VERSION "created by canmatrix"

NS_ :

BS_:

BU_:

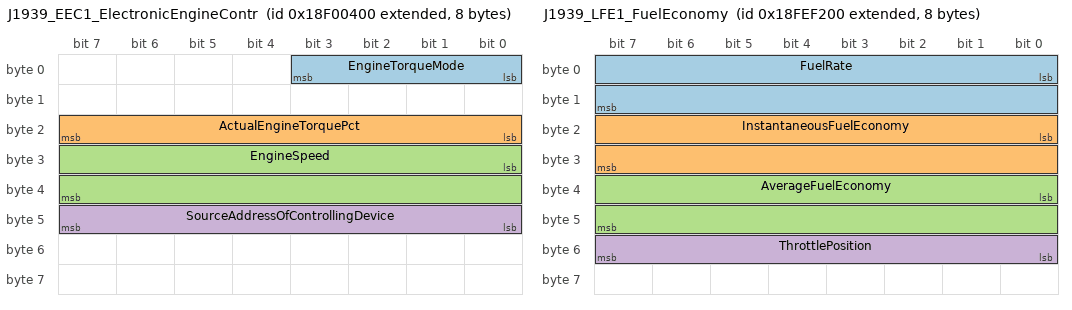
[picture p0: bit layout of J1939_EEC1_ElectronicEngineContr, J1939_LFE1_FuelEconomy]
BO_ 2565866496 J1939_EEC1_ElectronicEngineContr: 8 Vector__XXX
 SG_ EngineTorqueMode : 0|4@1+ (1,0) [0|15] "" Vector__XXX
 SG_ ActualEngineTorquePct : 16|8@1+ (1,-125) [-125|130] "%" Vector__XXX
 SG_ EngineSpeed : 24|16@1+ (0.125,0) [0|8191.875] "rpm" Vector__XXX
 SG_ SourceAddressOfControllingDevice : 40|8@1+ (1,0) [0|255] "" Vector__XXX

BO_ 2566844928 J1939_LFE1_FuelEconomy: 8 Vector__XXX
 SG_ FuelRate : 0|16@1+ (0.05,0) [0|3276.75] "L/h" Vector__XXX
 SG_ InstantaneousFuelEconomy : 16|16@1+ (0.001953,0) [0|127.989855] "km/L" Vector__XXX
 SG_ AverageFuelEconomy : 32|16@1+ (0.001953,0) [0|127.989855] "km/L" Vector__XXX
 SG_ ThrottlePosition : 48|8@1+ (0.4,0) [0|102] "%" Vector__XXX

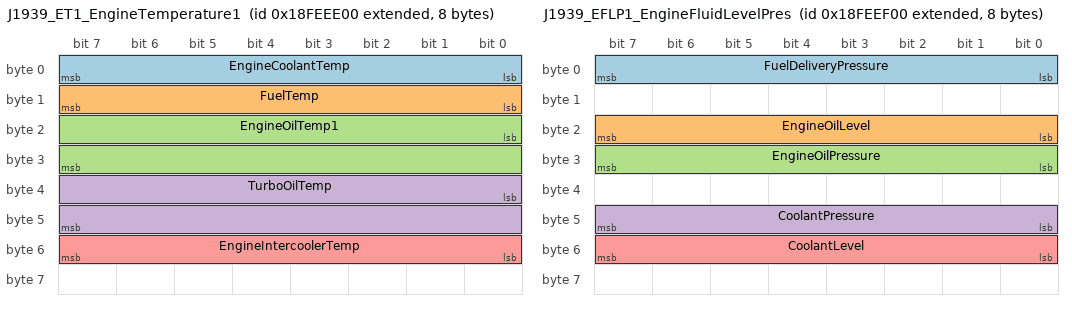
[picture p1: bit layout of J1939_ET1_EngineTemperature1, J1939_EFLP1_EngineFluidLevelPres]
BO_ 2566843904 J1939_ET1_EngineTemperature1: 8 Vector__XXX
 SG_ EngineCoolantTemp : 0|8@1+ (1,-40) [-40|215] "°C" Vector__XXX
 SG_ FuelTemp : 8|8@1+ (1,-40) [-40|215] "°C" Vector__XXX
 SG_ EngineOilTemp1 : 16|16@1+ (0.03125,-273) [-273|1774.96875] "°C" Vector__XXX
 SG_ TurboOilTemp : 32|16@1+ (0.03125,-273) [-273|1774.96875] "°C" Vector__XXX
 SG_ EngineIntercoolerTemp : 48|8@1+ (1,-40) [-40|215] "°C" Vector__XXX

BO_ 2566844160 J1939_EFLP1_EngineFluidLevelPres: 8 Vector__XXX
 SG_ FuelDeliveryPressure : 0|8@1+ (4,0) [0|1020] "kPa" Vector__XXX
 SG_ EngineOilLevel : 16|8@1+ (0.4,0) [0|102] "%" Vector__XXX
 SG_ EngineOilPressure : 24|8@1+ (4,0) [0|1020] "kPa" Vector__XXX
 SG_ CoolantPressure : 40|8@1+ (2,0) [0|510] "kPa" Vector__XXX
 SG_ CoolantLevel : 48|8@1+ (0.4,0) [0|102] "%" Vector__XXX

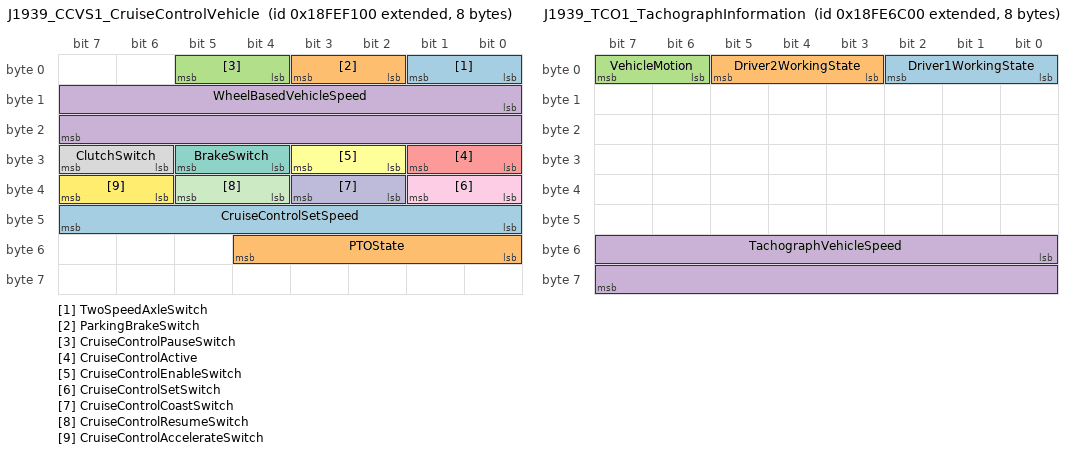
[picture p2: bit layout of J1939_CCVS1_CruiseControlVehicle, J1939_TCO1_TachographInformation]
BO_ 2566844672 J1939_CCVS1_CruiseControlVehicle: 8 Vector__XXX
 SG_ TwoSpeedAxleSwitch : 0|2@1+ (1,0) [0|3] "" Vector__XXX
 SG_ ParkingBrakeSwitch : 2|2@1+ (1,0) [0|3] "" Vector__XXX
 SG_ CruiseControlPauseSwitch : 4|2@1+ (1,0) [0|3] "" Vector__XXX
 SG_ WheelBasedVehicleSpeed : 8|16@1+ (0.003906,0) [0|255.97971] "km/h" Vector__XXX
 SG_ CruiseControlActive : 24|2@1+ (1,0) [0|3] "" Vector__XXX
 SG_ CruiseControlEnableSwitch : 26|2@1+ (1,0) [0|3] "" Vector__XXX
 SG_ BrakeSwitch : 28|2@1+ (1,0) [0|3] "" Vector__XXX
 SG_ ClutchSwitch : 30|2@1+ (1,0) [0|3] "" Vector__XXX
 SG_ CruiseControlSetSwitch : 32|2@1+ (1,0) [0|3] "" Vector__XXX
 SG_ CruiseControlCoastSwitch : 34|2@1+ (1,0) [0|3] "" Vector__XXX
 SG_ CruiseControlResumeSwitch : 36|2@1+ (1,0) [0|3] "" Vector__XXX
 SG_ CruiseControlAccelerateSwitch : 38|2@1+ (1,0) [0|3] "" Vector__XXX
 SG_ CruiseControlSetSpeed : 40|8@1+ (1,0) [0|255] "km/h" Vector__XXX
 SG_ PTOState : 48|5@1+ (1,0) [0|31] "" Vector__XXX

BO_ 2566810624 J1939_TCO1_TachographInformation: 8 Vector__XXX
 SG_ Driver1WorkingState : 0|3@1+ (1,0) [0|7] "" Vector__XXX
 SG_ Driver2WorkingState : 3|3@1+ (1,0) [0|7] "" Vector__XXX
 SG_ VehicleMotion : 6|2@1+ (1,0) [0|3] "" Vector__XXX
 SG_ TachographVehicleSpeed : 48|16@1+ (0.003906,0) [0|255.97971] "km/h" Vector__XXX

BO_ 2566841600 J1939_HOURS_EngineHours: 8 Vector__XXX
 SG_ EngineTotalHoursOfOperation : 0|32@1+ (0.05,0) [0|214748364.75] "h" Vector__XXX
 SG_ EngineTotalRevolutions : 32|32@1+ (1000,0) [0|4294967295000] "r" Vector__XXX

BO_ 2566843392 J1939_VI_VehicleIdentification: 8 Vector__XXX
 SG_ VIN_Char01 : 0|8@1+ (1,0) [0|255] "" Vector__XXX

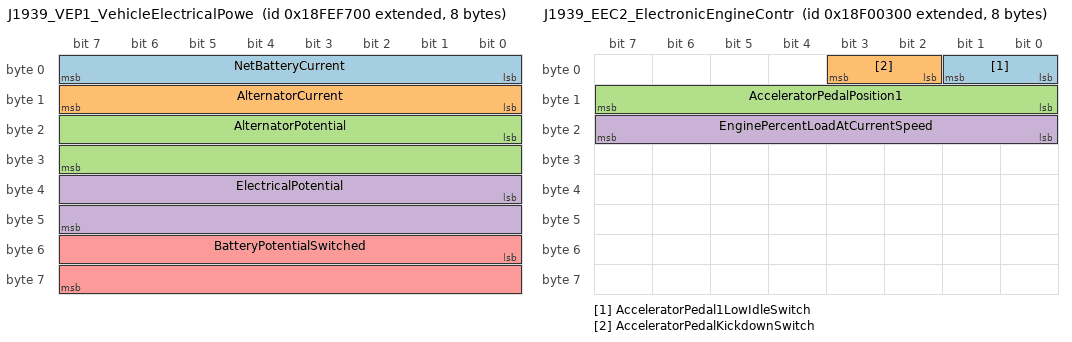
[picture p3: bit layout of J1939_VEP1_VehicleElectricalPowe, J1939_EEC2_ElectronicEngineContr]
BO_ 2566846208 J1939_VEP1_VehicleElectricalPowe: 8 Vector__XXX
 SG_ NetBatteryCurrent : 0|8@1+ (1,-125) [-125|130] "A" Vector__XXX
 SG_ AlternatorCurrent : 8|8@1+ (1,0) [0|255] "A" Vector__XXX
 SG_ AlternatorPotential : 16|16@1+ (0.05,0) [0|3276.75] "V" Vector__XXX
 SG_ ElectricalPotential : 32|16@1+ (0.05,0) [0|3276.75] "V" Vector__XXX
 SG_ BatteryPotentialSwitched : 48|16@1+ (0.05,0) [0|3276.75] "V" Vector__XXX

BO_ 2566749184 J1939_DEF_DieselExhaustFluidConc: 8 Vector__XXX
 SG_ DEFTankLevel : 0|8@1+ (0.4,0) [0|102] "%" Vector__XXX
 SG_ DEFTankTemperature : 8|8@1+ (1,-40) [-40|215] "°C" Vector__XXX

BO_ 2566841088 J1939_EC1_EngineConfiguration1: 8 Vector__XXX
 SG_ EngineSpeedAtIdle : 0|16@1+ (0.125,0) [0|8191.875] "rpm" Vector__XXX
 SG_ EngineSpeedAtMaxIdlePoint1 : 24|16@1+ (0.125,0) [0|8191.875] "rpm" Vector__XXX

BO_ 2566840064 J1939_EEC3_ElectronicEngineContr: 8 Vector__XXX
 SG_ EngineDemandPercentTorque : 56|8@1+ (1,-125) [-125|130] "%" Vector__XXX

BO_ 2565866240 J1939_EEC2_ElectronicEngineContr: 8 Vector__XXX
 SG_ AcceleratorPedal1LowIdleSwitch : 0|2@1+ (1,0) [0|3] "" Vector__XXX
 SG_ AcceleratorPedalKickdownSwitch : 2|2@1+ (1,0) [0|3] "" Vector__XXX
 SG_ AcceleratorPedalPosition1 : 8|8@1+ (0.4,0) [0|102] "%" Vector__XXX
 SG_ EnginePercentLoadAtCurrentSpeed : 16|8@1+ (1,0) [0|255] "%" Vector__XXX

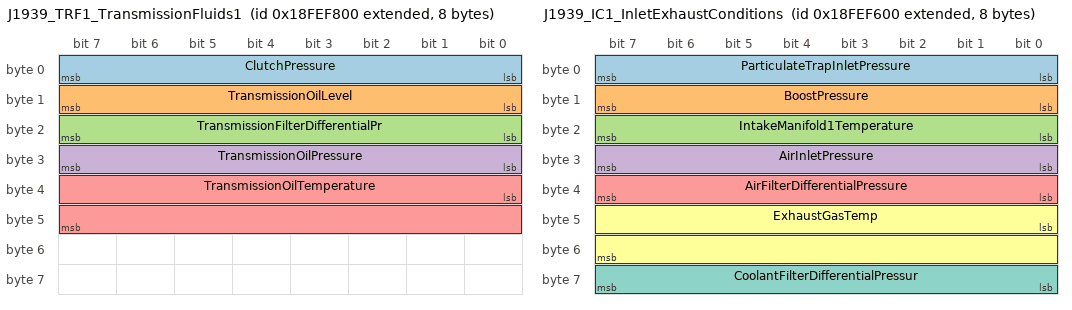
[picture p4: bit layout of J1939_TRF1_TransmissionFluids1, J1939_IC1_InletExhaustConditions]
BO_ 2566846464 J1939_TRF1_TransmissionFluids1: 8 Vector__XXX
 SG_ ClutchPressure : 0|8@1+ (16,0) [0|4080] "kPa" Vector__XXX
 SG_ TransmissionOilLevel : 8|8@1+ (0.4,0) [0|102] "%" Vector__XXX
 SG_ TransmissionFilterDifferentialPr : 16|8@1+ (2,0) [0|510] "kPa" Vector__XXX
 SG_ TransmissionOilPressure : 24|8@1+ (16,0) [0|4080] "kPa" Vector__XXX
 SG_ TransmissionOilTemperature : 32|16@1+ (0.03125,-273) [-273|1774.96875] "°C" Vector__XXX

BO_ 2566845952 J1939_IC1_InletExhaustConditions: 8 Vector__XXX
 SG_ ParticulateTrapInletPressure : 0|8@1+ (0.5,0) [0|127.5] "kPa" Vector__XXX
 SG_ BoostPressure : 8|8@1+ (2,0) [0|510] "kPa" Vector__XXX
 SG_ IntakeManifold1Temperature : 16|8@1+ (1,-40) [-40|215] "°C" Vector__XXX
 SG_ AirInletPressure : 24|8@1+ (2,0) [0|510] "kPa" Vector__XXX
 SG_ AirFilterDifferentialPressure : 32|8@1+ (0.05,0) [0|12.75] "kPa" Vector__XXX
 SG_ ExhaustGasTemp : 40|16@1+ (0.03125,-273) [-273|1774.96875] "°C" Vector__XXX
 SG_ CoolantFilterDifferentialPressur : 56|8@1+ (0.5,0) [0|127.5] "kPa" Vector__XXX

BO_ 2566697472 J1939_FFE_FuelEconomyExtended: 8 Vector__XXX
 SG_ EngineTripFuel : 0|32@1+ (0.5,0) [0|2147483647.5] "L" Vector__XXX
 SG_ EngineTotalFuelUsed : 32|32@1+ (0.5,0) [0|2147483647.5] "L" Vector__XXX

BO_ 2566832384 J1939_HRVD_HighResolutionVehicle: 8 Vector__XXX
 SG_ HighResolutionTotalVehicleDistan : 0|32@1+ (5,0) [0|21474836475] "m" Vector__XXX
 SG_ HighResolutionTripDistance : 32|32@1+ (5,0) [0|21474836475] "m" Vector__XXX

CM_ BO_ 2565866496  "Engine speed, torque mode, demand torque. Source: Wikipedia SAE J1939 PGN list (en.wikipedia.org/wiki/SAE_J1939)";
CM_ BO_ 2566844928  "Fuel rate + instantaneous + average fuel economy. Source: Wikipedia SAE J1939 PGN list (en.wikipedia.org/wiki/SAE_J1939)";
CM_ BO_ 2566843904  "Coolant + fuel + engine oil + intercooler temperatures. Source: Wikipedia SAE J1939 PGN list (en.wikipedia.org/wiki/SAE_J1939)";
CM_ BO_ 2566844160  "Oil pressure/level + coolant pressure/level + fuel delivery pressure. Source: Wikipedia SAE J1939 PGN list (en.wikipedia.org/wiki/SAE_J1939)";
CM_ BO_ 2566844672  "Vehicle speed + cruise control state + brake/clutch/parking switches. Source: Wikipedia SAE J1939 PGN list (en.wikipedia.org/wiki/SAE_J1939)";
CM_ BO_ 2566810624  "Tachograph + driver state (mostly for heavy-truck FMS). Source: Wikipedia SAE J1939 PGN list (en.wikipedia.org/wiki/SAE_J1939)";
CM_ BO_ 2566841600  "Engine total hours of operation. Source: Wikipedia SAE J1939 PGN list (en.wikipedia.org/wiki/SAE_J1939)";
CM_ BO_ 2566843392  "Vehicle Identification Number (VIN). Source: Wikipedia SAE J1939 PGN list (en.wikipedia.org/wiki/SAE_J1939)";
CM_ BO_ 2566846208  "Battery + alternator + engine starter electrical state. Source: Wikipedia SAE J1939 PGN list (en.wikipedia.org/wiki/SAE_J1939)";
CM_ BO_ 2566749184  "DEF (urea) tank level + temperature + concentration. Source: Wikipedia SAE J1939 PGN list (en.wikipedia.org/wiki/SAE_J1939)";
CM_ BO_ 2566841088  "Engine configuration data — displacement, speed limits, fuel type. Source: Wikipedia SAE J1939 PGN list (en.wikipedia.org/wiki/SAE_J1939)";
CM_ BO_ 2566840064  "Engine demand percent torque + nominal friction torque. Source: Wikipedia SAE J1939 PGN list (en.wikipedia.org/wiki/SAE_J1939)";
CM_ BO_ 2565866240  "Accelerator pedal + percent load. Source: Wikipedia SAE J1939 PGN list (en.wikipedia.org/wiki/SAE_J1939)";
CM_ BO_ 2566846464  "Transmission oil + clutch pressure. Source: Wikipedia SAE J1939 PGN list (en.wikipedia.org/wiki/SAE_J1939)";
CM_ BO_ 2566845952  "Boost + intake air temp + air filter differential pressure. Source: Wikipedia SAE J1939 PGN list (en.wikipedia.org/wiki/SAE_J1939)";
CM_ BO_ 2566697472  "Trip fuel + total fuel + trip distance. Source: Wikipedia SAE J1939 PGN list (en.wikipedia.org/wiki/SAE_J1939)";
CM_ BO_ 2566832384  "High-resolution vehicle distance (HRVD per SAE J1939-71). Source: Wikipedia SAE J1939 PGN list (en.wikipedia.org/wiki/SAE_J1939)";

CM_ SG_ 2565866496 EngineTorqueMode "Per-signal source: Wikipedia SAE J1939 PGN list (en.wikipedia.org/wiki/SAE_J1939)";
CM_ SG_ 2565866496 ActualEngineTorquePct "Actual engine percent torque";
CM_ SG_ 2565866496 EngineSpeed "Per-signal source: Wikipedia SAE J1939 PGN list (en.wikipedia.org/wiki/SAE_J1939)";
CM_ SG_ 2565866496 SourceAddressOfControllingDevice "Source address of the device commanding engine torque";
CM_ SG_ 2566844928 FuelRate "Per-signal source: Wikipedia SAE J1939 PGN list (en.wikipedia.org/wiki/SAE_J1939)";
CM_ SG_ 2566844928 InstantaneousFuelEconomy "Per-signal source: Wikipedia SAE J1939 PGN list (en.wikipedia.org/wiki/SAE_J1939)";
CM_ SG_ 2566844928 AverageFuelEconomy "Per-signal source: Wikipedia SAE J1939 PGN list (en.wikipedia.org/wiki/SAE_J1939)";
CM_ SG_ 2566844928 ThrottlePosition "Per-signal source: Wikipedia SAE J1939 PGN list (en.wikipedia.org/wiki/SAE_J1939)";
CM_ SG_ 2566843904 EngineCoolantTemp "Per-signal source: Wikipedia SAE J1939 PGN list (en.wikipedia.org/wiki/SAE_J1939)";
CM_ SG_ 2566843904 FuelTemp "Per-signal source: Wikipedia SAE J1939 PGN list (en.wikipedia.org/wiki/SAE_J1939)";
CM_ SG_ 2566843904 EngineOilTemp1 "Per-signal source: Wikipedia SAE J1939 PGN list (en.wikipedia.org/wiki/SAE_J1939)";
CM_ SG_ 2566843904 TurboOilTemp "Per-signal source: Wikipedia SAE J1939 PGN list (en.wikipedia.org/wiki/SAE_J1939)";
CM_ SG_ 2566843904 EngineIntercoolerTemp "Per-signal source: Wikipedia SAE J1939 PGN list (en.wikipedia.org/wiki/SAE_J1939)";
CM_ SG_ 2566844160 FuelDeliveryPressure "Per-signal source: Wikipedia SAE J1939 PGN list (en.wikipedia.org/wiki/SAE_J1939)";
CM_ SG_ 2566844160 EngineOilLevel "Per-signal source: Wikipedia SAE J1939 PGN list (en.wikipedia.org/wiki/SAE_J1939)";
CM_ SG_ 2566844160 EngineOilPressure "Per-signal source: Wikipedia SAE J1939 PGN list (en.wikipedia.org/wiki/SAE_J1939)";
CM_ SG_ 2566844160 CoolantPressure "Per-signal source: Wikipedia SAE J1939 PGN list (en.wikipedia.org/wiki/SAE_J1939)";
CM_ SG_ 2566844160 CoolantLevel "Per-signal source: Wikipedia SAE J1939 PGN list (en.wikipedia.org/wiki/SAE_J1939)";
CM_ SG_ 2566844672 TwoSpeedAxleSwitch "Per-signal source: Wikipedia SAE J1939 PGN list (en.wikipedia.org/wiki/SAE_J1939)";
CM_ SG_ 2566844672 ParkingBrakeSwitch "Per-signal source: Wikipedia SAE J1939 PGN list (en.wikipedia.org/wiki/SAE_J1939)";
CM_ SG_ 2566844672 CruiseControlPauseSwitch "Per-signal source: Wikipedia SAE J1939 PGN list (en.wikipedia.org/wiki/SAE_J1939)";
CM_ SG_ 2566844672 WheelBasedVehicleSpeed "Per-signal source: Wikipedia SAE J1939 PGN list (en.wikipedia.org/wiki/SAE_J1939)";
CM_ SG_ 2566844672 CruiseControlActive "Per-signal source: Wikipedia SAE J1939 PGN list (en.wikipedia.org/wiki/SAE_J1939)";
CM_ SG_ 2566844672 CruiseControlEnableSwitch "Per-signal source: Wikipedia SAE J1939 PGN list (en.wikipedia.org/wiki/SAE_J1939)";
CM_ SG_ 2566844672 BrakeSwitch "Per-signal source: Wikipedia SAE J1939 PGN list (en.wikipedia.org/wiki/SAE_J1939)";
CM_ SG_ 2566844672 ClutchSwitch "Per-signal source: Wikipedia SAE J1939 PGN list (en.wikipedia.org/wiki/SAE_J1939)";
CM_ SG_ 2566844672 CruiseControlSetSwitch "Per-signal source: Wikipedia SAE J1939 PGN list (en.wikipedia.org/wiki/SAE_J1939)";
CM_ SG_ 2566844672 CruiseControlCoastSwitch "Per-signal source: Wikipedia SAE J1939 PGN list (en.wikipedia.org/wiki/SAE_J1939)";
CM_ SG_ 2566844672 CruiseControlResumeSwitch "Per-signal source: Wikipedia SAE J1939 PGN list (en.wikipedia.org/wiki/SAE_J1939)";
CM_ SG_ 2566844672 CruiseControlAccelerateSwitch "Per-signal source: Wikipedia SAE J1939 PGN list (en.wikipedia.org/wiki/SAE_J1939)";
CM_ SG_ 2566844672 CruiseControlSetSpeed "Per-signal source: Wikipedia SAE J1939 PGN list (en.wikipedia.org/wiki/SAE_J1939)";
CM_ SG_ 2566844672 PTOState "Per-signal source: Wikipedia SAE J1939 PGN list (en.wikipedia.org/wiki/SAE_J1939)";
CM_ SG_ 2566810624 Driver1WorkingState "Per-signal source: Wikipedia SAE J1939 PGN list (en.wikipedia.org/wiki/SAE_J1939)";
CM_ SG_ 2566810624 Driver2WorkingState "Per-signal source: Wikipedia SAE J1939 PGN list (en.wikipedia.org/wiki/SAE_J1939)";
CM_ SG_ 2566810624 VehicleMotion "Per-signal source: Wikipedia SAE J1939 PGN list (en.wikipedia.org/wiki/SAE_J1939)";
CM_ SG_ 2566810624 TachographVehicleSpeed "Per-signal source: Wikipedia SAE J1939 PGN list (en.wikipedia.org/wiki/SAE_J1939)";
CM_ SG_ 2566841600 EngineTotalHoursOfOperation "Per-signal source: Wikipedia SAE J1939 PGN list (en.wikipedia.org/wiki/SAE_J1939)";
CM_ SG_ 2566841600 EngineTotalRevolutions "Per-signal source: Wikipedia SAE J1939 PGN list (en.wikipedia.org/wiki/SAE_J1939)";
CM_ SG_ 2566843392 VIN_Char01 "ASCII byte 0 of VIN; full VIN spans multipacket";
CM_ SG_ 2566846208 NetBatteryCurrent "Per-signal source: Wikipedia SAE J1939 PGN list (en.wikipedia.org/wiki/SAE_J1939)";
CM_ SG_ 2566846208 AlternatorCurrent "Per-signal source: Wikipedia SAE J1939 PGN list (en.wikipedia.org/wiki/SAE_J1939)";
CM_ SG_ 2566846208 AlternatorPotential "Per-signal source: Wikipedia SAE J1939 PGN list (en.wikipedia.org/wiki/SAE_J1939)";
CM_ SG_ 2566846208 ElectricalPotential "Per-signal source: Wikipedia SAE J1939 PGN list (en.wikipedia.org/wiki/SAE_J1939)";
CM_ SG_ 2566846208 BatteryPotentialSwitched "Per-signal source: Wikipedia SAE J1939 PGN list (en.wikipedia.org/wiki/SAE_J1939)";
CM_ SG_ 2566749184 DEFTankLevel "Per-signal source: Wikipedia SAE J1939 PGN list (en.wikipedia.org/wiki/SAE_J1939)";
CM_ SG_ 2566749184 DEFTankTemperature "Per-signal source: Wikipedia SAE J1939 PGN list (en.wikipedia.org/wiki/SAE_J1939)";
CM_ SG_ 2566841088 EngineSpeedAtIdle "Per-signal source: Wikipedia SAE J1939 PGN list (en.wikipedia.org/wiki/SAE_J1939)";
CM_ SG_ 2566841088 EngineSpeedAtMaxIdlePoint1 "Per-signal source: Wikipedia SAE J1939 PGN list (en.wikipedia.org/wiki/SAE_J1939)";
CM_ SG_ 2566840064 EngineDemandPercentTorque "Per-signal source: Wikipedia SAE J1939 PGN list (en.wikipedia.org/wiki/SAE_J1939)";
CM_ SG_ 2565866240 AcceleratorPedal1LowIdleSwitch "Per-signal source: Wikipedia SAE J1939 PGN list (en.wikipedia.org/wiki/SAE_J1939)";
CM_ SG_ 2565866240 AcceleratorPedalKickdownSwitch "Per-signal source: Wikipedia SAE J1939 PGN list (en.wikipedia.org/wiki/SAE_J1939)";
CM_ SG_ 2565866240 AcceleratorPedalPosition1 "Per-signal source: Wikipedia SAE J1939 PGN list (en.wikipedia.org/wiki/SAE_J1939)";
CM_ SG_ 2565866240 EnginePercentLoadAtCurrentSpeed "Per-signal source: Wikipedia SAE J1939 PGN list (en.wikipedia.org/wiki/SAE_J1939)";
CM_ SG_ 2566846464 ClutchPressure "Per-signal source: Wikipedia SAE J1939 PGN list (en.wikipedia.org/wiki/SAE_J1939)";
CM_ SG_ 2566846464 TransmissionOilLevel "Per-signal source: Wikipedia SAE J1939 PGN list (en.wikipedia.org/wiki/SAE_J1939)";
CM_ SG_ 2566846464 TransmissionFilterDifferentialPr "Per-signal source: Wikipedia SAE J1939 PGN list (en.wikipedia.org/wiki/SAE_J1939)";
CM_ SG_ 2566846464 TransmissionOilPressure "Per-signal source: Wikipedia SAE J1939 PGN list (en.wikipedia.org/wiki/SAE_J1939)";
CM_ SG_ 2566846464 TransmissionOilTemperature "Per-signal source: Wikipedia SAE J1939 PGN list (en.wikipedia.org/wiki/SAE_J1939)";
CM_ SG_ 2566845952 ParticulateTrapInletPressure "Per-signal source: Wikipedia SAE J1939 PGN list (en.wikipedia.org/wiki/SAE_J1939)";
CM_ SG_ 2566845952 BoostPressure "Per-signal source: Wikipedia SAE J1939 PGN list (en.wikipedia.org/wiki/SAE_J1939)";
CM_ SG_ 2566845952 IntakeManifold1Temperature "Per-signal source: Wikipedia SAE J1939 PGN list (en.wikipedia.org/wiki/SAE_J1939)";
CM_ SG_ 2566845952 AirInletPressure "Per-signal source: Wikipedia SAE J1939 PGN list (en.wikipedia.org/wiki/SAE_J1939)";
CM_ SG_ 2566845952 AirFilterDifferentialPressure "Per-signal source: Wikipedia SAE J1939 PGN list (en.wikipedia.org/wiki/SAE_J1939)";
CM_ SG_ 2566845952 ExhaustGasTemp "Per-signal source: Wikipedia SAE J1939 PGN list (en.wikipedia.org/wiki/SAE_J1939)";
CM_ SG_ 2566845952 CoolantFilterDifferentialPressur "Per-signal source: Wikipedia SAE J1939 PGN list (en.wikipedia.org/wiki/SAE_J1939)";
CM_ SG_ 2566697472 EngineTripFuel "Per-signal source: Wikipedia SAE J1939 PGN list (en.wikipedia.org/wiki/SAE_J1939)";
CM_ SG_ 2566697472 EngineTotalFuelUsed "Per-signal source: Wikipedia SAE J1939 PGN list (en.wikipedia.org/wiki/SAE_J1939)";
CM_ SG_ 2566832384 HighResolutionTotalVehicleDistan "Per-signal source: Wikipedia SAE J1939 PGN list (en.wikipedia.org/wiki/SAE_J1939)";
CM_ SG_ 2566832384 HighResolutionTripDistance "Per-signal source: Wikipedia SAE J1939 PGN list (en.wikipedia.org/wiki/SAE_J1939)";

BA_DEF_ BO_ "SystemMessageLongSymbol" STRING;
BA_DEF_ SG_ "GenSigStartValue" FLOAT 0 100000000000;
BA_DEF_ SG_ "SystemSignalLongSymbol" STRING;

BA_ "SystemMessageLongSymbol" BO_ 2565866496 "J1939_EEC1_ElectronicEngineController1";
BA_ "SystemMessageLongSymbol" BO_ 2566844160 "J1939_EFLP1_EngineFluidLevelPressure1";
BA_ "SystemMessageLongSymbol" BO_ 2566844672 "J1939_CCVS1_CruiseControlVehicleSpeed1";
BA_ "SystemMessageLongSymbol" BO_ 2566846208 "J1939_VEP1_VehicleElectricalPower1";
BA_ "SystemMessageLongSymbol" BO_ 2566749184 "J1939_DEF_DieselExhaustFluidConcentration";
BA_ "SystemMessageLongSymbol" BO_ 2566840064 "J1939_EEC3_ElectronicEngineController3";
BA_ "SystemMessageLongSymbol" BO_ 2565866240 "J1939_EEC2_ElectronicEngineController2";
BA_ "SystemMessageLongSymbol" BO_ 2566845952 "J1939_IC1_InletExhaustConditions1";
BA_ "SystemMessageLongSymbol" BO_ 2566832384 "J1939_HRVD_HighResolutionVehicleDistance";

VAL_ 2565866496 EngineTorqueMode 0 "LowIdleGovernor" 1 "AcceleratorPedal" 2 "CruiseControl" 3 "PTOGovernor" 4 "RoadSpeedGovernor" 5 "ASRControl" 6 "TransmissionControl" 7 "ABSControl" 8 "TorqueLimiting" 9 "HighSpeedGovernor" 10 "BrakingSystem" 11 "RemoteAccelerator" 14 "Other" 15 "NotAvailable";

VERSION "created by canmatrix"

NS_ :

BS_:

BU_:

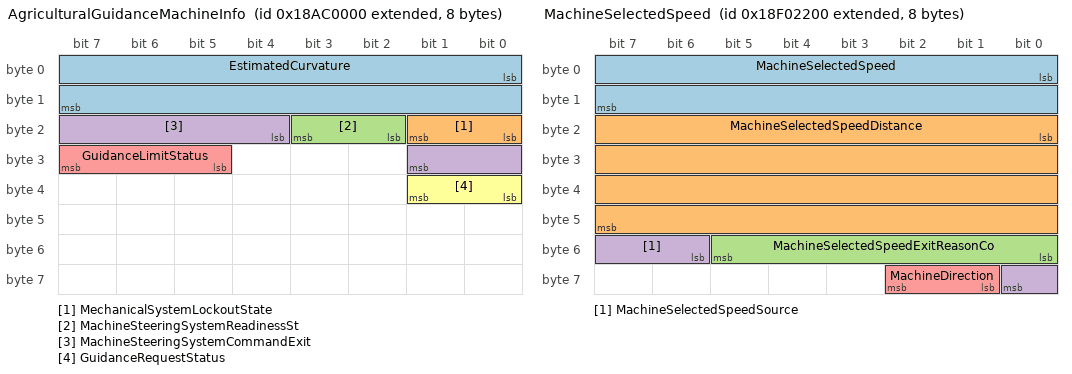
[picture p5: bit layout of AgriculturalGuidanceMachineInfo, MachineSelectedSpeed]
BO_ 2561409024 AgriculturalGuidanceMachineInfo: 8 Vector__XXX
 SG_ EstimatedCurvature : 0|16@1+ (0.25,-8032) [-8032|8351.75] "1/km" Vector__XXX
 SG_ MechanicalSystemLockoutState : 16|2@1+ (1,0) [0|3] "" Vector__XXX
 SG_ MachineSteeringSystemReadinessSt : 18|2@1+ (1,0) [0|3] "" Vector__XXX
 SG_ MachineSteeringSystemCommandExit : 20|6@1+ (1,0) [0|63] "" Vector__XXX
 SG_ GuidanceLimitStatus : 29|3@1+ (1,0) [0|7] "" Vector__XXX
 SG_ GuidanceRequestStatus : 32|2@1+ (1,0) [0|3] "" Vector__XXX

BO_ 2561474560 AgriculturalGuidanceSystemComman: 8 Vector__XXX
 SG_ CurvatureCommand : 0|16@1+ (0.25,-8032) [-8032|8351.75] "1/km" Vector__XXX
 SG_ CurvatureCommandStatus : 16|2@1+ (1,0) [0|3] "" Vector__XXX

BO_ 2562916352 DiagnosticMessage22: 8 Vector__XXX
 SG_ DiagnosticMessage22_RawPayload : 0|64@1+ (1,0) [0|18446744073709551615] "" Vector__XXX

BO_ 2563178496 ExtendedTransportProtocolDataTra: 8 Vector__XXX
 SG_ ExtendedTransportProtocolDataTra : 0|64@1+ (1,0) [0|18446744073709551615] "" Vector__XXX

BO_ 2563244032 ExtendedTransportProtocolConnect: 8 Vector__XXX
 SG_ ExtendedTransportProtocolConnect : 0|64@1+ (1,0) [0|18446744073709551615] "" Vector__XXX

BO_ 2563440640 ProcessData: 8 Vector__XXX
 SG_ ProcessData_RawPayload : 0|64@1+ (1,0) [0|18446744073709551615] "" Vector__XXX

BO_ 2563506176 RequestForRepetitionRate: 8 Vector__XXX
 SG_ RequestForRepetitionRate_RawPayl : 0|64@1+ (1,0) [0|18446744073709551615] "" Vector__XXX

BO_ 2564751360 DiagnosticMessage13: 8 Vector__XXX
 SG_ DiagnosticMessage13_RawPayload : 0|64@1+ (1,0) [0|18446744073709551615] "" Vector__XXX

BO_ 2565210112 VirtualTerminalToECU: 8 Vector__XXX
 SG_ VirtualTerminalToECU_RawPayload : 0|64@1+ (1,0) [0|18446744073709551615] "" Vector__XXX

BO_ 2565275648 ECUtoVirtualTerminal: 8 Vector__XXX
 SG_ ECUtoVirtualTerminal_RawPayload : 0|64@1+ (1,0) [0|18446744073709551615] "" Vector__XXX

BO_ 2565341184 Acknowledge: 8 Vector__XXX
 SG_ Acknowledge_RawPayload : 0|64@1+ (1,0) [0|18446744073709551615] "" Vector__XXX

BO_ 2565472256 ParameterGroupNumberRequest: 8 Vector__XXX
 SG_ ParameterGroupNumberRequest_RawP : 0|64@1+ (1,0) [0|18446744073709551615] "" Vector__XXX

BO_ 2565537792 TransportProtocolDataTransfer: 8 Vector__XXX
 SG_ TransportProtocolDataTransfer_Ra : 0|64@1+ (1,0) [0|18446744073709551615] "" Vector__XXX

BO_ 2565603328 TransportProtocolConnectionManag: 8 Vector__XXX
 SG_ TransportProtocolConnectionManag : 0|64@1+ (1,0) [0|18446744073709551615] "" Vector__XXX

BO_ 2565734400 AddressClaim: 8 Vector__XXX
 SG_ AddressClaim_RawPayload : 0|64@1+ (1,0) [0|18446744073709551615] "" Vector__XXX

BO_ 2565874176 MachineSelectedSpeed: 8 Vector__XXX
 SG_ MachineSelectedSpeed : 0|16@1+ (0.001,0) [0|65.535] "m/s" Vector__XXX
 SG_ MachineSelectedSpeedDistance : 16|32@1+ (1,0) [0|4294967295] "m" Vector__XXX
 SG_ MachineSelectedSpeedExitReasonCo : 48|6@1+ (1,0) [0|63] "" Vector__XXX
 SG_ MachineSelectedSpeedSource : 54|3@1+ (1,0) [0|7] "" Vector__XXX
 SG_ MachineDirection : 57|2@1+ (1,0) [0|3] "" Vector__XXX

BO_ 2565923840 HeartbeatMessage: 8 Vector__XXX
 SG_ HeartbeatSequenceCounter : 0|8@1+ (1,0) [0|255] "" Vector__XXX

BO_ 2566688000 ProductIdentification: 8 Vector__XXX
 SG_ ProductIdentification_RawPayload : 0|64@1+ (1,0) [0|18446744073709551615] "" Vector__XXX

BO_ 2566688256 ControlFunctionFunctionalities: 8 Vector__XXX
 SG_ ControlFunctionFunctionalities_R : 0|64@1+ (1,0) [0|18446744073709551615] "" Vector__XXX

BO_ 2566730240 DiagnosticProtocolIdentification: 8 Vector__XXX
 SG_ DiagnosticProtocolIdentification : 0|64@1+ (1,0) [0|18446744073709551615] "" Vector__XXX

BO_ 2566734592 MachineSelectedSpeedCommand: 8 Vector__XXX
 SG_ MachineSelectedSpeedCommand_RawP : 0|64@1+ (1,0) [0|18446744073709551615] "" Vector__XXX

BO_ 2566786304 WorkingSetMaster: 8 Vector__XXX
 SG_ WorkingSetMaster_RawPayload : 0|64@1+ (1,0) [0|18446744073709551615] "" Vector__XXX

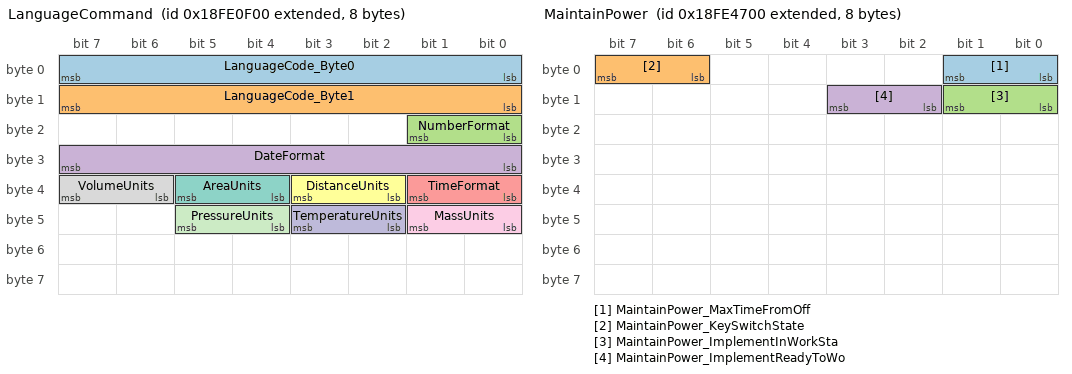
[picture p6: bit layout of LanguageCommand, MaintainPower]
BO_ 2566786816 LanguageCommand: 8 Vector__XXX
 SG_ LanguageCode_Byte0 : 0|8@1+ (1,0) [0|255] "" Vector__XXX
 SG_ LanguageCode_Byte1 : 8|8@1+ (1,0) [0|255] "" Vector__XXX
 SG_ NumberFormat : 16|2@1+ (1,0) [0|3] "" Vector__XXX
 SG_ DateFormat : 24|8@1+ (1,0) [0|255] "" Vector__XXX
 SG_ TimeFormat : 32|2@1+ (1,0) [0|3] "" Vector__XXX
 SG_ DistanceUnits : 34|2@1+ (1,0) [0|3] "" Vector__XXX
 SG_ AreaUnits : 36|2@1+ (1,0) [0|3] "" Vector__XXX
 SG_ VolumeUnits : 38|2@1+ (1,0) [0|3] "" Vector__XXX
 SG_ MassUnits : 40|2@1+ (1,0) [0|3] "" Vector__XXX
 SG_ TemperatureUnits : 42|2@1+ (1,0) [0|3] "" Vector__XXX
 SG_ PressureUnits : 44|2@1+ (1,0) [0|3] "" Vector__XXX

BO_ 2566801152 MaintainPower: 8 Vector__XXX
 SG_ MaintainPower_MaxTimeFromOff : 0|2@1+ (1,0) [0|3] "" Vector__XXX
 SG_ MaintainPower_KeySwitchState : 6|2@1+ (1,0) [0|3] "" Vector__XXX
 SG_ MaintainPower_ImplementInWorkSta : 8|2@1+ (1,0) [0|3] "" Vector__XXX
 SG_ MaintainPower_ImplementReadyToWo : 10|2@1+ (1,0) [0|3] "" Vector__XXX

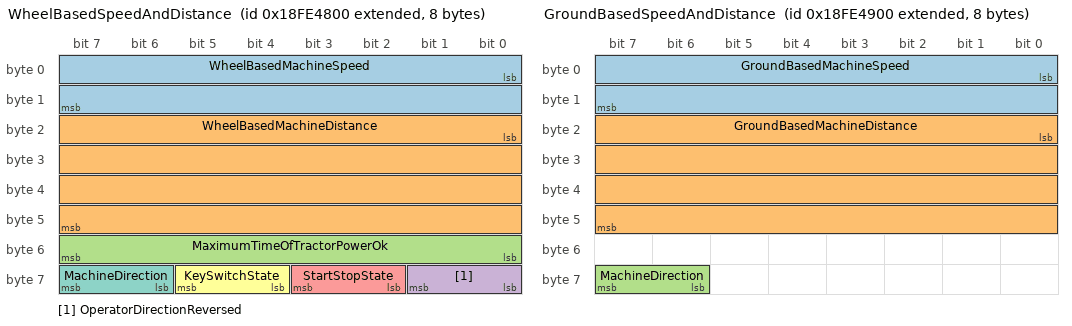
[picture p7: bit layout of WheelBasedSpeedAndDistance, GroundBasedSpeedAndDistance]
BO_ 2566801408 WheelBasedSpeedAndDistance: 8 Vector__XXX
 SG_ WheelBasedMachineSpeed : 0|16@1+ (0.001,0) [0|65.535] "m/s" Vector__XXX
 SG_ WheelBasedMachineDistance : 16|32@1+ (1,0) [0|4294967295] "m" Vector__XXX
 SG_ MaximumTimeOfTractorPowerOk : 48|8@1+ (1,0) [0|255] "minutes" Vector__XXX
 SG_ OperatorDirectionReversed : 56|2@1+ (1,0) [0|3] "" Vector__XXX
 SG_ StartStopState : 58|2@1+ (1,0) [0|3] "" Vector__XXX
 SG_ KeySwitchState : 60|2@1+ (1,0) [0|3] "" Vector__XXX
 SG_ MachineDirection : 62|2@1+ (1,0) [0|3] "" Vector__XXX

BO_ 2566801664 GroundBasedSpeedAndDistance: 8 Vector__XXX
 SG_ GroundBasedMachineSpeed : 0|16@1+ (0.001,0) [0|65.535] "m/s" Vector__XXX
 SG_ GroundBasedMachineDistance : 16|32@1+ (1,0) [0|4294967295] "m" Vector__XXX
 SG_ MachineDirection : 62|2@1+ (1,0) [0|3] "" Vector__XXX

BO_ 2566767872 ECUIdentificationInformation: 8 Vector__XXX
 SG_ ECUIdentificationInformation_Raw : 0|64@1+ (1,0) [0|18446744073709551615] "" Vector__XXX

BO_ 2566834688 DiagnosticMessage1: 8 Vector__XXX
 SG_ DiagnosticMessage1_RawPayload : 0|64@1+ (1,0) [0|18446744073709551615] "" Vector__XXX

BO_ 2566834944 DiagnosticMessage2: 8 Vector__XXX
 SG_ DiagnosticMessage2_RawPayload : 0|64@1+ (1,0) [0|18446744073709551615] "" Vector__XXX

BO_ 2566835200 DiagnosticMessage3: 8 Vector__XXX
 SG_ DiagnosticMessage3_RawPayload : 0|64@1+ (1,0) [0|18446744073709551615] "" Vector__XXX

BO_ 2566836992 DiagnosticMessage11: 8 Vector__XXX
 SG_ DiagnosticMessage11_RawPayload : 0|64@1+ (1,0) [0|18446744073709551615] "" Vector__XXX

BO_ 2564358144 DiagnosticMessage14: 8 Vector__XXX
 SG_ DiagnosticMessage14_RawPayload : 0|64@1+ (1,0) [0|18446744073709551615] "" Vector__XXX

BO_ 2564292608 DiagnosticMessage15: 8 Vector__XXX
 SG_ DiagnosticMessage15_RawPayload : 0|64@1+ (1,0) [0|18446744073709551615] "" Vector__XXX

BO_ 2564227072 DiagnosticMessage16: 8 Vector__XXX
 SG_ DiagnosticMessage16_RawPayload : 0|64@1+ (1,0) [0|18446744073709551615] "" Vector__XXX

BO_ 2566838272 CommandedAddress: 8 Vector__XXX
 SG_ CommandedAddress_RawPayload : 0|64@1+ (1,0) [0|18446744073709551615] "" Vector__XXX

BO_ 2566838784 SoftwareIdentification: 8 Vector__XXX
 SG_ SoftwareIdentification_RawPayloa : 0|64@1+ (1,0) [0|18446744073709551615] "" Vector__XXX

BO_ 2566717952 AllImplementsStopOperationsSwitc: 8 Vector__XXX
 SG_ AllImplementsStopOperationsSwitc : 0|64@1+ (1,0) [0|18446744073709551615] "" Vector__XXX

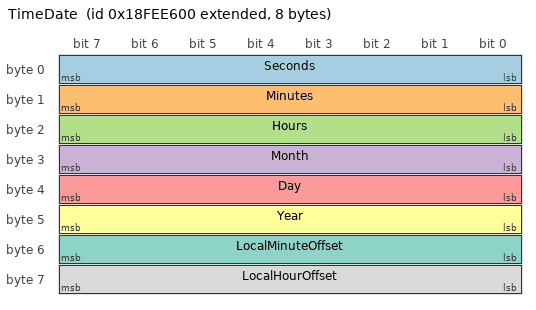
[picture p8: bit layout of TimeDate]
BO_ 2566841856 TimeDate: 8 Vector__XXX
 SG_ Seconds : 0|8@1+ (0.25,0) [0|63.75] "s" Vector__XXX
 SG_ Minutes : 8|8@1+ (1,0) [0|255] "min" Vector__XXX
 SG_ Hours : 16|8@1+ (1,0) [0|255] "h" Vector__XXX
 SG_ Month : 24|8@1+ (1,0) [0|255] "month" Vector__XXX
 SG_ Day : 32|8@1+ (0.25,0) [0|63.75] "day" Vector__XXX
 SG_ Year : 40|8@1+ (1,1985) [1985|2240] "year" Vector__XXX
 SG_ LocalMinuteOffset : 48|8@1+ (1,-125) [-125|130] "min" Vector__XXX
 SG_ LocalHourOffset : 56|8@1+ (1,-125) [-125|130] "h" Vector__XXX

BO_ 2566843136 ComponentIdentification: 8 Vector__XXX
 SG_ ComponentIdentification_RawPaylo : 0|64@1+ (1,0) [0|18446744073709551615] "" Vector__XXX

BO_ 2582712832 VesselHeading: 8 Vector__XXX
 SG_ VesselHeading_RawPayload : 0|64@1+ (1,0) [0|18446744073709551615] "" Vector__XXX

BO_ 2582713088 RateOfTurn: 8 Vector__XXX
 SG_ RateOfTurn_RawPayload : 0|64@1+ (1,0) [0|18446744073709551615] "" Vector__XXX

BO_ 2583167232 PositionRapidUpdate: 8 Vector__XXX
 SG_ PositionRapidUpdate_RawPayload : 0|64@1+ (1,0) [0|18446744073709551615] "" Vector__XXX

BO_ 2583167488 CourseOverGroundSpeedOverGroundR: 8 Vector__XXX
 SG_ CourseOverGroundSpeedOverGroundR : 0|64@1+ (1,0) [0|18446744073709551615] "" Vector__XXX

BO_ 2583167744 PositionDeltaHighPrecisionRapidU: 8 Vector__XXX
 SG_ PositionDeltaHighPrecisionRapidU : 0|64@1+ (1,0) [0|18446744073709551615] "" Vector__XXX

BO_ 2583168256 GNSSPositionData: 8 Vector__XXX
 SG_ GNSSPositionData_RawPayload : 0|64@1+ (1,0) [0|18446744073709551615] "" Vector__XXX

BO_ 2583172096 Datum: 8 Vector__XXX
 SG_ Datum_RawPayload : 0|64@1+ (1,0) [0|18446744073709551615] "" Vector__XXX

CM_ BO_ 2561409024  "Source: AgIsoStack++ can_general_parameter_group_numbers.hpp:19";
CM_ BO_ 2561474560  "Source: AgIsoStack++ can_general_parameter_group_numbers.hpp:20";
CM_ BO_ 2562916352  "Source: AgIsoStack++ can_general_parameter_group_numbers.hpp:21";
CM_ BO_ 2563178496  "Source: AgIsoStack++ can_general_parameter_group_numbers.hpp:22";
CM_ BO_ 2563244032  "Source: AgIsoStack++ can_general_parameter_group_numbers.hpp:23";
CM_ BO_ 2563440640  "Source: AgIsoStack++ can_general_parameter_group_numbers.hpp:24";
CM_ BO_ 2563506176  "Source: AgIsoStack++ can_general_parameter_group_numbers.hpp:25";
CM_ BO_ 2564751360  "Source: AgIsoStack++ can_general_parameter_group_numbers.hpp:26";
CM_ BO_ 2565210112  "Source: AgIsoStack++ can_general_parameter_group_numbers.hpp:27";
CM_ BO_ 2565275648  "Source: AgIsoStack++ can_general_parameter_group_numbers.hpp:28";
CM_ BO_ 2565341184  "Source: AgIsoStack++ can_general_parameter_group_numbers.hpp:29";
CM_ BO_ 2565472256  "Source: AgIsoStack++ can_general_parameter_group_numbers.hpp:30";
CM_ BO_ 2565537792  "Source: AgIsoStack++ can_general_parameter_group_numbers.hpp:31";
CM_ BO_ 2565603328  "Source: AgIsoStack++ can_general_parameter_group_numbers.hpp:32";
CM_ BO_ 2565734400  "Source: AgIsoStack++ can_general_parameter_group_numbers.hpp:33";
CM_ BO_ 2565874176  "Source: AgIsoStack++ can_general_parameter_group_numbers.hpp:35";
CM_ BO_ 2565923840  "Source: AgIsoStack++ can_general_parameter_group_numbers.hpp:36";
CM_ BO_ 2566688000  "Source: AgIsoStack++ can_general_parameter_group_numbers.hpp:37";
CM_ BO_ 2566688256  "Source: AgIsoStack++ can_general_parameter_group_numbers.hpp:38";
CM_ BO_ 2566730240  "Source: AgIsoStack++ can_general_parameter_group_numbers.hpp:39";
CM_ BO_ 2566734592  "Source: AgIsoStack++ can_general_parameter_group_numbers.hpp:40";
CM_ BO_ 2566786304  "Source: AgIsoStack++ can_general_parameter_group_numbers.hpp:41";
CM_ BO_ 2566786816  "Source: AgIsoStack++ can_general_parameter_group_numbers.hpp:42";
CM_ BO_ 2566801152  "Source: AgIsoStack++ can_general_parameter_group_numbers.hpp:43";
CM_ BO_ 2566801408  "Source: AgIsoStack++ can_general_parameter_group_numbers.hpp:44";
CM_ BO_ 2566801664  "Source: AgIsoStack++ can_general_parameter_group_numbers.hpp:45";
CM_ BO_ 2566767872  "Source: AgIsoStack++ can_general_parameter_group_numbers.hpp:46";
CM_ BO_ 2566834688  "Source: AgIsoStack++ can_general_parameter_group_numbers.hpp:47. DM1 carries Active Diagnostic Trouble Codes per SAE J1939-73. Payload layout (multi-DTC, variable length): byte 0 = lamp status (MIL / Red Stop / Amber Warning / Protect, 2 bits each); byte 1 = flash status for those 4 lamps; bytes 2+ = repeating 4-byte DTC records (SPN 19-bit + FMI 5-bit + OC 7-bit + CM 1-bit). Per-DTC decoding is reader-side; this DBC documents only the frame-level definition. Public reference: CSS Electronics J1939-73 explainer (csselectronics.com). Full decode contribution welcome — see CONTRIBUTING.md.";
CM_ BO_ 2566834944  "Source: AgIsoStack++ can_general_parameter_group_numbers.hpp:48";
CM_ BO_ 2566835200  "Source: AgIsoStack++ can_general_parameter_group_numbers.hpp:49";
CM_ BO_ 2566836992  "Source: AgIsoStack++ can_general_parameter_group_numbers.hpp:50";
CM_ BO_ 2564358144  "Source: AgIsoStack++ can_general_parameter_group_numbers.hpp:51";
CM_ BO_ 2564292608  "Source: AgIsoStack++ can_general_parameter_group_numbers.hpp:52";
CM_ BO_ 2564227072  "Source: AgIsoStack++ can_general_parameter_group_numbers.hpp:53";
CM_ BO_ 2566838272  "Source: AgIsoStack++ can_general_parameter_group_numbers.hpp:54";
CM_ BO_ 2566838784  "Source: AgIsoStack++ can_general_parameter_group_numbers.hpp:55";
CM_ BO_ 2566717952  "Source: AgIsoStack++ can_general_parameter_group_numbers.hpp:56";
CM_ BO_ 2566841856  "Source: AgIsoStack++ can_general_parameter_group_numbers.hpp:57";
CM_ BO_ 2566843136  "Source: AgIsoStack++ can_general_parameter_group_numbers.hpp:58";
CM_ BO_ 2582712832  "Source: AgIsoStack++ can_general_parameter_group_numbers.hpp:59 Note: this is an NMEA 2000 marine PGN. AgIsoStack++ reuses these for GNSS/heading because NMEA 2000 and ISO 11783 share the J1939 protocol layer; they are not part of ISO 11783-7 itself.";
CM_ BO_ 2582713088  "Source: AgIsoStack++ can_general_parameter_group_numbers.hpp:60 Note: this is an NMEA 2000 marine PGN. AgIsoStack++ reuses these for GNSS/heading because NMEA 2000 and ISO 11783 share the J1939 protocol layer; they are not part of ISO 11783-7 itself.";
CM_ BO_ 2583167232  "Source: AgIsoStack++ can_general_parameter_group_numbers.hpp:61 Note: this is an NMEA 2000 marine PGN. AgIsoStack++ reuses these for GNSS/heading because NMEA 2000 and ISO 11783 share the J1939 protocol layer; they are not part of ISO 11783-7 itself.";
CM_ BO_ 2583167488  "Source: AgIsoStack++ can_general_parameter_group_numbers.hpp:62";
CM_ BO_ 2583167744  "Source: AgIsoStack++ can_general_parameter_group_numbers.hpp:63";
CM_ BO_ 2583168256  "Source: AgIsoStack++ can_general_parameter_group_numbers.hpp:64 Note: this is an NMEA 2000 marine PGN. AgIsoStack++ reuses these for GNSS/heading because NMEA 2000 and ISO 11783 share the J1939 protocol layer; they are not part of ISO 11783-7 itself.";
CM_ BO_ 2583172096  "Source: AgIsoStack++ can_general_parameter_group_numbers.hpp:65 Note: this is an NMEA 2000 marine PGN. AgIsoStack++ reuses these for GNSS/heading because NMEA 2000 and ISO 11783 share the J1939 protocol layer; they are not part of ISO 11783-7 itself.";

CM_ SG_ 2561409024 EstimatedCurvature "Source: isobus_guidance_interface.hpp GuidanceMachineInfo";
CM_ SG_ 2561409024 MachineSteeringSystemCommandExit "Per ISO 11783-7 exit reason codes";
CM_ SG_ 2561474560 CurvatureCommand "Source: isobus_guidance_interface.hpp GuidanceSystemCommand";
CM_ SG_ 2562916352 DiagnosticMessage22_RawPayload "Generic 8-byte raw payload. Signal-level decoding requires ISO 11783-X spec lookup or AgIsoStack++ parser inspection  manual enrichment via PR welcome.";
CM_ SG_ 2563178496 ExtendedTransportProtocolDataTra "Generic 8-byte raw payload. Signal-level decoding requires ISO 11783-X spec lookup or AgIsoStack++ parser inspection  manual enrichment via PR welcome.";
CM_ SG_ 2563244032 ExtendedTransportProtocolConnect "Generic 8-byte raw payload. Signal-level decoding requires ISO 11783-X spec lookup or AgIsoStack++ parser inspection  manual enrichment via PR welcome.";
CM_ SG_ 2563440640 ProcessData_RawPayload "Generic 8-byte raw payload. Signal-level decoding requires ISO 11783-X spec lookup or AgIsoStack++ parser inspection  manual enrichment via PR welcome.";
CM_ SG_ 2563506176 RequestForRepetitionRate_RawPayl "Generic 8-byte raw payload. Signal-level decoding requires ISO 11783-X spec lookup or AgIsoStack++ parser inspection  manual enrichment via PR welcome.";
CM_ SG_ 2564751360 DiagnosticMessage13_RawPayload "Generic 8-byte raw payload. Signal-level decoding requires ISO 11783-X spec lookup or AgIsoStack++ parser inspection  manual enrichment via PR welcome.";
CM_ SG_ 2565210112 VirtualTerminalToECU_RawPayload "Generic 8-byte raw payload. Signal-level decoding requires ISO 11783-X spec lookup or AgIsoStack++ parser inspection  manual enrichment via PR welcome.";
CM_ SG_ 2565275648 ECUtoVirtualTerminal_RawPayload "Generic 8-byte raw payload. Signal-level decoding requires ISO 11783-X spec lookup or AgIsoStack++ parser inspection  manual enrichment via PR welcome.";
CM_ SG_ 2565341184 Acknowledge_RawPayload "Generic 8-byte raw payload. Signal-level decoding requires ISO 11783-X spec lookup or AgIsoStack++ parser inspection  manual enrichment via PR welcome.";
CM_ SG_ 2565472256 ParameterGroupNumberRequest_RawP "Generic 8-byte raw payload. Signal-level decoding requires ISO 11783-X spec lookup or AgIsoStack++ parser inspection  manual enrichment via PR welcome.";
CM_ SG_ 2565537792 TransportProtocolDataTransfer_Ra "Generic 8-byte raw payload. Signal-level decoding requires ISO 11783-X spec lookup or AgIsoStack++ parser inspection  manual enrichment via PR welcome.";
CM_ SG_ 2565603328 TransportProtocolConnectionManag "Generic 8-byte raw payload. Signal-level decoding requires ISO 11783-X spec lookup or AgIsoStack++ parser inspection  manual enrichment via PR welcome.";
CM_ SG_ 2565734400 AddressClaim_RawPayload "Generic 8-byte raw payload. Signal-level decoding requires ISO 11783-X spec lookup or AgIsoStack++ parser inspection  manual enrichment via PR welcome.";
CM_ SG_ 2565874176 MachineSelectedSpeed "Source: isobus_speed_distance_messages.hpp MachineSelectedSpeedData";
CM_ SG_ 2565874176 MachineSelectedSpeedExitReasonCo "Source-of-selected-speed exit reason code per ISO 11783-7";
CM_ SG_ 2565874176 MachineSelectedSpeedSource "0=Wheel 1=Ground 2=Navigation 3=Blended 4=Simulated";
CM_ SG_ 2565923840 HeartbeatSequenceCounter "Increments 0..250 then wraps; per isobus_heartbeat.hpp";
CM_ SG_ 2566688000 ProductIdentification_RawPayload "Generic 8-byte raw payload. Signal-level decoding requires ISO 11783-X spec lookup or AgIsoStack++ parser inspection  manual enrichment via PR welcome.";
CM_ SG_ 2566688256 ControlFunctionFunctionalities_R "Generic 8-byte raw payload. Signal-level decoding requires ISO 11783-X spec lookup or AgIsoStack++ parser inspection  manual enrichment via PR welcome.";
CM_ SG_ 2566730240 DiagnosticProtocolIdentification "Generic 8-byte raw payload. Signal-level decoding requires ISO 11783-X spec lookup or AgIsoStack++ parser inspection  manual enrichment via PR welcome.";
CM_ SG_ 2566734592 MachineSelectedSpeedCommand_RawP "Generic 8-byte raw payload. Signal-level decoding requires ISO 11783-X spec lookup or AgIsoStack++ parser inspection  manual enrichment via PR welcome.";
CM_ SG_ 2566786304 WorkingSetMaster_RawPayload "Generic 8-byte raw payload. Signal-level decoding requires ISO 11783-X spec lookup or AgIsoStack++ parser inspection  manual enrichment via PR welcome.";
CM_ SG_ 2566786816 LanguageCode_Byte0 "ASCII char 1 of ISO 639-1 language code, e.g. 'e' for en";
CM_ SG_ 2566786816 LanguageCode_Byte1 "ASCII char 2";
CM_ SG_ 2566786816 NumberFormat "Decimal separator + grouping convention";
CM_ SG_ 2566786816 DateFormat "0=ddmmyyyy 1=ddyyyymm 2=mmyyyydd 3=mmddyyyy 4=yyyymmdd 5=yyyyddmm";
CM_ SG_ 2566786816 TimeFormat "0=24h 1=12h";
CM_ SG_ 2566786816 DistanceUnits "0=metric 1=imperial-US 2=imperial-UK 3=reserved";
CM_ SG_ 2566801152 MaintainPower_MaxTimeFromOff "MaintainPower request  maximum time for ECU power-down";
CM_ SG_ 2566801408 WheelBasedMachineSpeed "Source: isobus_speed_distance_messages.hpp WheelBasedMachineSpeedData";
CM_ SG_ 2566801408 WheelBasedMachineDistance "Source: isobus_speed_distance_messages.hpp";
CM_ SG_ 2566801408 MaximumTimeOfTractorPowerOk "Source: isobus_speed_distance_messages.hpp";
CM_ SG_ 2566801408 OperatorDirectionReversed "0=NotReversed 1=Reversed 2=Error 3=NotAvailable";
CM_ SG_ 2566801408 StartStopState "0=Stop 1=Start 2=Error 3=NotAvailable";
CM_ SG_ 2566801408 KeySwitchState "0=Off 1=NotOff 2=Error 3=NotAvailable";
CM_ SG_ 2566801408 MachineDirection "0=Reverse 1=Forward 2=Error 3=NotAvailable";
CM_ SG_ 2566801664 GroundBasedMachineSpeed "Source: isobus_speed_distance_messages.hpp GroundBasedSpeedAndDistance";
CM_ SG_ 2566801664 GroundBasedMachineDistance "Source: isobus_speed_distance_messages.hpp";
CM_ SG_ 2566801664 MachineDirection "0=Reverse 1=Forward 2=Error 3=NotAvailable";
CM_ SG_ 2566767872 ECUIdentificationInformation_Raw "Generic 8-byte raw payload. Signal-level decoding requires ISO 11783-X spec lookup or AgIsoStack++ parser inspection  manual enrichment via PR welcome.";
CM_ SG_ 2566834688 DiagnosticMessage1_RawPayload "Generic 8-byte raw payload. Signal-level decoding requires ISO 11783-X spec lookup or AgIsoStack++ parser inspection  manual enrichment via PR welcome.";
CM_ SG_ 2566834944 DiagnosticMessage2_RawPayload "Generic 8-byte raw payload. Signal-level decoding requires ISO 11783-X spec lookup or AgIsoStack++ parser inspection  manual enrichment via PR welcome.";
CM_ SG_ 2566835200 DiagnosticMessage3_RawPayload "Generic 8-byte raw payload. Signal-level decoding requires ISO 11783-X spec lookup or AgIsoStack++ parser inspection  manual enrichment via PR welcome.";
CM_ SG_ 2566836992 DiagnosticMessage11_RawPayload "Generic 8-byte raw payload. Signal-level decoding requires ISO 11783-X spec lookup or AgIsoStack++ parser inspection  manual enrichment via PR welcome.";
CM_ SG_ 2564358144 DiagnosticMessage14_RawPayload "Generic 8-byte raw payload. Signal-level decoding requires ISO 11783-X spec lookup or AgIsoStack++ parser inspection  manual enrichment via PR welcome.";
CM_ SG_ 2564292608 DiagnosticMessage15_RawPayload "Generic 8-byte raw payload. Signal-level decoding requires ISO 11783-X spec lookup or AgIsoStack++ parser inspection  manual enrichment via PR welcome.";
CM_ SG_ 2564227072 DiagnosticMessage16_RawPayload "Generic 8-byte raw payload. Signal-level decoding requires ISO 11783-X spec lookup or AgIsoStack++ parser inspection  manual enrichment via PR welcome.";
CM_ SG_ 2566838272 CommandedAddress_RawPayload "Generic 8-byte raw payload. Signal-level decoding requires ISO 11783-X spec lookup or AgIsoStack++ parser inspection  manual enrichment via PR welcome.";
CM_ SG_ 2566838784 SoftwareIdentification_RawPayloa "Generic 8-byte raw payload. Signal-level decoding requires ISO 11783-X spec lookup or AgIsoStack++ parser inspection  manual enrichment via PR welcome.";
CM_ SG_ 2566717952 AllImplementsStopOperationsSwitc "Generic 8-byte raw payload. Signal-level decoding requires ISO 11783-X spec lookup or AgIsoStack++ parser inspection  manual enrichment via PR welcome.";
CM_ SG_ 2566843136 ComponentIdentification_RawPaylo "Generic 8-byte raw payload. Signal-level decoding requires ISO 11783-X spec lookup or AgIsoStack++ parser inspection  manual enrichment via PR welcome.";
CM_ SG_ 2582712832 VesselHeading_RawPayload "Generic 8-byte raw payload. Signal-level decoding requires ISO 11783-X spec lookup or AgIsoStack++ parser inspection  manual enrichment via PR welcome.";
CM_ SG_ 2582713088 RateOfTurn_RawPayload "Generic 8-byte raw payload. Signal-level decoding requires ISO 11783-X spec lookup or AgIsoStack++ parser inspection  manual enrichment via PR welcome.";
CM_ SG_ 2583167232 PositionRapidUpdate_RawPayload "Generic 8-byte raw payload. Signal-level decoding requires ISO 11783-X spec lookup or AgIsoStack++ parser inspection  manual enrichment via PR welcome.";
CM_ SG_ 2583167488 CourseOverGroundSpeedOverGroundR "Generic 8-byte raw payload. Signal-level decoding requires ISO 11783-X spec lookup or AgIsoStack++ parser inspection  manual enrichment via PR welcome.";
CM_ SG_ 2583167744 PositionDeltaHighPrecisionRapidU "Generic 8-byte raw payload. Signal-level decoding requires ISO 11783-X spec lookup or AgIsoStack++ parser inspection  manual enrichment via PR welcome.";
CM_ SG_ 2583168256 GNSSPositionData_RawPayload "Generic 8-byte raw payload. Signal-level decoding requires ISO 11783-X spec lookup or AgIsoStack++ parser inspection  manual enrichment via PR welcome.";
CM_ SG_ 2583172096 Datum_RawPayload "Generic 8-byte raw payload. Signal-level decoding requires ISO 11783-X spec lookup or AgIsoStack++ parser inspection  manual enrichment via PR welcome.";

BA_DEF_ BO_ "SystemMessageLongSymbol" STRING;
BA_DEF_ SG_ "GenSigStartValue" FLOAT 0 100000000000;
BA_DEF_ SG_ "SystemSignalLongSymbol" STRING;

BA_ "SystemMessageLongSymbol" BO_ 2561474560 "AgriculturalGuidanceSystemCommand";
BA_ "SystemMessageLongSymbol" BO_ 2563178496 "ExtendedTransportProtocolDataTransfer";
BA_ "SystemMessageLongSymbol" BO_ 2563244032 "ExtendedTransportProtocolConnectionManagement";
BA_ "SystemMessageLongSymbol" BO_ 2565603328 "TransportProtocolConnectionManagement";
BA_ "SystemMessageLongSymbol" BO_ 2566717952 "AllImplementsStopOperationsSwitchState";
BA_ "SystemMessageLongSymbol" BO_ 2583167488 "CourseOverGroundSpeedOverGroundRapidUpdate";
BA_ "SystemMessageLongSymbol" BO_ 2583167744 "PositionDeltaHighPrecisionRapidUpdate";

VAL_ 2561409024 MechanicalSystemLockoutState 0 "NotActive" 1 "Active" 2 "Error" 3 "NotAvailable";
VAL_ 2561409024 MachineSteeringSystemReadinessSt 0 "NotReady" 1 "Ready" 2 "Error" 3 "NotAvailable";
VAL_ 2561409024 GuidanceLimitStatus 0 "NotLimited" 1 "OperatorLimited" 2 "LimitedHigh" 3 "LimitedLow";
VAL_ 2561409024 GuidanceRequestStatus 0 "RequiredNoSteer" 1 "Required" 2 "Error" 3 "NotAvailable";
VAL_ 2561474560 CurvatureCommandStatus 0 "IntendedNotSteering" 1 "IntendedSteering" 2 "Error" 3 "NotAvailable";
VAL_ 2565874176 MachineSelectedSpeedSource 0 "Wheel" 1 "Ground" 2 "Navigation" 3 "Blended" 4 "Simulated";
VAL_ 2565874176 MachineDirection 0 "Reverse" 1 "Forward" 2 "Error" 3 "NotAvailable";
VAL_ 2566801152 MaintainPower_MaxTimeFromOff 0 "DoNotMaintain" 1 "Maintain2Sec" 2 "MaintainExt" 3 "NotAvailable";
VAL_ 2566801152 MaintainPower_KeySwitchState 0 "Off" 1 "NotOff" 2 "Error" 3 "NotAvailable";
VAL_ 2566801152 MaintainPower_ImplementInWorkSta 0 "NotInWork" 1 "InWork" 2 "Error" 3 "NotAvailable";
VAL_ 2566801152 MaintainPower_ImplementReadyToWo 0 "NotReady" 1 "Ready" 2 "Error" 3 "NotAvailable";
VAL_ 2566801408 OperatorDirectionReversed 0 "NotReversed" 1 "Reversed" 2 "Error" 3 "NotAvailable";
VAL_ 2566801408 StartStopState 0 "Stop" 1 "Start" 2 "Error" 3 "NotAvailable";
VAL_ 2566801408 KeySwitchState 0 "Off" 1 "NotOff" 2 "Error" 3 "NotAvailable";
VAL_ 2566801408 MachineDirection 0 "Reverse" 1 "Forward" 2 "Error" 3 "NotAvailable";
VAL_ 2566801664 MachineDirection 0 "Reverse" 1 "Forward" 2 "Error" 3 "NotAvailable";

VERSION "created by canmatrix"

NS_ :

BS_:

BU_:

BO_ 2550202368 VDMA_100_Transmission_Control_1: 8 Vector__XXX
 SG_ Transmission_Control_1_RawPayloa : 0|64@1+ (1,0) [0|18446744073709551615] "" Vector__XXX

BO_ 2550267904 VDMA_200_Electronic_Brake_System: 8 Vector__XXX
 SG_ Electronic_Brake_System_1_1_RawP : 0|64@1+ (1,0) [0|18446744073709551615] "" Vector__XXX

BO_ 2550333440 VDMA_300_Electronic_Brake_System: 8 Vector__XXX
 SG_ Electronic_Brake_System_2_1_RawP : 0|64@1+ (1,0) [0|18446744073709551615] "" Vector__XXX

BO_ 2550398976 VDMA_400_External_Brake_Request: 8 Vector__XXX
 SG_ External_Brake_Request_RawPayloa : 0|64@1+ (1,0) [0|18446744073709551615] "" Vector__XXX

BO_ 2550464512 VDMA_500_CANopen_Application_Mes: 8 Vector__XXX
 SG_ CANopen_Application_Message_1_1_ : 0|64@1+ (1,0) [0|18446744073709551615] "" Vector__XXX

BO_ 2550530048 VDMA_600_CANopen_Application_Mes: 8 Vector__XXX
 SG_ CANopen_Application_Message_2_1_ : 0|64@1+ (1,0) [0|18446744073709551615] "" Vector__XXX

BO_ 2550595584 VDMA_700_General_Purpose_Valve_P: 8 Vector__XXX
 SG_ General_Purpose_Valve_Pressure_R : 0|64@1+ (1,0) [0|18446744073709551615] "" Vector__XXX

BO_ 2550661120 VDMA_800_Auxiliary_Input_Output_: 8 Vector__XXX
 SG_ Auxiliary_Input_Output_Status_5_ : 0|64@1+ (1,0) [0|18446744073709551615] "" Vector__XXX

BO_ 2550726656 VDMA_900_Static_Roll_Angle_Senso: 8 Vector__XXX
 SG_ Static_Roll_Angle_Sensor_Informa : 0|64@1+ (1,0) [0|18446744073709551615] "" Vector__XXX

BO_ 2550792192 VDMA_A00_Cruise_Control_Vehicle_: 8 Vector__XXX
 SG_ Cruise_Control_Vehicle_Speed_2_R : 0|64@1+ (1,0) [0|18446744073709551615] "" Vector__XXX

BO_ 2550857728 VDMA_B00_Advanced_Emergency_Brak: 8 Vector__XXX
 SG_ Advanced_Emergency_Braking_Syste : 0|64@1+ (1,0) [0|18446744073709551615] "" Vector__XXX

BO_ 2550923264 VDMA_C00_Electronic_Engine_Contr: 8 Vector__XXX
 SG_ Electronic_Engine_Controller_16_ : 0|64@1+ (1,0) [0|18446744073709551615] "" Vector__XXX

BO_ 2550988800 VDMA_D00_Transmission_Control_2: 8 Vector__XXX
 SG_ Transmission_Control_2_RawPayloa : 0|64@1+ (1,0) [0|18446744073709551615] "" Vector__XXX

BO_ 2551054336 VDMA_E00_Safety_Header_Message: 8 Vector__XXX
 SG_ Safety_Header_Message_RawPayload : 0|64@1+ (1,0) [0|18446744073709551615] "" Vector__XXX

BO_ 2551119872 VDMA_F00_High_Voltage_Energy_Sto: 8 Vector__XXX
 SG_ High_Voltage_Energy_Storage_Pack : 0|64@1+ (1,0) [0|18446744073709551615] "" Vector__XXX

BO_ 2551185408 VDMA_1000_High_Voltage_Energy_St: 8 Vector__XXX
 SG_ High_Voltage_Energy_Storage_Pack : 0|64@1+ (1,0) [0|18446744073709551615] "" Vector__XXX

BO_ 2551250944 VDMA_1100_High_Voltage_Energy_St: 8 Vector__XXX
 SG_ High_Voltage_Energy_Storage_Pack : 0|64@1+ (1,0) [0|18446744073709551615] "" Vector__XXX

BO_ 2551316480 VDMA_1200_High_Voltage_Energy_St: 8 Vector__XXX
 SG_ High_Voltage_Energy_Storage_Pack : 0|64@1+ (1,0) [0|18446744073709551615] "" Vector__XXX

BO_ 2551382016 VDMA_1300_High_Voltage_Energy_St: 8 Vector__XXX
 SG_ High_Voltage_Energy_Storage_Pack : 0|64@1+ (1,0) [0|18446744073709551615] "" Vector__XXX

BO_ 2551447552 VDMA_1400_High_Voltage_Energy_St: 8 Vector__XXX
 SG_ High_Voltage_Energy_Storage_Pack : 0|64@1+ (1,0) [0|18446744073709551615] "" Vector__XXX

BO_ 2551513088 VDMA_1500_High_Voltage_Energy_St: 8 Vector__XXX
 SG_ High_Voltage_Energy_Storage_Pack : 0|64@1+ (1,0) [0|18446744073709551615] "" Vector__XXX

BO_ 2551578624 VDMA_1600_High_Voltage_Energy_St: 8 Vector__XXX
 SG_ High_Voltage_Energy_Storage_Pack : 0|64@1+ (1,0) [0|18446744073709551615] "" Vector__XXX

BO_ 2551644160 VDMA_1700_High_Voltage_Energy_St: 8 Vector__XXX
 SG_ High_Voltage_Energy_Storage_Pack : 0|64@1+ (1,0) [0|18446744073709551615] "" Vector__XXX

BO_ 2551709696 VDMA_1800_High_Voltage_Energy_St: 8 Vector__XXX
 SG_ High_Voltage_Energy_Storage_Pack : 0|64@1+ (1,0) [0|18446744073709551615] "" Vector__XXX

BO_ 2551775232 VDMA_1900_High_Voltage_Energy_St: 8 Vector__XXX
 SG_ High_Voltage_Energy_Storage_Pack : 0|64@1+ (1,0) [0|18446744073709551615] "" Vector__XXX

BO_ 2551840768 VDMA_1A00_High_Voltage_Energy_St: 8 Vector__XXX
 SG_ High_Voltage_Energy_Storage_Pack : 0|64@1+ (1,0) [0|18446744073709551615] "" Vector__XXX

BO_ 2551906304 VDMA_1B00_High_Voltage_Energy_St: 8 Vector__XXX
 SG_ High_Voltage_Energy_Storage_Syst : 0|64@1+ (1,0) [0|18446744073709551615] "" Vector__XXX

BO_ 2551971840 VDMA_1C00_Transmission_Control_3: 8 Vector__XXX
 SG_ Transmission_Control_3_Obsolete_ : 0|64@1+ (1,0) [0|18446744073709551615] "" Vector__XXX

BO_ 2552037376 VDMA_1D00_Engine_Ignition_Contro: 8 Vector__XXX
 SG_ Engine_Ignition_Controller_RawPa : 0|64@1+ (1,0) [0|18446744073709551615] "" Vector__XXX

BO_ 2552102912 VDMA_1E00_Alternator_Control: 8 Vector__XXX
 SG_ Alternator_Control_RawPayload : 0|64@1+ (1,0) [0|18446744073709551615] "" Vector__XXX

BO_ 2552168448 VDMA_1F00_High_Voltage_Energy_St: 8 Vector__XXX
 SG_ High_Voltage_Energy_Storage_Pack : 0|64@1+ (1,0) [0|18446744073709551615] "" Vector__XXX

BO_ 2552233984 VDMA_2000_High_Voltage_Energy_St: 8 Vector__XXX
 SG_ High_Voltage_Energy_Storage_Pack : 0|64@1+ (1,0) [0|18446744073709551615] "" Vector__XXX

BO_ 2552299520 VDMA_2100_High_Voltage_Energy_St: 8 Vector__XXX
 SG_ High_Voltage_Energy_Storage_Pack : 0|64@1+ (1,0) [0|18446744073709551615] "" Vector__XXX

BO_ 2552365056 VDMA_2200_High_Voltage_Energy_St: 8 Vector__XXX
 SG_ High_Voltage_Energy_Storage_Pack : 0|64@1+ (1,0) [0|18446744073709551615] "" Vector__XXX

BO_ 2552430592 VDMA_2300_Tractor_Implement_Mana: 8 Vector__XXX
 SG_ Tractor_Implement_Management_TIM : 0|64@1+ (1,0) [0|18446744073709551615] "" Vector__XXX

BO_ 2552496128 VDMA_2400_Tractor_Implement_Mana: 8 Vector__XXX
 SG_ Tractor_Implement_Management_TIM : 0|64@1+ (1,0) [0|18446744073709551615] "" Vector__XXX

BO_ 2552561664 VDMA_2500_Multi_PG: 8 Vector__XXX
 SG_ Multi_PG_RawPayload : 0|64@1+ (1,0) [0|18446744073709551615] "" Vector__XXX

BO_ 2552627200 VDMA_2600_Motor_Generator_1_Inve: 8 Vector__XXX
 SG_ Motor_Generator_1_Inverter_Contr : 0|64@1+ (1,0) [0|18446744073709551615] "" Vector__XXX

BO_ 2552692736 VDMA_2700_Motor_Generator_2_Inve: 8 Vector__XXX
 SG_ Motor_Generator_2_Inverter_Contr : 0|64@1+ (1,0) [0|18446744073709551615] "" Vector__XXX

BO_ 2552758272 VDMA_2800_Motor_Generator_1_Inve: 8 Vector__XXX
 SG_ Motor_Generator_1_Inverter_Rate_ : 0|64@1+ (1,0) [0|18446744073709551615] "" Vector__XXX

BO_ 2552823808 VDMA_2900_Motor_Generator_2_Inve: 8 Vector__XXX
 SG_ Motor_Generator_2_Inverter_Rate_ : 0|64@1+ (1,0) [0|18446744073709551615] "" Vector__XXX

BO_ 2552889344 VDMA_2A00_High_Voltage_Energy_St: 8 Vector__XXX
 SG_ High_Voltage_Energy_Storage_Pack : 0|64@1+ (1,0) [0|18446744073709551615] "" Vector__XXX

BO_ 2552954880 VDMA_2B00_High_Voltage_Energy_St: 8 Vector__XXX
 SG_ High_Voltage_Energy_Storage_Pack : 0|64@1+ (1,0) [0|18446744073709551615] "" Vector__XXX

BO_ 2553020416 VDMA_2C00_High_Voltage_Energy_St: 8 Vector__XXX
 SG_ High_Voltage_Energy_Storage_Pack : 0|64@1+ (1,0) [0|18446744073709551615] "" Vector__XXX

BO_ 2553085952 VDMA_2D00_High_Voltage_Energy_St: 8 Vector__XXX
 SG_ High_Voltage_Energy_Storage_Pack : 0|64@1+ (1,0) [0|18446744073709551615] "" Vector__XXX

BO_ 2553151488 VDMA_2E00_High_Voltage_Energy_St: 8 Vector__XXX
 SG_ High_Voltage_Energy_Storage_Pack : 0|64@1+ (1,0) [0|18446744073709551615] "" Vector__XXX

BO_ 2553217024 VDMA_2F00_High_Voltage_Energy_St: 8 Vector__XXX
 SG_ High_Voltage_Energy_Storage_Pack : 0|64@1+ (1,0) [0|18446744073709551615] "" Vector__XXX

BO_ 2553282560 VDMA_3000_High_Voltage_Energy_St: 8 Vector__XXX
 SG_ High_Voltage_Energy_Storage_Pack : 0|64@1+ (1,0) [0|18446744073709551615] "" Vector__XXX

BO_ 2553348096 VDMA_3100_High_Voltage_Energy_St: 8 Vector__XXX
 SG_ High_Voltage_Energy_Storage_Pack : 0|64@1+ (1,0) [0|18446744073709551615] "" Vector__XXX

BO_ 2553413632 VDMA_3200_High_Voltage_Energy_St: 8 Vector__XXX
 SG_ High_Voltage_Energy_Storage_Pack : 0|64@1+ (1,0) [0|18446744073709551615] "" Vector__XXX

BO_ 2553479168 VDMA_3300_High_Voltage_Energy_St: 8 Vector__XXX
 SG_ High_Voltage_Energy_Storage_Pack : 0|64@1+ (1,0) [0|18446744073709551615] "" Vector__XXX

BO_ 2553544704 VDMA_3400_Reliable_Long_Message: 8 Vector__XXX
 SG_ Reliable_Long_Message_RawPayload : 0|64@1+ (1,0) [0|18446744073709551615] "" Vector__XXX

BO_ 2553610240 VDMA_3500_Reliable_Short_Message: 8 Vector__XXX
 SG_ Reliable_Short_Message_RawPayloa : 0|64@1+ (1,0) [0|18446744073709551615] "" Vector__XXX

BO_ 2553675776 VDMA_3600_Unreliable_Message: 8 Vector__XXX
 SG_ Unreliable_Message_RawPayload : 0|64@1+ (1,0) [0|18446744073709551615] "" Vector__XXX

BO_ 2553741312 VDMA_3700_Message_Acknowledgemen: 8 Vector__XXX
 SG_ Message_Acknowledgement_RawPaylo : 0|64@1+ (1,0) [0|18446744073709551615] "" Vector__XXX

BO_ 2553806848 VDMA_3800_Version_Negotiation_Se: 8 Vector__XXX
 SG_ Version_Negotiation_Section_RawP : 0|64@1+ (1,0) [0|18446744073709551615] "" Vector__XXX

BO_ 2553872384 VDMA_3900_External_ACC_Accelerat: 8 Vector__XXX
 SG_ External_ACC_Acceleration_Reques : 0|64@1+ (1,0) [0|18446744073709551615] "" Vector__XXX

BO_ 2553937920 VDMA_3A00_Battery_Charger_1_Comm: 8 Vector__XXX
 SG_ Battery_Charger_1_Command_1_RawP : 0|64@1+ (1,0) [0|18446744073709551615] "" Vector__XXX

BO_ 2554003456 VDMA_3B00_Battery_Charger_2_Comm: 8 Vector__XXX
 SG_ Battery_Charger_2_Command_1_RawP : 0|64@1+ (1,0) [0|18446744073709551615] "" Vector__XXX

BO_ 2554068992 VDMA_3C00_Tractor_Implement_Mana: 8 Vector__XXX
 SG_ Tractor_Implement_Management_TIM : 0|64@1+ (1,0) [0|18446744073709551615] "" Vector__XXX

BO_ 2554134528 VDMA_3D00_Tractor_Implement_Mana: 8 Vector__XXX
 SG_ Tractor_Implement_Management_TIM : 0|64@1+ (1,0) [0|18446744073709551615] "" Vector__XXX

BO_ 2554200064 VDMA_3E00_Fuel_Cell_System_Contr: 8 Vector__XXX
 SG_ Fuel_Cell_System_Control_Command : 0|64@1+ (1,0) [0|18446744073709551615] "" Vector__XXX

BO_ 2554265600 VDMA_3F00_Fuel_Cell_System_Power: 8 Vector__XXX
 SG_ Fuel_Cell_System_Power_Limit_Com : 0|64@1+ (1,0) [0|18446744073709551615] "" Vector__XXX

BO_ 2554331136 VDMA_4000_Fuel_Cell_System_Curre: 8 Vector__XXX
 SG_ Fuel_Cell_System_Current_Limit_C : 0|64@1+ (1,0) [0|18446744073709551615] "" Vector__XXX

BO_ 2554396672 VDMA_4100_Hydrogen_Storage_Syste: 8 Vector__XXX
 SG_ Hydrogen_Storage_System_Control_ : 0|64@1+ (1,0) [0|18446744073709551615] "" Vector__XXX

BO_ 2554462208 VDMA_4200_Transmission_Control_4: 8 Vector__XXX
 SG_ Transmission_Control_4_RawPayloa : 0|64@1+ (1,0) [0|18446744073709551615] "" Vector__XXX

BO_ 2554527744 VDMA_4300_Safety_Header_Message_: 8 Vector__XXX
 SG_ Safety_Header_Message_2_RawPaylo : 0|64@1+ (1,0) [0|18446744073709551615] "" Vector__XXX

BO_ 2554724352 VDMA_4600_API_Select: 8 Vector__XXX
 SG_ API_Select_RawPayload : 0|64@1+ (1,0) [0|18446744073709551615] "" Vector__XXX

BO_ 2554855424 VDMA_4800_Tractor_Implement_Mana: 8 Vector__XXX
 SG_ Tractor_Implement_Management_TIM : 0|64@1+ (1,0) [0|18446744073709551615] "" Vector__XXX

BO_ 2554920960 VDMA_4900_Tractor_Implement_Mana: 8 Vector__XXX
 SG_ Tractor_Implement_Management_TIM : 0|64@1+ (1,0) [0|18446744073709551615] "" Vector__XXX

BO_ 2554986496 VDMA_4A00_EV_Multi_Connection_DC: 8 Vector__XXX
 SG_ EV_Multi_Connection_DC_Status_1_ : 0|64@1+ (1,0) [0|18446744073709551615] "" Vector__XXX

BO_ 2555052032 VDMA_4B00_EV_Multi_Connection_DC: 8 Vector__XXX
 SG_ EV_Multi_Connection_DC_Charging_ : 0|64@1+ (1,0) [0|18446744073709551615] "" Vector__XXX

BO_ 2555117568 VDMA_4C00_Electrified_Accessory_: 8 Vector__XXX
 SG_ Electrified_Accessory_Engine_Coo : 0|64@1+ (1,0) [0|18446744073709551615] "" Vector__XXX

BO_ 2555183104 VDMA_4D00_FD_Transport_Protocol_: 8 Vector__XXX
 SG_ FD_Transport_Protocol_Connection : 0|64@1+ (1,0) [0|18446744073709551615] "" Vector__XXX

BO_ 2555248640 VDMA_4E00_FD_Transport_Protocol_: 8 Vector__XXX
 SG_ FD_Transport_Protocol_Data_Trans : 0|64@1+ (1,0) [0|18446744073709551615] "" Vector__XXX

BO_ 2555314176 VDMA_4F00_Data_Transfer_Support: 8 Vector__XXX
 SG_ Data_Transfer_Support_RawPayload : 0|64@1+ (1,0) [0|18446744073709551615] "" Vector__XXX

BO_ 2555379712 VDMA_5000_Monthly_Data_Transfer: 8 Vector__XXX
 SG_ Monthly_Data_Transfer_RawPayload : 0|64@1+ (1,0) [0|18446744073709551615] "" Vector__XXX

BO_ 2555445248 VDMA_5100_Weekly_Data_Transfer: 8 Vector__XXX
 SG_ Weekly_Data_Transfer_RawPayload : 0|64@1+ (1,0) [0|18446744073709551615] "" Vector__XXX

BO_ 2555510784 VDMA_5200_Daily_Data_Transfer: 8 Vector__XXX
 SG_ Daily_Data_Transfer_RawPayload : 0|64@1+ (1,0) [0|18446744073709551615] "" Vector__XXX

BO_ 2555576320 VDMA_5300_EVSE_Control_1: 8 Vector__XXX
 SG_ EVSE_Control_1_RawPayload : 0|64@1+ (1,0) [0|18446744073709551615] "" Vector__XXX

BO_ 2555641856 VDMA_5400_Winch_Information_3: 8 Vector__XXX
 SG_ Winch_Information_3_RawPayload : 0|64@1+ (1,0) [0|18446744073709551615] "" Vector__XXX

BO_ 2555707392 VDMA_5500_Air_Suspension_Control: 8 Vector__XXX
 SG_ Air_Suspension_Control_8_RawPayl : 0|64@1+ (1,0) [0|18446744073709551615] "" Vector__XXX

BO_ 2555772928 VDMA_5600_Motor_Generator_2_Inve: 8 Vector__XXX
 SG_ Motor_Generator_2_Inverter_Contr : 0|64@1+ (1,0) [0|18446744073709551615] "" Vector__XXX

BO_ 2555838464 VDMA_5700_Motor_Generator_1_Inve: 8 Vector__XXX
 SG_ Motor_Generator_1_Inverter_Contr : 0|64@1+ (1,0) [0|18446744073709551615] "" Vector__XXX

BO_ 2555904000 VDMA_5800_Hoist_Command_Informat: 8 Vector__XXX
 SG_ Hoist_Command_Information_RawPay : 0|64@1+ (1,0) [0|18446744073709551615] "" Vector__XXX

BO_ 2555969536 VDMA_5900_Motor_Generator_2_Inve: 8 Vector__XXX
 SG_ Motor_Generator_2_Inverter_Isola : 0|64@1+ (1,0) [0|18446744073709551615] "" Vector__XXX

BO_ 2556035072 VDMA_5A00_Motor_Generator_1_Inve: 8 Vector__XXX
 SG_ Motor_Generator_1_Inverter_Isola : 0|64@1+ (1,0) [0|18446744073709551615] "" Vector__XXX

BO_ 2556100608 VDMA_5B00_Motor_Generator_2_Inve: 8 Vector__XXX
 SG_ Motor_Generator_2_Inverter_Limit : 0|64@1+ (1,0) [0|18446744073709551615] "" Vector__XXX

BO_ 2556166144 VDMA_5C00_Motor_Generator_2_Inve: 8 Vector__XXX
 SG_ Motor_Generator_2_Inverter_Limit : 0|64@1+ (1,0) [0|18446744073709551615] "" Vector__XXX

BO_ 2556231680 VDMA_5D00_Motor_Generator_2_Inve: 8 Vector__XXX
 SG_ Motor_Generator_2_Inverter_Limit : 0|64@1+ (1,0) [0|18446744073709551615] "" Vector__XXX

BO_ 2556297216 VDMA_5E00_Motor_Generator_1_Inve: 8 Vector__XXX
 SG_ Motor_Generator_1_Inverter_Limit : 0|64@1+ (1,0) [0|18446744073709551615] "" Vector__XXX

BO_ 2556362752 VDMA_5F00_Motor_Generator_1_Inve: 8 Vector__XXX
 SG_ Motor_Generator_1_Inverter_Limit : 0|64@1+ (1,0) [0|18446744073709551615] "" Vector__XXX

BO_ 2556428288 VDMA_6000_Motor_Generator_1_Inve: 8 Vector__XXX
 SG_ Motor_Generator_1_Inverter_Limit : 0|64@1+ (1,0) [0|18446744073709551615] "" Vector__XXX

BO_ 2556493824 VDMA_6100_Personnel_Detect_Inter: 8 Vector__XXX
 SG_ Personnel_Detect_Interlock_RawPa : 0|64@1+ (1,0) [0|18446744073709551615] "" Vector__XXX

BO_ 2556559360 VDMA_6200_Engine_Cylinder_Combus: 8 Vector__XXX
 SG_ Engine_Cylinder_Combustion_Confi : 0|64@1+ (1,0) [0|18446744073709551615] "" Vector__XXX

BO_ 2556624896 VDMA_6300_Engine_Cylinder_Combus: 8 Vector__XXX
 SG_ Engine_Cylinder_Combustion_Confi : 0|64@1+ (1,0) [0|18446744073709551615] "" Vector__XXX

BO_ 2556690432 VDMA_6400_Engine_Cylinder_Pressu: 8 Vector__XXX
 SG_ Engine_Cylinder_Pressure_Timing_ : 0|64@1+ (1,0) [0|18446744073709551615] "" Vector__XXX

BO_ 2556755968 VDMA_6500_Engine_Cylinder_Pressu: 8 Vector__XXX
 SG_ Engine_Cylinder_Pressure_Timing_ : 0|64@1+ (1,0) [0|18446744073709551615] "" Vector__XXX

BO_ 2556821504 VDMA_6600_Electrified_Accessory_: 8 Vector__XXX
 SG_ Electrified_Accessory_Generator_ : 0|64@1+ (1,0) [0|18446744073709551615] "" Vector__XXX

BO_ 2556887040 VDMA_6700_Electrified_Accessory_: 8 Vector__XXX
 SG_ Electrified_Accessory_Generator_ : 0|64@1+ (1,0) [0|18446744073709551615] "" Vector__XXX

BO_ 2556952576 VDMA_6800_On_Board_Programming_1: 8 Vector__XXX
 SG_ On_Board_Programming_1_RawPayloa : 0|64@1+ (1,0) [0|18446744073709551615] "" Vector__XXX

BO_ 2557018112 VDMA_6900_Marine_Control_Informa: 8 Vector__XXX
 SG_ Marine_Control_Information_Confi : 0|64@1+ (1,0) [0|18446744073709551615] "" Vector__XXX

BO_ 2557083648 VDMA_6A00_Marine_Control_Informa: 8 Vector__XXX
 SG_ Marine_Control_Information_2_Raw : 0|64@1+ (1,0) [0|18446744073709551615] "" Vector__XXX

BO_ 2557149184 VDMA_6B00_Well_Stimulation_Pump_: 8 Vector__XXX
 SG_ Well_Stimulation_Pump_Sensor_Cal : 0|64@1+ (1,0) [0|18446744073709551615] "" Vector__XXX

BO_ 2557214720 VDMA_6C00_CiA_602_2_XCP_Obsolete: 8 Vector__XXX
 SG_ CiA_602_2_XCP_Obsolete_RawPayloa : 0|64@1+ (1,0) [0|18446744073709551615] "" Vector__XXX

BO_ 2557280256 VDMA_6D00_Well_Stimulation_Pump_: 8 Vector__XXX
 SG_ Well_Stimulation_Pump_System_Con : 0|64@1+ (1,0) [0|18446744073709551615] "" Vector__XXX

BO_ 2557345792 VDMA_6E00_Configurable_Receive_S: 8 Vector__XXX
 SG_ Configurable_Receive_SPNs_Comman : 0|64@1+ (1,0) [0|18446744073709551615] "" Vector__XXX

BO_ 2557411328 VDMA_6F00_Authentication_Client_: 8 Vector__XXX
 SG_ Authentication_Client_to_Authent : 0|64@1+ (1,0) [0|18446744073709551615] "" Vector__XXX

BO_ 2557476864 VDMA_7000_Authentication_Server_: 8 Vector__XXX
 SG_ Authentication_Server_to_Authent : 0|64@1+ (1,0) [0|18446744073709551615] "" Vector__XXX

BO_ 2557542400 VDMA_7100_Configurable_Transmit_: 8 Vector__XXX
 SG_ Configurable_Transmit_PGNs_Comma : 0|64@1+ (1,0) [0|18446744073709551615] "" Vector__XXX

BO_ 2557607936 VDMA_7200_Oil_Debris_Monitor_Con: 8 Vector__XXX
 SG_ Oil_Debris_Monitor_Configuration : 0|64@1+ (1,0) [0|18446744073709551615] "" Vector__XXX

BO_ 2557673472 VDMA_7300_Electrified_Accessory_: 8 Vector__XXX
 SG_ Electrified_Accessory_Propulsion : 0|64@1+ (1,0) [0|18446744073709551615] "" Vector__XXX

BO_ 2557739008 VDMA_7400_Electrified_Accessory_: 8 Vector__XXX
 SG_ Electrified_Accessory_Propulsion : 0|64@1+ (1,0) [0|18446744073709551615] "" Vector__XXX

BO_ 2557804544 VDMA_7500_Electrified_Accessory_: 8 Vector__XXX
 SG_ Electrified_Accessory_Propulsion : 0|64@1+ (1,0) [0|18446744073709551615] "" Vector__XXX

BO_ 2557870080 VDMA_7600_Electrified_Accessory_: 8 Vector__XXX
 SG_ Electrified_Accessory_Power_Elec : 0|64@1+ (1,0) [0|18446744073709551615] "" Vector__XXX

BO_ 2557935616 VDMA_7700_Electrified_Accessory_: 8 Vector__XXX
 SG_ Electrified_Accessory_Power_Elec : 0|64@1+ (1,0) [0|18446744073709551615] "" Vector__XXX

BO_ 2558001152 VDMA_7800_Electrified_Accessory_: 8 Vector__XXX
 SG_ Electrified_Accessory_Power_Elec : 0|64@1+ (1,0) [0|18446744073709551615] "" Vector__XXX

BO_ 2558066688 VDMA_7900_Electrified_Accessory_: 8 Vector__XXX
 SG_ Electrified_Accessory_Propulsion : 0|64@1+ (1,0) [0|18446744073709551615] "" Vector__XXX

BO_ 2558132224 VDMA_7A00_Electrified_Accessory_: 8 Vector__XXX
 SG_ Electrified_Accessory_Propulsion : 0|64@1+ (1,0) [0|18446744073709551615] "" Vector__XXX

BO_ 2558197760 VDMA_7B00_Electrified_Accessory_: 8 Vector__XXX
 SG_ Electrified_Accessory_Power_Elec : 0|64@1+ (1,0) [0|18446744073709551615] "" Vector__XXX

BO_ 2558263296 VDMA_7C00_Extended_Control_Funct: 8 Vector__XXX
 SG_ Extended_Control_Function_Functi : 0|64@1+ (1,0) [0|18446744073709551615] "" Vector__XXX

BO_ 2558328832 VDMA_7D00_Electrified_Accessory_: 8 Vector__XXX
 SG_ Electrified_Accessory_Motor_Comm : 0|64@1+ (1,0) [0|18446744073709551615] "" Vector__XXX

BO_ 2558394368 VDMA_7E00_Engine_Speed_Ramp_Rate: 8 Vector__XXX
 SG_ Engine_Speed_Ramp_Rate_Boundary_ : 0|64@1+ (1,0) [0|18446744073709551615] "" Vector__XXX

BO_ 2558459904 VDMA_7F00_Tire_Sensor_Identifica: 8 Vector__XXX
 SG_ Tire_Sensor_Identification_Comma : 0|64@1+ (1,0) [0|18446744073709551615] "" Vector__XXX

BO_ 2558525440 VDMA_8000_Hybrid_or_EV_System_Co: 8 Vector__XXX
 SG_ Hybrid_or_EV_System_Control_1_Ra : 0|64@1+ (1,0) [0|18446744073709551615] "" Vector__XXX

BO_ 2558590976 VDMA_8100_Aftertreatment_System_: 8 Vector__XXX
 SG_ Aftertreatment_System_Control_Ra : 0|64@1+ (1,0) [0|18446744073709551615] "" Vector__XXX

BO_ 2558656512 VDMA_8200_Tire_Configuration_Com: 8 Vector__XXX
 SG_ Tire_Configuration_Command_Infor : 0|64@1+ (1,0) [0|18446744073709551615] "" Vector__XXX

BO_ 2558722048 VDMA_8300_Payload_Calibration_In: 8 Vector__XXX
 SG_ Payload_Calibration_Information_ : 0|64@1+ (1,0) [0|18446744073709551615] "" Vector__XXX

BO_ 2558787584 VDMA_8400_Aftertreatment_1_Parti: 8 Vector__XXX
 SG_ Aftertreatment_1_Particulate_Sen : 0|64@1+ (1,0) [0|18446744073709551615] "" Vector__XXX

BO_ 2558853120 VDMA_8500_Cab_Message_2: 8 Vector__XXX
 SG_ Cab_Message_2_RawPayload : 0|64@1+ (1,0) [0|18446744073709551615] "" Vector__XXX

BO_ 2558918656 VDMA_8600_Switched_Power_Outputs: 8 Vector__XXX
 SG_ Switched_Power_Outputs_Command_R : 0|64@1+ (1,0) [0|18446744073709551615] "" Vector__XXX

BO_ 2558984192 VDMA_8700_Engine_State_Requests: 8 Vector__XXX
 SG_ Engine_State_Requests_RawPayload : 0|64@1+ (1,0) [0|18446744073709551615] "" Vector__XXX

BO_ 2559049728 VDMA_8800_Radio_Beacon_Request: 8 Vector__XXX
 SG_ Radio_Beacon_Request_RawPayload : 0|64@1+ (1,0) [0|18446744073709551615] "" Vector__XXX

BO_ 2559115264 VDMA_8900_Running_Gear_Equipment: 8 Vector__XXX
 SG_ Running_Gear_Equipment_2_4_RawPa : 0|64@1+ (1,0) [0|18446744073709551615] "" Vector__XXX

BO_ 2559180800 VDMA_8A00_Running_Gear_Equipment: 8 Vector__XXX
 SG_ Running_Gear_Equipment_1_2_RawPa : 0|64@1+ (1,0) [0|18446744073709551615] "" Vector__XXX

BO_ 2559246336 VDMA_8B00_CCP_Data_Transmission_: 8 Vector__XXX
 SG_ CCP_Data_Transmission_Object_Raw : 0|64@1+ (1,0) [0|18446744073709551615] "" Vector__XXX

BO_ 2559311872 VDMA_8C00_CCP_Command_Receive_Ob: 8 Vector__XXX
 SG_ CCP_Command_Receive_Object_RawPa : 0|64@1+ (1,0) [0|18446744073709551615] "" Vector__XXX

BO_ 2559377408 VDMA_8D00_Sequence_Control_Clien: 8 Vector__XXX
 SG_ Sequence_Control_Client_to_Seque : 0|64@1+ (1,0) [0|18446744073709551615] "" Vector__XXX

BO_ 2559442944 VDMA_8E00_Sequence_Control_Maste: 8 Vector__XXX
 SG_ Sequence_Control_Master_to_Seque : 0|64@1+ (1,0) [0|18446744073709551615] "" Vector__XXX

BO_ 2559508480 VDMA_8F00_Engine_Configuration_C: 8 Vector__XXX
 SG_ Engine_Configuration_Commands_Ra : 0|64@1+ (1,0) [0|18446744073709551615] "" Vector__XXX

BO_ 2559574016 VDMA_9000_Supplemental_Fan_Comma: 8 Vector__XXX
 SG_ Supplemental_Fan_Command_RawPayl : 0|64@1+ (1,0) [0|18446744073709551615] "" Vector__XXX

BO_ 2559639552 VDMA_9100_Vehicle_Chassis_Lubric: 8 Vector__XXX
 SG_ Vehicle_Chassis_Lubrication_Syst : 0|64@1+ (1,0) [0|18446744073709551615] "" Vector__XXX

BO_ 2559705088 VDMA_9200_Aftertreatment_1_Hydro: 8 Vector__XXX
 SG_ Aftertreatment_1_Hydrocarbon_Dos : 0|64@1+ (1,0) [0|18446744073709551615] "" Vector__XXX

BO_ 2559770624 VDMA_9300_NAME_Management_Messag: 8 Vector__XXX
 SG_ NAME_Management_Message_RawPaylo : 0|64@1+ (1,0) [0|18446744073709551615] "" Vector__XXX

BO_ 2559836160 VDMA_9400_Aftertreatment_1_Diese: 8 Vector__XXX
 SG_ Aftertreatment_1_Diesel_Particul : 0|64@1+ (1,0) [0|18446744073709551615] "" Vector__XXX

BO_ 2559901696 VDMA_9500_Aftertreatment_2_Diese: 8 Vector__XXX
 SG_ Aftertreatment_2_Diesel_Particul : 0|64@1+ (1,0) [0|18446744073709551615] "" Vector__XXX

BO_ 2559967232 VDMA_9600_Low_Voltage_Disconnect: 8 Vector__XXX
 SG_ Low_Voltage_Disconnect_Set_Opera : 0|64@1+ (1,0) [0|18446744073709551615] "" Vector__XXX

BO_ 2560032768 VDMA_9700_Noise_Control_Status: 8 Vector__XXX
 SG_ Noise_Control_Status_RawPayload : 0|64@1+ (1,0) [0|18446744073709551615] "" Vector__XXX

BO_ 2560098304 VDMA_9800_Noise_Control_1: 8 Vector__XXX
 SG_ Noise_Control_1_RawPayload : 0|64@1+ (1,0) [0|18446744073709551615] "" Vector__XXX

BO_ 2560163840 VDMA_9900_Joystick_Lamp_Command_: 8 Vector__XXX
 SG_ Joystick_Lamp_Command_Message_Ra : 0|64@1+ (1,0) [0|18446744073709551615] "" Vector__XXX

BO_ 2560229376 VDMA_9A00_General_Purpose_Messag: 8 Vector__XXX
 SG_ General_Purpose_Message_1_8_RawP : 0|64@1+ (1,0) [0|18446744073709551615] "" Vector__XXX

BO_ 2560360448 VDMA_9C00_Auxiliary_Input_Output: 8 Vector__XXX
 SG_ Auxiliary_Input_Output_Status_7_ : 0|64@1+ (1,0) [0|18446744073709551615] "" Vector__XXX

BO_ 2560425984 VDMA_9D00_Auxiliary_Input_Output: 8 Vector__XXX
 SG_ Auxiliary_Input_Output_Status_6_ : 0|64@1+ (1,0) [0|18446744073709551615] "" Vector__XXX

BO_ 2560491520 VDMA_9E00_DTC_Counts: 8 Vector__XXX
 SG_ DTC_Counts_RawPayload : 0|64@1+ (1,0) [0|18446744073709551615] "" Vector__XXX

BO_ 2560557056 VDMA_9F00_Immediate_Fault_Status: 8 Vector__XXX
 SG_ Immediate_Fault_Status_RawPayloa : 0|64@1+ (1,0) [0|18446744073709551615] "" Vector__XXX

BO_ 2560622592 VDMA_A000_NTE_Status: 8 Vector__XXX
 SG_ NTE_Status_RawPayload : 0|64@1+ (1,0) [0|18446744073709551615] "" Vector__XXX

BO_ 2560688128 VDMA_A100_Emission_Increasing_Au: 8 Vector__XXX
 SG_ Emission_Increasing_Auxiliary_Em : 0|64@1+ (1,0) [0|18446744073709551615] "" Vector__XXX

BO_ 2560753664 VDMA_A200_Regulated_Exhaust_Emis: 8 Vector__XXX
 SG_ Regulated_Exhaust_Emission_Level : 0|64@1+ (1,0) [0|18446744073709551615] "" Vector__XXX

BO_ 2560819200 VDMA_A300_DTC_To_Lamp_Associatio: 8 Vector__XXX
 SG_ DTC_To_Lamp_Association_RawPaylo : 0|64@1+ (1,0) [0|18446744073709551615] "" Vector__XXX

BO_ 2560884736 VDMA_A400_Scaled_Test_Results: 8 Vector__XXX
 SG_ Scaled_Test_Results_RawPayload : 0|64@1+ (1,0) [0|18446744073709551615] "" Vector__XXX

BO_ 2560950272 VDMA_A500_Auxiliary_Input_Output: 8 Vector__XXX
 SG_ Auxiliary_Input_Output_Status_4_ : 0|64@1+ (1,0) [0|18446744073709551615] "" Vector__XXX

BO_ 2561015808 VDMA_A600_Auxiliary_Input_Output: 8 Vector__XXX
 SG_ Auxiliary_Input_Output_Status_3_ : 0|64@1+ (1,0) [0|18446744073709551615] "" Vector__XXX

BO_ 2561081344 VDMA_A700_Auxiliary_Input_Output: 8 Vector__XXX
 SG_ Auxiliary_Input_Output_Status_2_ : 0|64@1+ (1,0) [0|18446744073709551615] "" Vector__XXX

BO_ 2561146880 VDMA_A800_Text_Display: 8 Vector__XXX
 SG_ Text_Display_RawPayload : 0|64@1+ (1,0) [0|18446744073709551615] "" Vector__XXX

BO_ 2561212416 VDMA_A900_Forward_Lane_Image_Com: 8 Vector__XXX
 SG_ Forward_Lane_Image_Command_RawPa : 0|64@1+ (1,0) [0|18446744073709551615] "" Vector__XXX

BO_ 2561277952 VDMA_AA00_Client_ECU_to_File_Ser: 8 Vector__XXX
 SG_ Client_ECU_to_File_Server_messag : 0|64@1+ (1,0) [0|18446744073709551615] "" Vector__XXX

BO_ 2561343488 VDMA_AB00_File_Server_to_Client_: 8 Vector__XXX
 SG_ File_Server_to_Client_ECU_messag : 0|64@1+ (1,0) [0|18446744073709551615] "" Vector__XXX

BO_ 2561540096 VDMA_AE00_Tire_Pressure_Referenc: 8 Vector__XXX
 SG_ Tire_Pressure_Reference_Setting_ : 0|64@1+ (1,0) [0|18446744073709551615] "" Vector__XXX

BO_ 2561605632 VDMA_AF00_Parameter_Locate_Messa: 8 Vector__XXX
 SG_ Parameter_Locate_Message_RawPayl : 0|64@1+ (1,0) [0|18446744073709551615] "" Vector__XXX

BO_ 2561671168 VDMA_B000_Configuration_Identifi: 8 Vector__XXX
 SG_ Configuration_Identification_Mes : 0|64@1+ (1,0) [0|18446744073709551615] "" Vector__XXX

BO_ 2561736704 VDMA_B100_Proprietarily_Configur: 8 Vector__XXX
 SG_ Proprietarily_Configurable_Messa : 0|64@1+ (1,0) [0|18446744073709551615] "" Vector__XXX

BO_ 2561802240 VDMA_B200_Proprietarily_Configur: 8 Vector__XXX
 SG_ Proprietarily_Configurable_Messa : 0|64@1+ (1,0) [0|18446744073709551615] "" Vector__XXX

BO_ 2561867776 VDMA_B300_Proprietarily_Configur: 8 Vector__XXX
 SG_ Proprietarily_Configurable_Messa : 0|64@1+ (1,0) [0|18446744073709551615] "" Vector__XXX

BO_ 2561933312 VDMA_B400_Proprietarily_Configur: 8 Vector__XXX
 SG_ Proprietarily_Configurable_Messa : 0|64@1+ (1,0) [0|18446744073709551615] "" Vector__XXX

BO_ 2561998848 VDMA_B500_Proprietarily_Configur: 8 Vector__XXX
 SG_ Proprietarily_Configurable_Messa : 0|64@1+ (1,0) [0|18446744073709551615] "" Vector__XXX

BO_ 2562064384 VDMA_B600_Proprietarily_Configur: 8 Vector__XXX
 SG_ Proprietarily_Configurable_Messa : 0|64@1+ (1,0) [0|18446744073709551615] "" Vector__XXX

BO_ 2562129920 VDMA_B700_Proprietarily_Configur: 8 Vector__XXX
 SG_ Proprietarily_Configurable_Messa : 0|64@1+ (1,0) [0|18446744073709551615] "" Vector__XXX

BO_ 2562195456 VDMA_B800_Proprietarily_Configur: 8 Vector__XXX
 SG_ Proprietarily_Configurable_Messa : 0|64@1+ (1,0) [0|18446744073709551615] "" Vector__XXX

BO_ 2562260992 VDMA_B900_Proprietarily_Configur: 8 Vector__XXX
 SG_ Proprietarily_Configurable_Messa : 0|64@1+ (1,0) [0|18446744073709551615] "" Vector__XXX

BO_ 2562326528 VDMA_BA00_Proprietarily_Configur: 8 Vector__XXX
 SG_ Proprietarily_Configurable_Messa : 0|64@1+ (1,0) [0|18446744073709551615] "" Vector__XXX

BO_ 2562392064 VDMA_BB00_Proprietarily_Configur: 8 Vector__XXX
 SG_ Proprietarily_Configurable_Messa : 0|64@1+ (1,0) [0|18446744073709551615] "" Vector__XXX

BO_ 2562457600 VDMA_BC00_Proprietarily_Configur: 8 Vector__XXX
 SG_ Proprietarily_Configurable_Messa : 0|64@1+ (1,0) [0|18446744073709551615] "" Vector__XXX

BO_ 2562523136 VDMA_BD00_Proprietarily_Configur: 8 Vector__XXX
 SG_ Proprietarily_Configurable_Messa : 0|64@1+ (1,0) [0|18446744073709551615] "" Vector__XXX

BO_ 2562588672 VDMA_BE00_Proprietarily_Configur: 8 Vector__XXX
 SG_ Proprietarily_Configurable_Messa : 0|64@1+ (1,0) [0|18446744073709551615] "" Vector__XXX

BO_ 2562654208 VDMA_BF00_Proprietarily_Configur: 8 Vector__XXX
 SG_ Proprietarily_Configurable_Messa : 0|64@1+ (1,0) [0|18446744073709551615] "" Vector__XXX

BO_ 2562719744 VDMA_C000_Proprietarily_Configur: 8 Vector__XXX
 SG_ Proprietarily_Configurable_Messa : 0|64@1+ (1,0) [0|18446744073709551615] "" Vector__XXX

BO_ 2562785280 VDMA_C100_Diagnostic_Readiness_2: 8 Vector__XXX
 SG_ Diagnostic_Readiness_2_RawPayloa : 0|64@1+ (1,0) [0|18446744073709551615] "" Vector__XXX

BO_ 2562850816 VDMA_C200_Monitor_Performance_Ra: 8 Vector__XXX
 SG_ Monitor_Performance_Ratio_RawPay : 0|64@1+ (1,0) [0|18446744073709551615] "" Vector__XXX

BO_ 2562981888 VDMA_C400_General_Purpose_Valve_: 8 Vector__XXX
 SG_ General_Purpose_Valve_command_Ra : 0|64@1+ (1,0) [0|18446744073709551615] "" Vector__XXX

BO_ 2563047424 VDMA_C500_General_Purpose_Valve_: 8 Vector__XXX
 SG_ General_Purpose_Valve_measured_f : 0|64@1+ (1,0) [0|18446744073709551615] "" Vector__XXX

BO_ 2563112960 VDMA_C600_General_Purpose_Valve_: 8 Vector__XXX
 SG_ General_Purpose_Valve_estimated_ : 0|64@1+ (1,0) [0|18446744073709551615] "" Vector__XXX

BO_ 2563309568 VDMA_C900_Request_2: 8 Vector__XXX
 SG_ Request_2_RawPayload : 0|64@1+ (1,0) [0|18446744073709551615] "" Vector__XXX

BO_ 2563375104 VDMA_CA00_Transfer: 8 Vector__XXX
 SG_ Transfer_RawPayload : 0|64@1+ (1,0) [0|18446744073709551615] "" Vector__XXX

BO_ 2563702784 VDMA_CF00_Continuous_Torque_Spee: 8 Vector__XXX
 SG_ Continuous_Torque_Speed_Limit_Re : 0|64@1+ (1,0) [0|18446744073709551615] "" Vector__XXX

BO_ 2563768320 VDMA_D000_Background_lighting_le: 8 Vector__XXX
 SG_ Background_lighting_level_comman : 0|64@1+ (1,0) [0|18446744073709551615] "" Vector__XXX

BO_ 2563833856 VDMA_D100_Air_Suspension_Control: 8 Vector__XXX
 SG_ Air_Suspension_Control_6_RawPayl : 0|64@1+ (1,0) [0|18446744073709551615] "" Vector__XXX

BO_ 2563899392 VDMA_D200_Air_Suspension_Control: 8 Vector__XXX
 SG_ Air_Suspension_Control_2_RawPayl : 0|64@1+ (1,0) [0|18446744073709551615] "" Vector__XXX

BO_ 2563964928 VDMA_D300_Calibration_Informatio: 8 Vector__XXX
 SG_ Calibration_Information_RawPaylo : 0|64@1+ (1,0) [0|18446744073709551615] "" Vector__XXX

BO_ 2564030464 VDMA_D400_Data_Security: 8 Vector__XXX
 SG_ Data_Security_RawPayload : 0|64@1+ (1,0) [0|18446744073709551615] "" Vector__XXX

BO_ 2564096000 VDMA_D500_Time_Date_Adjust: 8 Vector__XXX
 SG_ Time_Date_Adjust_RawPayload : 0|64@1+ (1,0) [0|18446744073709551615] "" Vector__XXX

BO_ 2564161536 VDMA_D600_Boot_Load_Data: 8 Vector__XXX
 SG_ Boot_Load_Data_RawPayload : 0|64@1+ (1,0) [0|18446744073709551615] "" Vector__XXX

BO_ 2564554752 VDMA_DC00_Anti_theft_Status: 8 Vector__XXX
 SG_ Anti_theft_Status_RawPayload : 0|64@1+ (1,0) [0|18446744073709551615] "" Vector__XXX

BO_ 2564620288 VDMA_DD00_Anti_theft_Request: 8 Vector__XXX
 SG_ Anti_theft_Request_RawPayload : 0|64@1+ (1,0) [0|18446744073709551615] "" Vector__XXX

BO_ 2564685824 VDMA_DE00_Reset: 8 Vector__XXX
 SG_ Reset_RawPayload : 0|64@1+ (1,0) [0|18446744073709551615] "" Vector__XXX

BO_ 2564816896 VDMA_E000_Cab_Message_1: 8 Vector__XXX
 SG_ Cab_Message_1_RawPayload : 0|64@1+ (1,0) [0|18446744073709551615] "" Vector__XXX

BO_ 2564882432 VDMA_E100_General_Purpose_Messag: 8 Vector__XXX
 SG_ General_Purpose_Message_2_1_RawP : 0|64@1+ (1,0) [0|18446744073709551615] "" Vector__XXX

BO_ 2564947968 VDMA_E200_General_Purpose_Messag: 8 Vector__XXX
 SG_ General_Purpose_Message_1_1_RawP : 0|64@1+ (1,0) [0|18446744073709551615] "" Vector__XXX

BO_ 2565013504 VDMA_E300_Command_Non_continuous: 8 Vector__XXX
 SG_ Command_Non_continuously_Monitor : 0|64@1+ (1,0) [0|18446744073709551615] "" Vector__XXX

BO_ 2565079040 VDMA_E400_Running_Gear_Equipment: 8 Vector__XXX
 SG_ Running_Gear_Equipment_1_1_RawPa : 0|64@1+ (1,0) [0|18446744073709551615] "" Vector__XXX

BO_ 2565144576 VDMA_E500_Running_Gear_Equipment: 8 Vector__XXX
 SG_ Running_Gear_Equipment_2_1_RawPa : 0|64@1+ (1,0) [0|18446744073709551615] "" Vector__XXX

BO_ 2565668864 VDMA_ED00_Network_Message: 8 Vector__XXX
 SG_ Network_Message_RawPayload : 0|64@1+ (1,0) [0|18446744073709551615] "" Vector__XXX

BO_ 2565865472 VDMA_F000_Electronic_Retarder_Co: 8 Vector__XXX
 SG_ Electronic_Retarder_Controller_1 : 0|64@1+ (1,0) [0|18446744073709551615] "" Vector__XXX

BO_ 2565865728 VDMA_F001_Electronic_Brake_Contr: 8 Vector__XXX
 SG_ Electronic_Brake_Controller_1_Ra : 0|64@1+ (1,0) [0|18446744073709551615] "" Vector__XXX

BO_ 2565865984 VDMA_F002_Electronic_Transmissio: 8 Vector__XXX
 SG_ Electronic_Transmission_Controll : 0|64@1+ (1,0) [0|18446744073709551615] "" Vector__XXX

BO_ 2565866752 VDMA_F005_Electronic_Transmissio: 8 Vector__XXX
 SG_ Electronic_Transmission_Controll : 0|64@1+ (1,0) [0|18446744073709551615] "" Vector__XXX

BO_ 2565867008 VDMA_F006_Electronic_Axle_Contro: 8 Vector__XXX
 SG_ Electronic_Axle_Controller_1_Raw : 0|64@1+ (1,0) [0|18446744073709551615] "" Vector__XXX

BO_ 2565867264 VDMA_F007_Forward_Lane_Image_1: 8 Vector__XXX
 SG_ Forward_Lane_Image_1_RawPayload : 0|64@1+ (1,0) [0|18446744073709551615] "" Vector__XXX

BO_ 2565867520 VDMA_F008_Hydraulic_Pressure_Gov: 8 Vector__XXX
 SG_ Hydraulic_Pressure_Governor_Info : 0|64@1+ (1,0) [0|18446744073709551615] "" Vector__XXX

BO_ 2565867776 VDMA_F009_Vehicle_Dynamic_Stabil: 8 Vector__XXX
 SG_ Vehicle_Dynamic_Stability_Contro : 0|64@1+ (1,0) [0|18446744073709551615] "" Vector__XXX

BO_ 2565868032 VDMA_F00A_Engine_Gas_Flow_Rate_1: 8 Vector__XXX
 SG_ Engine_Gas_Flow_Rate_1_RawPayloa : 0|64@1+ (1,0) [0|18446744073709551615] "" Vector__XXX

BO_ 2565868288 VDMA_F00B_Electronic_Steering_Co: 8 Vector__XXX
 SG_ Electronic_Steering_Control_RawP : 0|64@1+ (1,0) [0|18446744073709551615] "" Vector__XXX

BO_ 2565868544 VDMA_F00C_Electronic_Transmissio: 8 Vector__XXX
 SG_ Electronic_Transmission_Controll : 0|64@1+ (1,0) [0|18446744073709551615] "" Vector__XXX

BO_ 2565868800 VDMA_F00D_Land_Leveling_System_O: 8 Vector__XXX
 SG_ Land_Leveling_System_Operational : 0|64@1+ (1,0) [0|18446744073709551615] "" Vector__XXX

BO_ 2565869056 VDMA_F00E_Aftertreatment_1_Intak: 8 Vector__XXX
 SG_ Aftertreatment_1_Intake_Gas_1_Ra : 0|64@1+ (1,0) [0|18446744073709551615] "" Vector__XXX

BO_ 2565869312 VDMA_F00F_Aftertreatment_1_Outle: 8 Vector__XXX
 SG_ Aftertreatment_1_Outlet_Gas_1_Ra : 0|64@1+ (1,0) [0|18446744073709551615] "" Vector__XXX

BO_ 2565869568 VDMA_F010_Aftertreatment_2_Intak: 8 Vector__XXX
 SG_ Aftertreatment_2_Intake_Gas_1_Ra : 0|64@1+ (1,0) [0|18446744073709551615] "" Vector__XXX

BO_ 2565869824 VDMA_F011_Aftertreatment_2_Outle: 8 Vector__XXX
 SG_ Aftertreatment_2_Outlet_Gas_1_Ra : 0|64@1+ (1,0) [0|18446744073709551615] "" Vector__XXX

BO_ 2565870080 VDMA_F012_Fifth_Wheel_Smart_Syst: 8 Vector__XXX
 SG_ Fifth_Wheel_Smart_Systems_1_RawP : 0|64@1+ (1,0) [0|18446744073709551615] "" Vector__XXX

BO_ 2565870336 VDMA_F013_Slope_Sensor_Informati: 8 Vector__XXX
 SG_ Slope_Sensor_Information_RawPayl : 0|64@1+ (1,0) [0|18446744073709551615] "" Vector__XXX

BO_ 2565870592 VDMA_F014_Blade_Information: 8 Vector__XXX
 SG_ Blade_Information_RawPayload : 0|64@1+ (1,0) [0|18446744073709551615] "" Vector__XXX

BO_ 2565870848 VDMA_F015_Requested_Generator_To: 8 Vector__XXX
 SG_ Requested_Generator_Total_AC_Rea : 0|64@1+ (1,0) [0|18446744073709551615] "" Vector__XXX

BO_ 2565871104 VDMA_F016_Cylinder_Combustion_St: 8 Vector__XXX
 SG_ Cylinder_Combustion_Status_RawPa : 0|64@1+ (1,0) [0|18446744073709551615] "" Vector__XXX

BO_ 2565871360 VDMA_F017_Engine_Knock_Level_1: 8 Vector__XXX
 SG_ Engine_Knock_Level_1_RawPayload : 0|64@1+ (1,0) [0|18446744073709551615] "" Vector__XXX

BO_ 2565871616 VDMA_F018_Engine_Knock_Level_2: 8 Vector__XXX
 SG_ Engine_Knock_Level_2_RawPayload : 0|64@1+ (1,0) [0|18446744073709551615] "" Vector__XXX

BO_ 2565871872 VDMA_F019_Engine_Knock_Level_3: 8 Vector__XXX
 SG_ Engine_Knock_Level_3_RawPayload : 0|64@1+ (1,0) [0|18446744073709551615] "" Vector__XXX

BO_ 2565872128 VDMA_F01A_Engine_Throttle_Fuel_A: 8 Vector__XXX
 SG_ Engine_Throttle_Fuel_Actuator_Co : 0|64@1+ (1,0) [0|18446744073709551615] "" Vector__XXX

BO_ 2565872384 VDMA_F01B_General_Purpose_Messag: 8 Vector__XXX
 SG_ General_Purpose_Message_1_7_RawP : 0|64@1+ (1,0) [0|18446744073709551615] "" Vector__XXX

BO_ 2565872640 VDMA_F01C_Requested_Generator_Av: 8 Vector__XXX
 SG_ Requested_Generator_Average_Basi : 0|64@1+ (1,0) [0|18446744073709551615] "" Vector__XXX

BO_ 2565872896 VDMA_F01D_Steering_Angle_Sensor_: 8 Vector__XXX
 SG_ Steering_Angle_Sensor_Informatio : 0|64@1+ (1,0) [0|18446744073709551615] "" Vector__XXX

BO_ 2565873152 VDMA_F01E_Generator_Control_2: 8 Vector__XXX
 SG_ Generator_Control_2_RawPayload : 0|64@1+ (1,0) [0|18446744073709551615] "" Vector__XXX

BO_ 2565873408 VDMA_F01F_Electronic_Brake_Syste: 8 Vector__XXX
 SG_ Electronic_Brake_System_2_6_RawP : 0|64@1+ (1,0) [0|18446744073709551615] "" Vector__XXX

BO_ 2565873664 VDMA_F020_Electronic_Brake_Syste: 8 Vector__XXX
 SG_ Electronic_Brake_System_2_5_RawP : 0|64@1+ (1,0) [0|18446744073709551615] "" Vector__XXX

BO_ 2565873920 VDMA_F021_Engine_Speed_Sensor_In: 8 Vector__XXX
 SG_ Engine_Speed_Sensor_Information_ : 0|64@1+ (1,0) [0|18446744073709551615] "" Vector__XXX

BO_ 2565874432 VDMA_F023_Aftertreatment_1_SCR_D: 8 Vector__XXX
 SG_ Aftertreatment_1_SCR_Dosing_Syst : 0|64@1+ (1,0) [0|18446744073709551615] "" Vector__XXX

BO_ 2565874688 VDMA_F024_Aftertreatment_1_SCR_D: 8 Vector__XXX
 SG_ Aftertreatment_1_SCR_Dosing_Syst : 0|64@1+ (1,0) [0|18446744073709551615] "" Vector__XXX

BO_ 2565874944 VDMA_F025_Aftertreatment_1_SCR_A: 8 Vector__XXX
 SG_ Aftertreatment_1_SCR_Ammonia_Inf : 0|64@1+ (1,0) [0|18446744073709551615] "" Vector__XXX

BO_ 2565875200 VDMA_F026_Aftertreatment_2_SCR_D: 8 Vector__XXX
 SG_ Aftertreatment_2_SCR_Dosing_Syst : 0|64@1+ (1,0) [0|18446744073709551615] "" Vector__XXX

BO_ 2565875456 VDMA_F027_Aftertreatment_2_SCR_D: 8 Vector__XXX
 SG_ Aftertreatment_2_SCR_Dosing_Syst : 0|64@1+ (1,0) [0|18446744073709551615] "" Vector__XXX

CM_ BO_ 2550202368  "Source: isobus.net VDMA Data Dictionary (https://www.isobus.net/isobus/pGNAndSPN/38?type=PGN)";
CM_ BO_ 2550267904  "Source: isobus.net VDMA Data Dictionary (https://www.isobus.net/isobus/pGNAndSPN/39?type=PGN)";
CM_ BO_ 2550333440  "Source: isobus.net VDMA Data Dictionary (https://www.isobus.net/isobus/pGNAndSPN/40?type=PGN)";
CM_ BO_ 2550398976  "Source: isobus.net VDMA Data Dictionary (https://www.isobus.net/isobus/pGNAndSPN/50?type=PGN)";
CM_ BO_ 2550464512  "Source: isobus.net VDMA Data Dictionary (https://www.isobus.net/isobus/pGNAndSPN/51?type=PGN)";
CM_ BO_ 2550530048  "Source: isobus.net VDMA Data Dictionary (https://www.isobus.net/isobus/pGNAndSPN/52?type=PGN)";
CM_ BO_ 2550595584  "Source: isobus.net VDMA Data Dictionary (https://www.isobus.net/isobus/pGNAndSPN/57?type=PGN)";
CM_ BO_ 2550661120  "Source: isobus.net VDMA Data Dictionary (https://www.isobus.net/isobus/pGNAndSPN/61?type=PGN)";
CM_ BO_ 2550726656  "Source: isobus.net VDMA Data Dictionary (https://www.isobus.net/isobus/pGNAndSPN/63?type=PGN)";
CM_ BO_ 2550792192  "Source: isobus.net VDMA Data Dictionary (https://www.isobus.net/isobus/pGNAndSPN/71?type=PGN)";
CM_ BO_ 2550857728  "Source: isobus.net VDMA Data Dictionary (https://www.isobus.net/isobus/pGNAndSPN/74?type=PGN)";
CM_ BO_ 2550923264  "Source: isobus.net VDMA Data Dictionary (https://www.isobus.net/isobus/pGNAndSPN/77?type=PGN)";
CM_ BO_ 2550988800  "Source: isobus.net VDMA Data Dictionary (https://www.isobus.net/isobus/pGNAndSPN/96?type=PGN)";
CM_ BO_ 2551054336  "Source: isobus.net VDMA Data Dictionary (https://www.isobus.net/isobus/pGNAndSPN/103?type=PGN)";
CM_ BO_ 2551119872  "Source: isobus.net VDMA Data Dictionary (https://www.isobus.net/isobus/pGNAndSPN/115?type=PGN)";
CM_ BO_ 2551185408  "Source: isobus.net VDMA Data Dictionary (https://www.isobus.net/isobus/pGNAndSPN/127?type=PGN)";
CM_ BO_ 2551250944  "Source: isobus.net VDMA Data Dictionary (https://www.isobus.net/isobus/pGNAndSPN/139?type=PGN)";
CM_ BO_ 2551316480  "Source: isobus.net VDMA Data Dictionary (https://www.isobus.net/isobus/pGNAndSPN/151?type=PGN)";
CM_ BO_ 2551382016  "Source: isobus.net VDMA Data Dictionary (https://www.isobus.net/isobus/pGNAndSPN/163?type=PGN)";
CM_ BO_ 2551447552  "Source: isobus.net VDMA Data Dictionary (https://www.isobus.net/isobus/pGNAndSPN/175?type=PGN)";
CM_ BO_ 2551513088  "Source: isobus.net VDMA Data Dictionary (https://www.isobus.net/isobus/pGNAndSPN/187?type=PGN)";
CM_ BO_ 2551578624  "Source: isobus.net VDMA Data Dictionary (https://www.isobus.net/isobus/pGNAndSPN/199?type=PGN)";
CM_ BO_ 2551644160  "Source: isobus.net VDMA Data Dictionary (https://www.isobus.net/isobus/pGNAndSPN/211?type=PGN)";
CM_ BO_ 2551709696  "Source: isobus.net VDMA Data Dictionary (https://www.isobus.net/isobus/pGNAndSPN/223?type=PGN)";
CM_ BO_ 2551775232  "Source: isobus.net VDMA Data Dictionary (https://www.isobus.net/isobus/pGNAndSPN/235?type=PGN)";
CM_ BO_ 2551840768  "Source: isobus.net VDMA Data Dictionary (https://www.isobus.net/isobus/pGNAndSPN/247?type=PGN)";
CM_ BO_ 2551906304  "Source: isobus.net VDMA Data Dictionary (https://www.isobus.net/isobus/pGNAndSPN/259?type=PGN)";
CM_ BO_ 2551971840  "Source: isobus.net VDMA Data Dictionary (https://www.isobus.net/isobus/pGNAndSPN/267?type=PGN)";
CM_ BO_ 2552037376  "Source: isobus.net VDMA Data Dictionary (https://www.isobus.net/isobus/pGNAndSPN/268?type=PGN)";
CM_ BO_ 2552102912  "Source: isobus.net VDMA Data Dictionary (https://www.isobus.net/isobus/pGNAndSPN/272?type=PGN)";
CM_ BO_ 2552168448  "Source: isobus.net VDMA Data Dictionary (https://www.isobus.net/isobus/pGNAndSPN/284?type=PGN)";
CM_ BO_ 2552233984  "Source: isobus.net VDMA Data Dictionary (https://www.isobus.net/isobus/pGNAndSPN/296?type=PGN)";
CM_ BO_ 2552299520  "Source: isobus.net VDMA Data Dictionary (https://www.isobus.net/isobus/pGNAndSPN/308?type=PGN)";
CM_ BO_ 2552365056  "Source: isobus.net VDMA Data Dictionary (https://www.isobus.net/isobus/pGNAndSPN/320?type=PGN)";
CM_ BO_ 2552430592  "Source: isobus.net VDMA Data Dictionary (https://www.isobus.net/isobus/pGNAndSPN/494?type=PGN)";
CM_ BO_ 2552496128  "Source: isobus.net VDMA Data Dictionary (https://www.isobus.net/isobus/pGNAndSPN/584?type=PGN)";
CM_ BO_ 2552561664  "Source: isobus.net VDMA Data Dictionary (https://www.isobus.net/isobus/pGNAndSPN/590?type=PGN)";
CM_ BO_ 2552627200  "Source: isobus.net VDMA Data Dictionary (https://www.isobus.net/isobus/pGNAndSPN/598?type=PGN)";
CM_ BO_ 2552692736  "Source: isobus.net VDMA Data Dictionary (https://www.isobus.net/isobus/pGNAndSPN/606?type=PGN)";
CM_ BO_ 2552758272  "Source: isobus.net VDMA Data Dictionary (https://www.isobus.net/isobus/pGNAndSPN/610?type=PGN)";
CM_ BO_ 2552823808  "Source: isobus.net VDMA Data Dictionary (https://www.isobus.net/isobus/pGNAndSPN/614?type=PGN)";
CM_ BO_ 2552889344  "Source: isobus.net VDMA Data Dictionary (https://www.isobus.net/isobus/pGNAndSPN/626?type=PGN)";
CM_ BO_ 2552954880  "Source: isobus.net VDMA Data Dictionary (https://www.isobus.net/isobus/pGNAndSPN/638?type=PGN)";
CM_ BO_ 2553020416  "Source: isobus.net VDMA Data Dictionary (https://www.isobus.net/isobus/pGNAndSPN/650?type=PGN)";
CM_ BO_ 2553085952  "Source: isobus.net VDMA Data Dictionary (https://www.isobus.net/isobus/pGNAndSPN/662?type=PGN)";
CM_ BO_ 2553151488  "Source: isobus.net VDMA Data Dictionary (https://www.isobus.net/isobus/pGNAndSPN/674?type=PGN)";
CM_ BO_ 2553217024  "Source: isobus.net VDMA Data Dictionary (https://www.isobus.net/isobus/pGNAndSPN/686?type=PGN)";
CM_ BO_ 2553282560  "Source: isobus.net VDMA Data Dictionary (https://www.isobus.net/isobus/pGNAndSPN/698?type=PGN)";
CM_ BO_ 2553348096  "Source: isobus.net VDMA Data Dictionary (https://www.isobus.net/isobus/pGNAndSPN/710?type=PGN)";
CM_ BO_ 2553413632  "Source: isobus.net VDMA Data Dictionary (https://www.isobus.net/isobus/pGNAndSPN/722?type=PGN)";
CM_ BO_ 2553479168  "Source: isobus.net VDMA Data Dictionary (https://www.isobus.net/isobus/pGNAndSPN/734?type=PGN)";
CM_ BO_ 2553544704  "Source: isobus.net VDMA Data Dictionary (https://www.isobus.net/isobus/pGNAndSPN/735?type=PGN)";
CM_ BO_ 2553610240  "Source: isobus.net VDMA Data Dictionary (https://www.isobus.net/isobus/pGNAndSPN/736?type=PGN)";
CM_ BO_ 2553675776  "Source: isobus.net VDMA Data Dictionary (https://www.isobus.net/isobus/pGNAndSPN/737?type=PGN)";
CM_ BO_ 2553741312  "Source: isobus.net VDMA Data Dictionary (https://www.isobus.net/isobus/pGNAndSPN/738?type=PGN)";
CM_ BO_ 2553806848  "Source: isobus.net VDMA Data Dictionary (https://www.isobus.net/isobus/pGNAndSPN/739?type=PGN)";
CM_ BO_ 2553872384  "Source: isobus.net VDMA Data Dictionary (https://www.isobus.net/isobus/pGNAndSPN/744?type=PGN)";
CM_ BO_ 2553937920  "Source: isobus.net VDMA Data Dictionary (https://www.isobus.net/isobus/pGNAndSPN/748?type=PGN)";
CM_ BO_ 2554003456  "Source: isobus.net VDMA Data Dictionary (https://www.isobus.net/isobus/pGNAndSPN/752?type=PGN)";
CM_ BO_ 2554068992  "Source: isobus.net VDMA Data Dictionary (https://www.isobus.net/isobus/pGNAndSPN/1073?type=PGN)";
CM_ BO_ 2554134528  "Source: isobus.net VDMA Data Dictionary (https://www.isobus.net/isobus/pGNAndSPN/1276?type=PGN)";
CM_ BO_ 2554200064  "Source: isobus.net VDMA Data Dictionary (https://www.isobus.net/isobus/pGNAndSPN/1282?type=PGN)";
CM_ BO_ 2554265600  "Source: isobus.net VDMA Data Dictionary (https://www.isobus.net/isobus/pGNAndSPN/1286?type=PGN)";
CM_ BO_ 2554331136  "Source: isobus.net VDMA Data Dictionary (https://www.isobus.net/isobus/pGNAndSPN/1290?type=PGN)";
CM_ BO_ 2554396672  "Source: isobus.net VDMA Data Dictionary (https://www.isobus.net/isobus/pGNAndSPN/1293?type=PGN)";
CM_ BO_ 2554462208  "Source: isobus.net VDMA Data Dictionary (https://www.isobus.net/isobus/pGNAndSPN/1301?type=PGN)";
CM_ BO_ 2554527744  "Source: isobus.net VDMA Data Dictionary (https://www.isobus.net/isobus/pGNAndSPN/1302?type=PGN)";
CM_ BO_ 2554724352  "Source: isobus.net VDMA Data Dictionary (https://www.isobus.net/isobus/pGNAndSPN/1307?type=PGN)";
CM_ BO_ 2554855424  "Source: isobus.net VDMA Data Dictionary (https://www.isobus.net/isobus/pGNAndSPN/1308?type=PGN)";
CM_ BO_ 2554920960  "Source: isobus.net VDMA Data Dictionary (https://www.isobus.net/isobus/pGNAndSPN/1309?type=PGN)";
CM_ BO_ 2554986496  "Source: isobus.net VDMA Data Dictionary (https://www.isobus.net/isobus/pGNAndSPN/1313?type=PGN)";
CM_ BO_ 2555052032  "Source: isobus.net VDMA Data Dictionary (https://www.isobus.net/isobus/pGNAndSPN/1317?type=PGN)";
CM_ BO_ 2555117568  "Source: isobus.net VDMA Data Dictionary (https://www.isobus.net/isobus/pGNAndSPN/1322?type=PGN)";
CM_ BO_ 2555183104  "Source: isobus.net VDMA Data Dictionary (https://www.isobus.net/isobus/pGNAndSPN/1336?type=PGN)";
CM_ BO_ 2555248640  "Source: isobus.net VDMA Data Dictionary (https://www.isobus.net/isobus/pGNAndSPN/1340?type=PGN)";
CM_ BO_ 2555314176  "Source: isobus.net VDMA Data Dictionary (https://www.isobus.net/isobus/pGNAndSPN/1350?type=PGN)";
CM_ BO_ 2555379712  "Source: isobus.net VDMA Data Dictionary (https://www.isobus.net/isobus/pGNAndSPN/1355?type=PGN)";
CM_ BO_ 2555445248  "Source: isobus.net VDMA Data Dictionary (https://www.isobus.net/isobus/pGNAndSPN/1360?type=PGN)";
CM_ BO_ 2555510784  "Source: isobus.net VDMA Data Dictionary (https://www.isobus.net/isobus/pGNAndSPN/1365?type=PGN)";
CM_ BO_ 2555576320  "Source: isobus.net VDMA Data Dictionary (https://www.isobus.net/isobus/pGNAndSPN/1369?type=PGN)";
CM_ BO_ 2555641856  "Source: isobus.net VDMA Data Dictionary (https://www.isobus.net/isobus/pGNAndSPN/1370?type=PGN)";
CM_ BO_ 2555707392  "Source: isobus.net VDMA Data Dictionary (https://www.isobus.net/isobus/pGNAndSPN/1371?type=PGN)";
CM_ BO_ 2555772928  "Source: isobus.net VDMA Data Dictionary (https://www.isobus.net/isobus/pGNAndSPN/1378?type=PGN)";
CM_ BO_ 2555838464  "Source: isobus.net VDMA Data Dictionary (https://www.isobus.net/isobus/pGNAndSPN/1385?type=PGN)";
CM_ BO_ 2555904000  "Source: isobus.net VDMA Data Dictionary (https://www.isobus.net/isobus/pGNAndSPN/1387?type=PGN)";
CM_ BO_ 2555969536  "Source: isobus.net VDMA Data Dictionary (https://www.isobus.net/isobus/pGNAndSPN/1391?type=PGN)";
CM_ BO_ 2556035072  "Source: isobus.net VDMA Data Dictionary (https://www.isobus.net/isobus/pGNAndSPN/1395?type=PGN)";
CM_ BO_ 2556100608  "Source: isobus.net VDMA Data Dictionary (https://www.isobus.net/isobus/pGNAndSPN/1401?type=PGN)";
CM_ BO_ 2556166144  "Source: isobus.net VDMA Data Dictionary (https://www.isobus.net/isobus/pGNAndSPN/1407?type=PGN)";
CM_ BO_ 2556231680  "Source: isobus.net VDMA Data Dictionary (https://www.isobus.net/isobus/pGNAndSPN/1413?type=PGN)";
CM_ BO_ 2556297216  "Source: isobus.net VDMA Data Dictionary (https://www.isobus.net/isobus/pGNAndSPN/1419?type=PGN)";
CM_ BO_ 2556362752  "Source: isobus.net VDMA Data Dictionary (https://www.isobus.net/isobus/pGNAndSPN/1425?type=PGN)";
CM_ BO_ 2556428288  "Source: isobus.net VDMA Data Dictionary (https://www.isobus.net/isobus/pGNAndSPN/1431?type=PGN)";
CM_ BO_ 2556493824  "Source: isobus.net VDMA Data Dictionary (https://www.isobus.net/isobus/pGNAndSPN/1433?type=PGN)";
CM_ BO_ 2556559360  "Source: isobus.net VDMA Data Dictionary (https://www.isobus.net/isobus/pGNAndSPN/1435?type=PGN)";
CM_ BO_ 2556624896  "Source: isobus.net VDMA Data Dictionary (https://www.isobus.net/isobus/pGNAndSPN/1437?type=PGN)";
CM_ BO_ 2556690432  "Source: isobus.net VDMA Data Dictionary (https://www.isobus.net/isobus/pGNAndSPN/1441?type=PGN)";
CM_ BO_ 2556755968  "Source: isobus.net VDMA Data Dictionary (https://www.isobus.net/isobus/pGNAndSPN/1445?type=PGN)";
CM_ BO_ 2556821504  "Source: isobus.net VDMA Data Dictionary (https://www.isobus.net/isobus/pGNAndSPN/1452?type=PGN)";
CM_ BO_ 2556887040  "Source: isobus.net VDMA Data Dictionary (https://www.isobus.net/isobus/pGNAndSPN/1459?type=PGN)";
CM_ BO_ 2556952576  "Source: isobus.net VDMA Data Dictionary (https://www.isobus.net/isobus/pGNAndSPN/1471?type=PGN)";
CM_ BO_ 2557018112  "Source: isobus.net VDMA Data Dictionary (https://www.isobus.net/isobus/pGNAndSPN/1475?type=PGN)";
CM_ BO_ 2557083648  "Source: isobus.net VDMA Data Dictionary (https://www.isobus.net/isobus/pGNAndSPN/1482?type=PGN)";
CM_ BO_ 2557149184  "Source: isobus.net VDMA Data Dictionary (https://www.isobus.net/isobus/pGNAndSPN/1484?type=PGN)";
CM_ BO_ 2557214720  "Source: isobus.net VDMA Data Dictionary (https://www.isobus.net/isobus/pGNAndSPN/1485?type=PGN)";
CM_ BO_ 2557280256  "Source: isobus.net VDMA Data Dictionary (https://www.isobus.net/isobus/pGNAndSPN/1496?type=PGN)";
CM_ BO_ 2557345792  "Source: isobus.net VDMA Data Dictionary (https://www.isobus.net/isobus/pGNAndSPN/1501?type=PGN)";
CM_ BO_ 2557411328  "Source: isobus.net VDMA Data Dictionary (https://www.isobus.net/isobus/pGNAndSPN/1527?type=PGN)";
CM_ BO_ 2557476864  "Source: isobus.net VDMA Data Dictionary (https://www.isobus.net/isobus/pGNAndSPN/1552?type=PGN)";
CM_ BO_ 2557542400  "Source: isobus.net VDMA Data Dictionary (https://www.isobus.net/isobus/pGNAndSPN/1556?type=PGN)";
CM_ BO_ 2557607936  "Source: isobus.net VDMA Data Dictionary (https://www.isobus.net/isobus/pGNAndSPN/1569?type=PGN)";
CM_ BO_ 2557673472  "Source: isobus.net VDMA Data Dictionary (https://www.isobus.net/isobus/pGNAndSPN/1576?type=PGN)";
CM_ BO_ 2557739008  "Source: isobus.net VDMA Data Dictionary (https://www.isobus.net/isobus/pGNAndSPN/1583?type=PGN)";
CM_ BO_ 2557804544  "Source: isobus.net VDMA Data Dictionary (https://www.isobus.net/isobus/pGNAndSPN/1590?type=PGN)";
CM_ BO_ 2557870080  "Source: isobus.net VDMA Data Dictionary (https://www.isobus.net/isobus/pGNAndSPN/1597?type=PGN)";
CM_ BO_ 2557935616  "Source: isobus.net VDMA Data Dictionary (https://www.isobus.net/isobus/pGNAndSPN/1604?type=PGN)";
CM_ BO_ 2558001152  "Source: isobus.net VDMA Data Dictionary (https://www.isobus.net/isobus/pGNAndSPN/1611?type=PGN)";
CM_ BO_ 2558066688  "Source: isobus.net VDMA Data Dictionary (https://www.isobus.net/isobus/pGNAndSPN/1618?type=PGN)";
CM_ BO_ 2558132224  "Source: isobus.net VDMA Data Dictionary (https://www.isobus.net/isobus/pGNAndSPN/1625?type=PGN)";
CM_ BO_ 2558197760  "Source: isobus.net VDMA Data Dictionary (https://www.isobus.net/isobus/pGNAndSPN/1632?type=PGN)";
CM_ BO_ 2558263296  "Source: isobus.net VDMA Data Dictionary (https://www.isobus.net/isobus/pGNAndSPN/1633?type=PGN)";
CM_ BO_ 2558328832  "Source: isobus.net VDMA Data Dictionary (https://www.isobus.net/isobus/pGNAndSPN/1655?type=PGN)";
CM_ BO_ 2558394368  "Source: isobus.net VDMA Data Dictionary (https://www.isobus.net/isobus/pGNAndSPN/1657?type=PGN)";
CM_ BO_ 2558459904  "Source: isobus.net VDMA Data Dictionary (https://www.isobus.net/isobus/pGNAndSPN/1661?type=PGN)";
CM_ BO_ 2558525440  "Source: isobus.net VDMA Data Dictionary (https://www.isobus.net/isobus/pGNAndSPN/1674?type=PGN)";
CM_ BO_ 2558590976  "Source: isobus.net VDMA Data Dictionary (https://www.isobus.net/isobus/pGNAndSPN/1680?type=PGN)";
CM_ BO_ 2558656512  "Source: isobus.net VDMA Data Dictionary (https://www.isobus.net/isobus/pGNAndSPN/1687?type=PGN)";
CM_ BO_ 2558722048  "Source: isobus.net VDMA Data Dictionary (https://www.isobus.net/isobus/pGNAndSPN/1690?type=PGN)";
CM_ BO_ 2558787584  "Source: isobus.net VDMA Data Dictionary (https://www.isobus.net/isobus/pGNAndSPN/1695?type=PGN)";
CM_ BO_ 2558853120  "Source: isobus.net VDMA Data Dictionary (https://www.isobus.net/isobus/pGNAndSPN/1713?type=PGN)";
CM_ BO_ 2558918656  "Source: isobus.net VDMA Data Dictionary (https://www.isobus.net/isobus/pGNAndSPN/1745?type=PGN)";
CM_ BO_ 2558984192  "Source: isobus.net VDMA Data Dictionary (https://www.isobus.net/isobus/pGNAndSPN/1754?type=PGN)";
CM_ BO_ 2559049728  "Source: isobus.net VDMA Data Dictionary (https://www.isobus.net/isobus/pGNAndSPN/1758?type=PGN)";
CM_ BO_ 2559115264  "Source: isobus.net VDMA Data Dictionary (https://www.isobus.net/isobus/pGNAndSPN/1759?type=PGN)";
CM_ BO_ 2559180800  "Source: isobus.net VDMA Data Dictionary (https://www.isobus.net/isobus/pGNAndSPN/1760?type=PGN)";
CM_ BO_ 2559246336  "Source: isobus.net VDMA Data Dictionary (https://www.isobus.net/isobus/pGNAndSPN/1761?type=PGN)";
CM_ BO_ 2559311872  "Source: isobus.net VDMA Data Dictionary (https://www.isobus.net/isobus/pGNAndSPN/1762?type=PGN)";
CM_ BO_ 2559377408  "Source: isobus.net VDMA Data Dictionary (https://www.isobus.net/isobus/pGNAndSPN/1763?type=PGN)";
CM_ BO_ 2559442944  "Source: isobus.net VDMA Data Dictionary (https://www.isobus.net/isobus/pGNAndSPN/1764?type=PGN)";
CM_ BO_ 2559508480  "Source: isobus.net VDMA Data Dictionary (https://www.isobus.net/isobus/pGNAndSPN/1765?type=PGN)";
CM_ BO_ 2559574016  "Source: isobus.net VDMA Data Dictionary (https://www.isobus.net/isobus/pGNAndSPN/1769?type=PGN)";
CM_ BO_ 2559639552  "Source: isobus.net VDMA Data Dictionary (https://www.isobus.net/isobus/pGNAndSPN/1774?type=PGN)";
CM_ BO_ 2559705088  "Source: isobus.net VDMA Data Dictionary (https://www.isobus.net/isobus/pGNAndSPN/1780?type=PGN)";
CM_ BO_ 2559770624  "Source: isobus.net VDMA Data Dictionary (https://www.isobus.net/isobus/pGNAndSPN/1798?type=PGN)";
CM_ BO_ 2559836160  "Source: isobus.net VDMA Data Dictionary (https://www.isobus.net/isobus/pGNAndSPN/1800?type=PGN)";
CM_ BO_ 2559901696  "Source: isobus.net VDMA Data Dictionary (https://www.isobus.net/isobus/pGNAndSPN/1802?type=PGN)";
CM_ BO_ 2559967232  "Source: isobus.net VDMA Data Dictionary (https://www.isobus.net/isobus/pGNAndSPN/1803?type=PGN)";
CM_ BO_ 2560032768  "Source: isobus.net VDMA Data Dictionary (https://www.isobus.net/isobus/pGNAndSPN/1805?type=PGN)";
CM_ BO_ 2560098304  "Source: isobus.net VDMA Data Dictionary (https://www.isobus.net/isobus/pGNAndSPN/1807?type=PGN)";
CM_ BO_ 2560163840  "Source: isobus.net VDMA Data Dictionary (https://www.isobus.net/isobus/pGNAndSPN/1837?type=PGN)";
CM_ BO_ 2560229376  "Source: isobus.net VDMA Data Dictionary (https://www.isobus.net/isobus/pGNAndSPN/1838?type=PGN)";
CM_ BO_ 2560360448  "Source: isobus.net VDMA Data Dictionary (https://www.isobus.net/isobus/pGNAndSPN/1848?type=PGN)";
CM_ BO_ 2560425984  "Source: isobus.net VDMA Data Dictionary (https://www.isobus.net/isobus/pGNAndSPN/1856?type=PGN)";
CM_ BO_ 2560491520  "Source: isobus.net VDMA Data Dictionary (https://www.isobus.net/isobus/pGNAndSPN/1861?type=PGN)";
CM_ BO_ 2560557056  "Source: isobus.net VDMA Data Dictionary (https://www.isobus.net/isobus/pGNAndSPN/1873?type=PGN)";
CM_ BO_ 2560622592  "Source: isobus.net VDMA Data Dictionary (https://www.isobus.net/isobus/pGNAndSPN/1879?type=PGN)";
CM_ BO_ 2560688128  "Source: isobus.net VDMA Data Dictionary (https://www.isobus.net/isobus/pGNAndSPN/1882?type=PGN)";
CM_ BO_ 2560753664  "Source: isobus.net VDMA Data Dictionary (https://www.isobus.net/isobus/pGNAndSPN/1887?type=PGN)";
CM_ BO_ 2560819200  "Source: isobus.net VDMA Data Dictionary (https://www.isobus.net/isobus/pGNAndSPN/1899?type=PGN)";
CM_ BO_ 2560884736  "Source: isobus.net VDMA Data Dictionary (https://www.isobus.net/isobus/pGNAndSPN/1906?type=PGN)";
CM_ BO_ 2560950272  "Source: isobus.net VDMA Data Dictionary (https://www.isobus.net/isobus/pGNAndSPN/1938?type=PGN)";
CM_ BO_ 2561015808  "Source: isobus.net VDMA Data Dictionary (https://www.isobus.net/isobus/pGNAndSPN/1970?type=PGN)";
CM_ BO_ 2561081344  "Source: isobus.net VDMA Data Dictionary (https://www.isobus.net/isobus/pGNAndSPN/2002?type=PGN)";
CM_ BO_ 2561146880  "Source: isobus.net VDMA Data Dictionary (https://www.isobus.net/isobus/pGNAndSPN/2005?type=PGN)";
CM_ BO_ 2561212416  "Source: isobus.net VDMA Data Dictionary (https://www.isobus.net/isobus/pGNAndSPN/2011?type=PGN)";
CM_ BO_ 2561277952  "Source: isobus.net VDMA Data Dictionary (https://www.isobus.net/isobus/pGNAndSPN/2012?type=PGN)";
CM_ BO_ 2561343488  "Source: isobus.net VDMA Data Dictionary (https://www.isobus.net/isobus/pGNAndSPN/2013?type=PGN)";
CM_ BO_ 2561540096  "Source: isobus.net VDMA Data Dictionary (https://www.isobus.net/isobus/pGNAndSPN/2025?type=PGN)";
CM_ BO_ 2561605632  "Source: isobus.net VDMA Data Dictionary (https://www.isobus.net/isobus/pGNAndSPN/2026?type=PGN)";
CM_ BO_ 2561671168  "Source: isobus.net VDMA Data Dictionary (https://www.isobus.net/isobus/pGNAndSPN/2027?type=PGN)";
CM_ BO_ 2561736704  "Source: isobus.net VDMA Data Dictionary (https://www.isobus.net/isobus/pGNAndSPN/2028?type=PGN)";
CM_ BO_ 2561802240  "Source: isobus.net VDMA Data Dictionary (https://www.isobus.net/isobus/pGNAndSPN/2029?type=PGN)";
CM_ BO_ 2561867776  "Source: isobus.net VDMA Data Dictionary (https://www.isobus.net/isobus/pGNAndSPN/2030?type=PGN)";
CM_ BO_ 2561933312  "Source: isobus.net VDMA Data Dictionary (https://www.isobus.net/isobus/pGNAndSPN/2031?type=PGN)";
CM_ BO_ 2561998848  "Source: isobus.net VDMA Data Dictionary (https://www.isobus.net/isobus/pGNAndSPN/2032?type=PGN)";
CM_ BO_ 2562064384  "Source: isobus.net VDMA Data Dictionary (https://www.isobus.net/isobus/pGNAndSPN/2033?type=PGN)";
CM_ BO_ 2562129920  "Source: isobus.net VDMA Data Dictionary (https://www.isobus.net/isobus/pGNAndSPN/2034?type=PGN)";
CM_ BO_ 2562195456  "Source: isobus.net VDMA Data Dictionary (https://www.isobus.net/isobus/pGNAndSPN/2035?type=PGN)";
CM_ BO_ 2562260992  "Source: isobus.net VDMA Data Dictionary (https://www.isobus.net/isobus/pGNAndSPN/2036?type=PGN)";
CM_ BO_ 2562326528  "Source: isobus.net VDMA Data Dictionary (https://www.isobus.net/isobus/pGNAndSPN/2037?type=PGN)";
CM_ BO_ 2562392064  "Source: isobus.net VDMA Data Dictionary (https://www.isobus.net/isobus/pGNAndSPN/2038?type=PGN)";
CM_ BO_ 2562457600  "Source: isobus.net VDMA Data Dictionary (https://www.isobus.net/isobus/pGNAndSPN/2039?type=PGN)";
CM_ BO_ 2562523136  "Source: isobus.net VDMA Data Dictionary (https://www.isobus.net/isobus/pGNAndSPN/2040?type=PGN)";
CM_ BO_ 2562588672  "Source: isobus.net VDMA Data Dictionary (https://www.isobus.net/isobus/pGNAndSPN/2041?type=PGN)";
CM_ BO_ 2562654208  "Source: isobus.net VDMA Data Dictionary (https://www.isobus.net/isobus/pGNAndSPN/2042?type=PGN)";
CM_ BO_ 2562719744  "Source: isobus.net VDMA Data Dictionary (https://www.isobus.net/isobus/pGNAndSPN/2043?type=PGN)";
CM_ BO_ 2562785280  "Source: isobus.net VDMA Data Dictionary (https://www.isobus.net/isobus/pGNAndSPN/2047?type=PGN)";
CM_ BO_ 2562850816  "Source: isobus.net VDMA Data Dictionary (https://www.isobus.net/isobus/pGNAndSPN/2052?type=PGN)";
CM_ BO_ 2562981888  "Source: isobus.net VDMA Data Dictionary (https://www.isobus.net/isobus/pGNAndSPN/2060?type=PGN)";
CM_ BO_ 2563047424  "Source: isobus.net VDMA Data Dictionary (https://www.isobus.net/isobus/pGNAndSPN/2066?type=PGN)";
CM_ BO_ 2563112960  "Source: isobus.net VDMA Data Dictionary (https://www.isobus.net/isobus/pGNAndSPN/2074?type=PGN)";
CM_ BO_ 2563309568  "Source: isobus.net VDMA Data Dictionary (https://www.isobus.net/isobus/pGNAndSPN/2082?type=PGN)";
CM_ BO_ 2563375104  "Source: isobus.net VDMA Data Dictionary (https://www.isobus.net/isobus/pGNAndSPN/2086?type=PGN)";
CM_ BO_ 2563702784  "Source: isobus.net VDMA Data Dictionary (https://www.isobus.net/isobus/pGNAndSPN/2102?type=PGN)";
CM_ BO_ 2563768320  "Source: isobus.net VDMA Data Dictionary (https://www.isobus.net/isobus/pGNAndSPN/2103?type=PGN)";
CM_ BO_ 2563833856  "Source: isobus.net VDMA Data Dictionary (https://www.isobus.net/isobus/pGNAndSPN/2107?type=PGN)";
CM_ BO_ 2563899392  "Source: isobus.net VDMA Data Dictionary (https://www.isobus.net/isobus/pGNAndSPN/2126?type=PGN)";
CM_ BO_ 2563964928  "Source: isobus.net VDMA Data Dictionary (https://www.isobus.net/isobus/pGNAndSPN/2128?type=PGN)";
CM_ BO_ 2564030464  "Source: isobus.net VDMA Data Dictionary (https://www.isobus.net/isobus/pGNAndSPN/2131?type=PGN)";
CM_ BO_ 2564096000  "Source: isobus.net VDMA Data Dictionary (https://www.isobus.net/isobus/pGNAndSPN/2139?type=PGN)";
CM_ BO_ 2564161536  "Source: isobus.net VDMA Data Dictionary (https://www.isobus.net/isobus/pGNAndSPN/2140?type=PGN)";
CM_ BO_ 2564554752  "Source: isobus.net VDMA Data Dictionary (https://www.isobus.net/isobus/pGNAndSPN/2160?type=PGN)";
CM_ BO_ 2564620288  "Source: isobus.net VDMA Data Dictionary (https://www.isobus.net/isobus/pGNAndSPN/2164?type=PGN)";
CM_ BO_ 2564685824  "Source: isobus.net VDMA Data Dictionary (https://www.isobus.net/isobus/pGNAndSPN/2175?type=PGN)";
CM_ BO_ 2564816896  "Source: isobus.net VDMA Data Dictionary (https://www.isobus.net/isobus/pGNAndSPN/2208?type=PGN)";
CM_ BO_ 2564882432  "Source: isobus.net VDMA Data Dictionary (https://www.isobus.net/isobus/pGNAndSPN/2209?type=PGN)";
CM_ BO_ 2564947968  "Source: isobus.net VDMA Data Dictionary (https://www.isobus.net/isobus/pGNAndSPN/2210?type=PGN)";
CM_ BO_ 2565013504  "Source: isobus.net VDMA Data Dictionary (https://www.isobus.net/isobus/pGNAndSPN/2213?type=PGN)";
CM_ BO_ 2565079040  "Source: isobus.net VDMA Data Dictionary (https://www.isobus.net/isobus/pGNAndSPN/2214?type=PGN)";
CM_ BO_ 2565144576  "Source: isobus.net VDMA Data Dictionary (https://www.isobus.net/isobus/pGNAndSPN/2215?type=PGN)";
CM_ BO_ 2565668864  "Source: isobus.net VDMA Data Dictionary (https://www.isobus.net/isobus/pGNAndSPN/2269?type=PGN)";
CM_ BO_ 2565865472  "Source: isobus.net VDMA Data Dictionary (https://www.isobus.net/isobus/pGNAndSPN/2284?type=PGN)";
CM_ BO_ 2565865728  "Source: isobus.net VDMA Data Dictionary (https://www.isobus.net/isobus/pGNAndSPN/2307?type=PGN)";
CM_ BO_ 2565865984  "Source: isobus.net VDMA Data Dictionary (https://www.isobus.net/isobus/pGNAndSPN/2318?type=PGN)";
CM_ BO_ 2565866752  "Source: isobus.net VDMA Data Dictionary (https://www.isobus.net/isobus/pGNAndSPN/2345?type=PGN)";
CM_ BO_ 2565867008  "Source: isobus.net VDMA Data Dictionary (https://www.isobus.net/isobus/pGNAndSPN/2357?type=PGN)";
CM_ BO_ 2565867264  "Source: isobus.net VDMA Data Dictionary (https://www.isobus.net/isobus/pGNAndSPN/2368?type=PGN)";
CM_ BO_ 2565867520  "Source: isobus.net VDMA Data Dictionary (https://www.isobus.net/isobus/pGNAndSPN/2379?type=PGN)";
CM_ BO_ 2565867776  "Source: isobus.net VDMA Data Dictionary (https://www.isobus.net/isobus/pGNAndSPN/2385?type=PGN)";
CM_ BO_ 2565868032  "Source: isobus.net VDMA Data Dictionary (https://www.isobus.net/isobus/pGNAndSPN/2389?type=PGN)";
CM_ BO_ 2565868288  "Source: isobus.net VDMA Data Dictionary (https://www.isobus.net/isobus/pGNAndSPN/2396?type=PGN)";
CM_ BO_ 2565868544  "Source: isobus.net VDMA Data Dictionary (https://www.isobus.net/isobus/pGNAndSPN/2402?type=PGN)";
CM_ BO_ 2565868800  "Source: isobus.net VDMA Data Dictionary (https://www.isobus.net/isobus/pGNAndSPN/2413?type=PGN)";
CM_ BO_ 2565869056  "Source: isobus.net VDMA Data Dictionary (https://www.isobus.net/isobus/pGNAndSPN/2424?type=PGN)";
CM_ BO_ 2565869312  "Source: isobus.net VDMA Data Dictionary (https://www.isobus.net/isobus/pGNAndSPN/2435?type=PGN)";
CM_ BO_ 2565869568  "Source: isobus.net VDMA Data Dictionary (https://www.isobus.net/isobus/pGNAndSPN/2447?type=PGN)";
CM_ BO_ 2565869824  "Source: isobus.net VDMA Data Dictionary (https://www.isobus.net/isobus/pGNAndSPN/2459?type=PGN)";
CM_ BO_ 2565870080  "Source: isobus.net VDMA Data Dictionary (https://www.isobus.net/isobus/pGNAndSPN/2463?type=PGN)";
CM_ BO_ 2565870336  "Source: isobus.net VDMA Data Dictionary (https://www.isobus.net/isobus/pGNAndSPN/2471?type=PGN)";
CM_ BO_ 2565870592  "Source: isobus.net VDMA Data Dictionary (https://www.isobus.net/isobus/pGNAndSPN/2476?type=PGN)";
CM_ BO_ 2565870848  "Source: isobus.net VDMA Data Dictionary (https://www.isobus.net/isobus/pGNAndSPN/2479?type=PGN)";
CM_ BO_ 2565871104  "Source: isobus.net VDMA Data Dictionary (https://www.isobus.net/isobus/pGNAndSPN/2503?type=PGN)";
CM_ BO_ 2565871360  "Source: isobus.net VDMA Data Dictionary (https://www.isobus.net/isobus/pGNAndSPN/2511?type=PGN)";
CM_ BO_ 2565871616  "Source: isobus.net VDMA Data Dictionary (https://www.isobus.net/isobus/pGNAndSPN/2519?type=PGN)";
CM_ BO_ 2565871872  "Source: isobus.net VDMA Data Dictionary (https://www.isobus.net/isobus/pGNAndSPN/2527?type=PGN)";
CM_ BO_ 2565872128  "Source: isobus.net VDMA Data Dictionary (https://www.isobus.net/isobus/pGNAndSPN/2531?type=PGN)";
CM_ BO_ 2565872384  "Source: isobus.net VDMA Data Dictionary (https://www.isobus.net/isobus/pGNAndSPN/2532?type=PGN)";
CM_ BO_ 2565872640  "Source: isobus.net VDMA Data Dictionary (https://www.isobus.net/isobus/pGNAndSPN/2533?type=PGN)";
CM_ BO_ 2565872896  "Source: isobus.net VDMA Data Dictionary (https://www.isobus.net/isobus/pGNAndSPN/2541?type=PGN)";
CM_ BO_ 2565873152  "Source: isobus.net VDMA Data Dictionary (https://www.isobus.net/isobus/pGNAndSPN/2544?type=PGN)";
CM_ BO_ 2565873408  "Source: isobus.net VDMA Data Dictionary (https://www.isobus.net/isobus/pGNAndSPN/2545?type=PGN)";
CM_ BO_ 2565873664  "Source: isobus.net VDMA Data Dictionary (https://www.isobus.net/isobus/pGNAndSPN/2546?type=PGN)";
CM_ BO_ 2565873920  "Source: isobus.net VDMA Data Dictionary (https://www.isobus.net/isobus/pGNAndSPN/2552?type=PGN)";
CM_ BO_ 2565874432  "Source: isobus.net VDMA Data Dictionary (https://www.isobus.net/isobus/pGNAndSPN/2564?type=PGN)";
CM_ BO_ 2565874688  "Source: isobus.net VDMA Data Dictionary (https://www.isobus.net/isobus/pGNAndSPN/2570?type=PGN)";
CM_ BO_ 2565874944  "Source: isobus.net VDMA Data Dictionary (https://www.isobus.net/isobus/pGNAndSPN/2577?type=PGN)";
CM_ BO_ 2565875200  "Source: isobus.net VDMA Data Dictionary (https://www.isobus.net/isobus/pGNAndSPN/2583?type=PGN)";
CM_ BO_ 2565875456  "Source: isobus.net VDMA Data Dictionary (https://www.isobus.net/isobus/pGNAndSPN/2590?type=PGN)";

CM_ SG_ 2550202368 Transmission_Control_1_RawPayloa "Generic 8-byte raw payload. Detail page: https://www.isobus.net/isobus/pGNAndSPN/38?type=PGN. Signal-level enrichment via PR welcome  see CONTRIBUTING.md.";
CM_ SG_ 2550267904 Electronic_Brake_System_1_1_RawP "Generic 8-byte raw payload. Detail page: https://www.isobus.net/isobus/pGNAndSPN/39?type=PGN. Signal-level enrichment via PR welcome  see CONTRIBUTING.md.";
CM_ SG_ 2550333440 Electronic_Brake_System_2_1_RawP "Generic 8-byte raw payload. Detail page: https://www.isobus.net/isobus/pGNAndSPN/40?type=PGN. Signal-level enrichment via PR welcome  see CONTRIBUTING.md.";
CM_ SG_ 2550398976 External_Brake_Request_RawPayloa "Generic 8-byte raw payload. Detail page: https://www.isobus.net/isobus/pGNAndSPN/50?type=PGN. Signal-level enrichment via PR welcome  see CONTRIBUTING.md.";
CM_ SG_ 2550464512 CANopen_Application_Message_1_1_ "Generic 8-byte raw payload. Detail page: https://www.isobus.net/isobus/pGNAndSPN/51?type=PGN. Signal-level enrichment via PR welcome  see CONTRIBUTING.md.";
CM_ SG_ 2550530048 CANopen_Application_Message_2_1_ "Generic 8-byte raw payload. Detail page: https://www.isobus.net/isobus/pGNAndSPN/52?type=PGN. Signal-level enrichment via PR welcome  see CONTRIBUTING.md.";
CM_ SG_ 2550595584 General_Purpose_Valve_Pressure_R "Generic 8-byte raw payload. Detail page: https://www.isobus.net/isobus/pGNAndSPN/57?type=PGN. Signal-level enrichment via PR welcome  see CONTRIBUTING.md.";
CM_ SG_ 2550661120 Auxiliary_Input_Output_Status_5_ "Generic 8-byte raw payload. Detail page: https://www.isobus.net/isobus/pGNAndSPN/61?type=PGN. Signal-level enrichment via PR welcome  see CONTRIBUTING.md.";
CM_ SG_ 2550726656 Static_Roll_Angle_Sensor_Informa "Generic 8-byte raw payload. Detail page: https://www.isobus.net/isobus/pGNAndSPN/63?type=PGN. Signal-level enrichment via PR welcome  see CONTRIBUTING.md.";
CM_ SG_ 2550792192 Cruise_Control_Vehicle_Speed_2_R "Generic 8-byte raw payload. Detail page: https://www.isobus.net/isobus/pGNAndSPN/71?type=PGN. Signal-level enrichment via PR welcome  see CONTRIBUTING.md.";
CM_ SG_ 2550857728 Advanced_Emergency_Braking_Syste "Generic 8-byte raw payload. Detail page: https://www.isobus.net/isobus/pGNAndSPN/74?type=PGN. Signal-level enrichment via PR welcome  see CONTRIBUTING.md.";
CM_ SG_ 2550923264 Electronic_Engine_Controller_16_ "Generic 8-byte raw payload. Detail page: https://www.isobus.net/isobus/pGNAndSPN/77?type=PGN. Signal-level enrichment via PR welcome  see CONTRIBUTING.md.";
CM_ SG_ 2550988800 Transmission_Control_2_RawPayloa "Generic 8-byte raw payload. Detail page: https://www.isobus.net/isobus/pGNAndSPN/96?type=PGN. Signal-level enrichment via PR welcome  see CONTRIBUTING.md.";
CM_ SG_ 2551054336 Safety_Header_Message_RawPayload "Generic 8-byte raw payload. Detail page: https://www.isobus.net/isobus/pGNAndSPN/103?type=PGN. Signal-level enrichment via PR welcome  see CONTRIBUTING.md.";
CM_ SG_ 2551119872 High_Voltage_Energy_Storage_Pack "Generic 8-byte raw payload. Detail page: https://www.isobus.net/isobus/pGNAndSPN/115?type=PGN. Signal-level enrichment via PR welcome  see CONTRIBUTING.md.";
CM_ SG_ 2551185408 High_Voltage_Energy_Storage_Pack "Generic 8-byte raw payload. Detail page: https://www.isobus.net/isobus/pGNAndSPN/127?type=PGN. Signal-level enrichment via PR welcome  see CONTRIBUTING.md.";
CM_ SG_ 2551250944 High_Voltage_Energy_Storage_Pack "Generic 8-byte raw payload. Detail page: https://www.isobus.net/isobus/pGNAndSPN/139?type=PGN. Signal-level enrichment via PR welcome  see CONTRIBUTING.md.";
CM_ SG_ 2551316480 High_Voltage_Energy_Storage_Pack "Generic 8-byte raw payload. Detail page: https://www.isobus.net/isobus/pGNAndSPN/151?type=PGN. Signal-level enrichment via PR welcome  see CONTRIBUTING.md.";
CM_ SG_ 2551382016 High_Voltage_Energy_Storage_Pack "Generic 8-byte raw payload. Detail page: https://www.isobus.net/isobus/pGNAndSPN/163?type=PGN. Signal-level enrichment via PR welcome  see CONTRIBUTING.md.";
CM_ SG_ 2551447552 High_Voltage_Energy_Storage_Pack "Generic 8-byte raw payload. Detail page: https://www.isobus.net/isobus/pGNAndSPN/175?type=PGN. Signal-level enrichment via PR welcome  see CONTRIBUTING.md.";
CM_ SG_ 2551513088 High_Voltage_Energy_Storage_Pack "Generic 8-byte raw payload. Detail page: https://www.isobus.net/isobus/pGNAndSPN/187?type=PGN. Signal-level enrichment via PR welcome  see CONTRIBUTING.md.";
CM_ SG_ 2551578624 High_Voltage_Energy_Storage_Pack "Generic 8-byte raw payload. Detail page: https://www.isobus.net/isobus/pGNAndSPN/199?type=PGN. Signal-level enrichment via PR welcome  see CONTRIBUTING.md.";
CM_ SG_ 2551644160 High_Voltage_Energy_Storage_Pack "Generic 8-byte raw payload. Detail page: https://www.isobus.net/isobus/pGNAndSPN/211?type=PGN. Signal-level enrichment via PR welcome  see CONTRIBUTING.md.";
CM_ SG_ 2551709696 High_Voltage_Energy_Storage_Pack "Generic 8-byte raw payload. Detail page: https://www.isobus.net/isobus/pGNAndSPN/223?type=PGN. Signal-level enrichment via PR welcome  see CONTRIBUTING.md.";
CM_ SG_ 2551775232 High_Voltage_Energy_Storage_Pack "Generic 8-byte raw payload. Detail page: https://www.isobus.net/isobus/pGNAndSPN/235?type=PGN. Signal-level enrichment via PR welcome  see CONTRIBUTING.md.";
CM_ SG_ 2551840768 High_Voltage_Energy_Storage_Pack "Generic 8-byte raw payload. Detail page: https://www.isobus.net/isobus/pGNAndSPN/247?type=PGN. Signal-level enrichment via PR welcome  see CONTRIBUTING.md.";
CM_ SG_ 2551906304 High_Voltage_Energy_Storage_Syst "Generic 8-byte raw payload. Detail page: https://www.isobus.net/isobus/pGNAndSPN/259?type=PGN. Signal-level enrichment via PR welcome  see CONTRIBUTING.md.";
CM_ SG_ 2551971840 Transmission_Control_3_Obsolete_ "Generic 8-byte raw payload. Detail page: https://www.isobus.net/isobus/pGNAndSPN/267?type=PGN. Signal-level enrichment via PR welcome  see CONTRIBUTING.md.";
CM_ SG_ 2552037376 Engine_Ignition_Controller_RawPa "Generic 8-byte raw payload. Detail page: https://www.isobus.net/isobus/pGNAndSPN/268?type=PGN. Signal-level enrichment via PR welcome  see CONTRIBUTING.md.";
CM_ SG_ 2552102912 Alternator_Control_RawPayload "Generic 8-byte raw payload. Detail page: https://www.isobus.net/isobus/pGNAndSPN/272?type=PGN. Signal-level enrichment via PR welcome  see CONTRIBUTING.md.";
CM_ SG_ 2552168448 High_Voltage_Energy_Storage_Pack "Generic 8-byte raw payload. Detail page: https://www.isobus.net/isobus/pGNAndSPN/284?type=PGN. Signal-level enrichment via PR welcome  see CONTRIBUTING.md.";
CM_ SG_ 2552233984 High_Voltage_Energy_Storage_Pack "Generic 8-byte raw payload. Detail page: https://www.isobus.net/isobus/pGNAndSPN/296?type=PGN. Signal-level enrichment via PR welcome  see CONTRIBUTING.md.";
CM_ SG_ 2552299520 High_Voltage_Energy_Storage_Pack "Generic 8-byte raw payload. Detail page: https://www.isobus.net/isobus/pGNAndSPN/308?type=PGN. Signal-level enrichment via PR welcome  see CONTRIBUTING.md.";
CM_ SG_ 2552365056 High_Voltage_Energy_Storage_Pack "Generic 8-byte raw payload. Detail page: https://www.isobus.net/isobus/pGNAndSPN/320?type=PGN. Signal-level enrichment via PR welcome  see CONTRIBUTING.md.";
CM_ SG_ 2552430592 Tractor_Implement_Management_TIM "Generic 8-byte raw payload. Detail page: https://www.isobus.net/isobus/pGNAndSPN/494?type=PGN. Signal-level enrichment via PR welcome  see CONTRIBUTING.md.";
CM_ SG_ 2552496128 Tractor_Implement_Management_TIM "Generic 8-byte raw payload. Detail page: https://www.isobus.net/isobus/pGNAndSPN/584?type=PGN. Signal-level enrichment via PR welcome  see CONTRIBUTING.md.";
CM_ SG_ 2552561664 Multi_PG_RawPayload "Generic 8-byte raw payload. Detail page: https://www.isobus.net/isobus/pGNAndSPN/590?type=PGN. Signal-level enrichment via PR welcome  see CONTRIBUTING.md.";
CM_ SG_ 2552627200 Motor_Generator_1_Inverter_Contr "Generic 8-byte raw payload. Detail page: https://www.isobus.net/isobus/pGNAndSPN/598?type=PGN. Signal-level enrichment via PR welcome  see CONTRIBUTING.md.";
CM_ SG_ 2552692736 Motor_Generator_2_Inverter_Contr "Generic 8-byte raw payload. Detail page: https://www.isobus.net/isobus/pGNAndSPN/606?type=PGN. Signal-level enrichment via PR welcome  see CONTRIBUTING.md.";
CM_ SG_ 2552758272 Motor_Generator_1_Inverter_Rate_ "Generic 8-byte raw payload. Detail page: https://www.isobus.net/isobus/pGNAndSPN/610?type=PGN. Signal-level enrichment via PR welcome  see CONTRIBUTING.md.";
CM_ SG_ 2552823808 Motor_Generator_2_Inverter_Rate_ "Generic 8-byte raw payload. Detail page: https://www.isobus.net/isobus/pGNAndSPN/614?type=PGN. Signal-level enrichment via PR welcome  see CONTRIBUTING.md.";
CM_ SG_ 2552889344 High_Voltage_Energy_Storage_Pack "Generic 8-byte raw payload. Detail page: https://www.isobus.net/isobus/pGNAndSPN/626?type=PGN. Signal-level enrichment via PR welcome  see CONTRIBUTING.md.";
CM_ SG_ 2552954880 High_Voltage_Energy_Storage_Pack "Generic 8-byte raw payload. Detail page: https://www.isobus.net/isobus/pGNAndSPN/638?type=PGN. Signal-level enrichment via PR welcome  see CONTRIBUTING.md.";
CM_ SG_ 2553020416 High_Voltage_Energy_Storage_Pack "Generic 8-byte raw payload. Detail page: https://www.isobus.net/isobus/pGNAndSPN/650?type=PGN. Signal-level enrichment via PR welcome  see CONTRIBUTING.md.";
CM_ SG_ 2553085952 High_Voltage_Energy_Storage_Pack "Generic 8-byte raw payload. Detail page: https://www.isobus.net/isobus/pGNAndSPN/662?type=PGN. Signal-level enrichment via PR welcome  see CONTRIBUTING.md.";
CM_ SG_ 2553151488 High_Voltage_Energy_Storage_Pack "Generic 8-byte raw payload. Detail page: https://www.isobus.net/isobus/pGNAndSPN/674?type=PGN. Signal-level enrichment via PR welcome  see CONTRIBUTING.md.";
CM_ SG_ 2553217024 High_Voltage_Energy_Storage_Pack "Generic 8-byte raw payload. Detail page: https://www.isobus.net/isobus/pGNAndSPN/686?type=PGN. Signal-level enrichment via PR welcome  see CONTRIBUTING.md.";
CM_ SG_ 2553282560 High_Voltage_Energy_Storage_Pack "Generic 8-byte raw payload. Detail page: https://www.isobus.net/isobus/pGNAndSPN/698?type=PGN. Signal-level enrichment via PR welcome  see CONTRIBUTING.md.";
CM_ SG_ 2553348096 High_Voltage_Energy_Storage_Pack "Generic 8-byte raw payload. Detail page: https://www.isobus.net/isobus/pGNAndSPN/710?type=PGN. Signal-level enrichment via PR welcome  see CONTRIBUTING.md.";
CM_ SG_ 2553413632 High_Voltage_Energy_Storage_Pack "Generic 8-byte raw payload. Detail page: https://www.isobus.net/isobus/pGNAndSPN/722?type=PGN. Signal-level enrichment via PR welcome  see CONTRIBUTING.md.";
CM_ SG_ 2553479168 High_Voltage_Energy_Storage_Pack "Generic 8-byte raw payload. Detail page: https://www.isobus.net/isobus/pGNAndSPN/734?type=PGN. Signal-level enrichment via PR welcome  see CONTRIBUTING.md.";
CM_ SG_ 2553544704 Reliable_Long_Message_RawPayload "Generic 8-byte raw payload. Detail page: https://www.isobus.net/isobus/pGNAndSPN/735?type=PGN. Signal-level enrichment via PR welcome  see CONTRIBUTING.md.";
CM_ SG_ 2553610240 Reliable_Short_Message_RawPayloa "Generic 8-byte raw payload. Detail page: https://www.isobus.net/isobus/pGNAndSPN/736?type=PGN. Signal-level enrichment via PR welcome  see CONTRIBUTING.md.";
CM_ SG_ 2553675776 Unreliable_Message_RawPayload "Generic 8-byte raw payload. Detail page: https://www.isobus.net/isobus/pGNAndSPN/737?type=PGN. Signal-level enrichment via PR welcome  see CONTRIBUTING.md.";
CM_ SG_ 2553741312 Message_Acknowledgement_RawPaylo "Generic 8-byte raw payload. Detail page: https://www.isobus.net/isobus/pGNAndSPN/738?type=PGN. Signal-level enrichment via PR welcome  see CONTRIBUTING.md.";
CM_ SG_ 2553806848 Version_Negotiation_Section_RawP "Generic 8-byte raw payload. Detail page: https://www.isobus.net/isobus/pGNAndSPN/739?type=PGN. Signal-level enrichment via PR welcome  see CONTRIBUTING.md.";
CM_ SG_ 2553872384 External_ACC_Acceleration_Reques "Generic 8-byte raw payload. Detail page: https://www.isobus.net/isobus/pGNAndSPN/744?type=PGN. Signal-level enrichment via PR welcome  see CONTRIBUTING.md.";
CM_ SG_ 2553937920 Battery_Charger_1_Command_1_RawP "Generic 8-byte raw payload. Detail page: https://www.isobus.net/isobus/pGNAndSPN/748?type=PGN. Signal-level enrichment via PR welcome  see CONTRIBUTING.md.";
CM_ SG_ 2554003456 Battery_Charger_2_Command_1_RawP "Generic 8-byte raw payload. Detail page: https://www.isobus.net/isobus/pGNAndSPN/752?type=PGN. Signal-level enrichment via PR welcome  see CONTRIBUTING.md.";
CM_ SG_ 2554068992 Tractor_Implement_Management_TIM "Generic 8-byte raw payload. Detail page: https://www.isobus.net/isobus/pGNAndSPN/1073?type=PGN. Signal-level enrichment via PR welcome  see CONTRIBUTING.md.";
CM_ SG_ 2554134528 Tractor_Implement_Management_TIM "Generic 8-byte raw payload. Detail page: https://www.isobus.net/isobus/pGNAndSPN/1276?type=PGN. Signal-level enrichment via PR welcome  see CONTRIBUTING.md.";
CM_ SG_ 2554200064 Fuel_Cell_System_Control_Command "Generic 8-byte raw payload. Detail page: https://www.isobus.net/isobus/pGNAndSPN/1282?type=PGN. Signal-level enrichment via PR welcome  see CONTRIBUTING.md.";
CM_ SG_ 2554265600 Fuel_Cell_System_Power_Limit_Com "Generic 8-byte raw payload. Detail page: https://www.isobus.net/isobus/pGNAndSPN/1286?type=PGN. Signal-level enrichment via PR welcome  see CONTRIBUTING.md.";
CM_ SG_ 2554331136 Fuel_Cell_System_Current_Limit_C "Generic 8-byte raw payload. Detail page: https://www.isobus.net/isobus/pGNAndSPN/1290?type=PGN. Signal-level enrichment via PR welcome  see CONTRIBUTING.md.";
CM_ SG_ 2554396672 Hydrogen_Storage_System_Control_ "Generic 8-byte raw payload. Detail page: https://www.isobus.net/isobus/pGNAndSPN/1293?type=PGN. Signal-level enrichment via PR welcome  see CONTRIBUTING.md.";
CM_ SG_ 2554462208 Transmission_Control_4_RawPayloa "Generic 8-byte raw payload. Detail page: https://www.isobus.net/isobus/pGNAndSPN/1301?type=PGN. Signal-level enrichment via PR welcome  see CONTRIBUTING.md.";
CM_ SG_ 2554527744 Safety_Header_Message_2_RawPaylo "Generic 8-byte raw payload. Detail page: https://www.isobus.net/isobus/pGNAndSPN/1302?type=PGN. Signal-level enrichment via PR welcome  see CONTRIBUTING.md.";
CM_ SG_ 2554724352 API_Select_RawPayload "Generic 8-byte raw payload. Detail page: https://www.isobus.net/isobus/pGNAndSPN/1307?type=PGN. Signal-level enrichment via PR welcome  see CONTRIBUTING.md.";
CM_ SG_ 2554855424 Tractor_Implement_Management_TIM "Generic 8-byte raw payload. Detail page: https://www.isobus.net/isobus/pGNAndSPN/1308?type=PGN. Signal-level enrichment via PR welcome  see CONTRIBUTING.md.";
CM_ SG_ 2554920960 Tractor_Implement_Management_TIM "Generic 8-byte raw payload. Detail page: https://www.isobus.net/isobus/pGNAndSPN/1309?type=PGN. Signal-level enrichment via PR welcome  see CONTRIBUTING.md.";
CM_ SG_ 2554986496 EV_Multi_Connection_DC_Status_1_ "Generic 8-byte raw payload. Detail page: https://www.isobus.net/isobus/pGNAndSPN/1313?type=PGN. Signal-level enrichment via PR welcome  see CONTRIBUTING.md.";
CM_ SG_ 2555052032 EV_Multi_Connection_DC_Charging_ "Generic 8-byte raw payload. Detail page: https://www.isobus.net/isobus/pGNAndSPN/1317?type=PGN. Signal-level enrichment via PR welcome  see CONTRIBUTING.md.";
CM_ SG_ 2555117568 Electrified_Accessory_Engine_Coo "Generic 8-byte raw payload. Detail page: https://www.isobus.net/isobus/pGNAndSPN/1322?type=PGN. Signal-level enrichment via PR welcome  see CONTRIBUTING.md.";
CM_ SG_ 2555183104 FD_Transport_Protocol_Connection "Generic 8-byte raw payload. Detail page: https://www.isobus.net/isobus/pGNAndSPN/1336?type=PGN. Signal-level enrichment via PR welcome  see CONTRIBUTING.md.";
CM_ SG_ 2555248640 FD_Transport_Protocol_Data_Trans "Generic 8-byte raw payload. Detail page: https://www.isobus.net/isobus/pGNAndSPN/1340?type=PGN. Signal-level enrichment via PR welcome  see CONTRIBUTING.md.";
CM_ SG_ 2555314176 Data_Transfer_Support_RawPayload "Generic 8-byte raw payload. Detail page: https://www.isobus.net/isobus/pGNAndSPN/1350?type=PGN. Signal-level enrichment via PR welcome  see CONTRIBUTING.md.";
CM_ SG_ 2555379712 Monthly_Data_Transfer_RawPayload "Generic 8-byte raw payload. Detail page: https://www.isobus.net/isobus/pGNAndSPN/1355?type=PGN. Signal-level enrichment via PR welcome  see CONTRIBUTING.md.";
CM_ SG_ 2555445248 Weekly_Data_Transfer_RawPayload "Generic 8-byte raw payload. Detail page: https://www.isobus.net/isobus/pGNAndSPN/1360?type=PGN. Signal-level enrichment via PR welcome  see CONTRIBUTING.md.";
CM_ SG_ 2555510784 Daily_Data_Transfer_RawPayload "Generic 8-byte raw payload. Detail page: https://www.isobus.net/isobus/pGNAndSPN/1365?type=PGN. Signal-level enrichment via PR welcome  see CONTRIBUTING.md.";
CM_ SG_ 2555576320 EVSE_Control_1_RawPayload "Generic 8-byte raw payload. Detail page: https://www.isobus.net/isobus/pGNAndSPN/1369?type=PGN. Signal-level enrichment via PR welcome  see CONTRIBUTING.md.";
CM_ SG_ 2555641856 Winch_Information_3_RawPayload "Generic 8-byte raw payload. Detail page: https://www.isobus.net/isobus/pGNAndSPN/1370?type=PGN. Signal-level enrichment via PR welcome  see CONTRIBUTING.md.";
CM_ SG_ 2555707392 Air_Suspension_Control_8_RawPayl "Generic 8-byte raw payload. Detail page: https://www.isobus.net/isobus/pGNAndSPN/1371?type=PGN. Signal-level enrichment via PR welcome  see CONTRIBUTING.md.";
CM_ SG_ 2555772928 Motor_Generator_2_Inverter_Contr "Generic 8-byte raw payload. Detail page: https://www.isobus.net/isobus/pGNAndSPN/1378?type=PGN. Signal-level enrichment via PR welcome  see CONTRIBUTING.md.";
CM_ SG_ 2555838464 Motor_Generator_1_Inverter_Contr "Generic 8-byte raw payload. Detail page: https://www.isobus.net/isobus/pGNAndSPN/1385?type=PGN. Signal-level enrichment via PR welcome  see CONTRIBUTING.md.";
CM_ SG_ 2555904000 Hoist_Command_Information_RawPay "Generic 8-byte raw payload. Detail page: https://www.isobus.net/isobus/pGNAndSPN/1387?type=PGN. Signal-level enrichment via PR welcome  see CONTRIBUTING.md.";
CM_ SG_ 2555969536 Motor_Generator_2_Inverter_Isola "Generic 8-byte raw payload. Detail page: https://www.isobus.net/isobus/pGNAndSPN/1391?type=PGN. Signal-level enrichment via PR welcome  see CONTRIBUTING.md.";
CM_ SG_ 2556035072 Motor_Generator_1_Inverter_Isola "Generic 8-byte raw payload. Detail page: https://www.isobus.net/isobus/pGNAndSPN/1395?type=PGN. Signal-level enrichment via PR welcome  see CONTRIBUTING.md.";
CM_ SG_ 2556100608 Motor_Generator_2_Inverter_Limit "Generic 8-byte raw payload. Detail page: https://www.isobus.net/isobus/pGNAndSPN/1401?type=PGN. Signal-level enrichment via PR welcome  see CONTRIBUTING.md.";
CM_ SG_ 2556166144 Motor_Generator_2_Inverter_Limit "Generic 8-byte raw payload. Detail page: https://www.isobus.net/isobus/pGNAndSPN/1407?type=PGN. Signal-level enrichment via PR welcome  see CONTRIBUTING.md.";
CM_ SG_ 2556231680 Motor_Generator_2_Inverter_Limit "Generic 8-byte raw payload. Detail page: https://www.isobus.net/isobus/pGNAndSPN/1413?type=PGN. Signal-level enrichment via PR welcome  see CONTRIBUTING.md.";
CM_ SG_ 2556297216 Motor_Generator_1_Inverter_Limit "Generic 8-byte raw payload. Detail page: https://www.isobus.net/isobus/pGNAndSPN/1419?type=PGN. Signal-level enrichment via PR welcome  see CONTRIBUTING.md.";
CM_ SG_ 2556362752 Motor_Generator_1_Inverter_Limit "Generic 8-byte raw payload. Detail page: https://www.isobus.net/isobus/pGNAndSPN/1425?type=PGN. Signal-level enrichment via PR welcome  see CONTRIBUTING.md.";
CM_ SG_ 2556428288 Motor_Generator_1_Inverter_Limit "Generic 8-byte raw payload. Detail page: https://www.isobus.net/isobus/pGNAndSPN/1431?type=PGN. Signal-level enrichment via PR welcome  see CONTRIBUTING.md.";
CM_ SG_ 2556493824 Personnel_Detect_Interlock_RawPa "Generic 8-byte raw payload. Detail page: https://www.isobus.net/isobus/pGNAndSPN/1433?type=PGN. Signal-level enrichment via PR welcome  see CONTRIBUTING.md.";
CM_ SG_ 2556559360 Engine_Cylinder_Combustion_Confi "Generic 8-byte raw payload. Detail page: https://www.isobus.net/isobus/pGNAndSPN/1435?type=PGN. Signal-level enrichment via PR welcome  see CONTRIBUTING.md.";
CM_ SG_ 2556624896 Engine_Cylinder_Combustion_Confi "Generic 8-byte raw payload. Detail page: https://www.isobus.net/isobus/pGNAndSPN/1437?type=PGN. Signal-level enrichment via PR welcome  see CONTRIBUTING.md.";
CM_ SG_ 2556690432 Engine_Cylinder_Pressure_Timing_ "Generic 8-byte raw payload. Detail page: https://www.isobus.net/isobus/pGNAndSPN/1441?type=PGN. Signal-level enrichment via PR welcome  see CONTRIBUTING.md.";
CM_ SG_ 2556755968 Engine_Cylinder_Pressure_Timing_ "Generic 8-byte raw payload. Detail page: https://www.isobus.net/isobus/pGNAndSPN/1445?type=PGN. Signal-level enrichment via PR welcome  see CONTRIBUTING.md.";
CM_ SG_ 2556821504 Electrified_Accessory_Generator_ "Generic 8-byte raw payload. Detail page: https://www.isobus.net/isobus/pGNAndSPN/1452?type=PGN. Signal-level enrichment via PR welcome  see CONTRIBUTING.md.";
CM_ SG_ 2556887040 Electrified_Accessory_Generator_ "Generic 8-byte raw payload. Detail page: https://www.isobus.net/isobus/pGNAndSPN/1459?type=PGN. Signal-level enrichment via PR welcome  see CONTRIBUTING.md.";
CM_ SG_ 2556952576 On_Board_Programming_1_RawPayloa "Generic 8-byte raw payload. Detail page: https://www.isobus.net/isobus/pGNAndSPN/1471?type=PGN. Signal-level enrichment via PR welcome  see CONTRIBUTING.md.";
CM_ SG_ 2557018112 Marine_Control_Information_Confi "Generic 8-byte raw payload. Detail page: https://www.isobus.net/isobus/pGNAndSPN/1475?type=PGN. Signal-level enrichment via PR welcome  see CONTRIBUTING.md.";
CM_ SG_ 2557083648 Marine_Control_Information_2_Raw "Generic 8-byte raw payload. Detail page: https://www.isobus.net/isobus/pGNAndSPN/1482?type=PGN. Signal-level enrichment via PR welcome  see CONTRIBUTING.md.";
CM_ SG_ 2557149184 Well_Stimulation_Pump_Sensor_Cal "Generic 8-byte raw payload. Detail page: https://www.isobus.net/isobus/pGNAndSPN/1484?type=PGN. Signal-level enrichment via PR welcome  see CONTRIBUTING.md.";
CM_ SG_ 2557214720 CiA_602_2_XCP_Obsolete_RawPayloa "Generic 8-byte raw payload. Detail page: https://www.isobus.net/isobus/pGNAndSPN/1485?type=PGN. Signal-level enrichment via PR welcome  see CONTRIBUTING.md.";
CM_ SG_ 2557280256 Well_Stimulation_Pump_System_Con "Generic 8-byte raw payload. Detail page: https://www.isobus.net/isobus/pGNAndSPN/1496?type=PGN. Signal-level enrichment via PR welcome  see CONTRIBUTING.md.";
CM_ SG_ 2557345792 Configurable_Receive_SPNs_Comman "Generic 8-byte raw payload. Detail page: https://www.isobus.net/isobus/pGNAndSPN/1501?type=PGN. Signal-level enrichment via PR welcome  see CONTRIBUTING.md.";
CM_ SG_ 2557411328 Authentication_Client_to_Authent "Generic 8-byte raw payload. Detail page: https://www.isobus.net/isobus/pGNAndSPN/1527?type=PGN. Signal-level enrichment via PR welcome  see CONTRIBUTING.md.";
CM_ SG_ 2557476864 Authentication_Server_to_Authent "Generic 8-byte raw payload. Detail page: https://www.isobus.net/isobus/pGNAndSPN/1552?type=PGN. Signal-level enrichment via PR welcome  see CONTRIBUTING.md.";
CM_ SG_ 2557542400 Configurable_Transmit_PGNs_Comma "Generic 8-byte raw payload. Detail page: https://www.isobus.net/isobus/pGNAndSPN/1556?type=PGN. Signal-level enrichment via PR welcome  see CONTRIBUTING.md.";
CM_ SG_ 2557607936 Oil_Debris_Monitor_Configuration "Generic 8-byte raw payload. Detail page: https://www.isobus.net/isobus/pGNAndSPN/1569?type=PGN. Signal-level enrichment via PR welcome  see CONTRIBUTING.md.";
CM_ SG_ 2557673472 Electrified_Accessory_Propulsion "Generic 8-byte raw payload. Detail page: https://www.isobus.net/isobus/pGNAndSPN/1576?type=PGN. Signal-level enrichment via PR welcome  see CONTRIBUTING.md.";
CM_ SG_ 2557739008 Electrified_Accessory_Propulsion "Generic 8-byte raw payload. Detail page: https://www.isobus.net/isobus/pGNAndSPN/1583?type=PGN. Signal-level enrichment via PR welcome  see CONTRIBUTING.md.";
CM_ SG_ 2557804544 Electrified_Accessory_Propulsion "Generic 8-byte raw payload. Detail page: https://www.isobus.net/isobus/pGNAndSPN/1590?type=PGN. Signal-level enrichment via PR welcome  see CONTRIBUTING.md.";
CM_ SG_ 2557870080 Electrified_Accessory_Power_Elec "Generic 8-byte raw payload. Detail page: https://www.isobus.net/isobus/pGNAndSPN/1597?type=PGN. Signal-level enrichment via PR welcome  see CONTRIBUTING.md.";
CM_ SG_ 2557935616 Electrified_Accessory_Power_Elec "Generic 8-byte raw payload. Detail page: https://www.isobus.net/isobus/pGNAndSPN/1604?type=PGN. Signal-level enrichment via PR welcome  see CONTRIBUTING.md.";
CM_ SG_ 2558001152 Electrified_Accessory_Power_Elec "Generic 8-byte raw payload. Detail page: https://www.isobus.net/isobus/pGNAndSPN/1611?type=PGN. Signal-level enrichment via PR welcome  see CONTRIBUTING.md.";
CM_ SG_ 2558066688 Electrified_Accessory_Propulsion "Generic 8-byte raw payload. Detail page: https://www.isobus.net/isobus/pGNAndSPN/1618?type=PGN. Signal-level enrichment via PR welcome  see CONTRIBUTING.md.";
CM_ SG_ 2558132224 Electrified_Accessory_Propulsion "Generic 8-byte raw payload. Detail page: https://www.isobus.net/isobus/pGNAndSPN/1625?type=PGN. Signal-level enrichment via PR welcome  see CONTRIBUTING.md.";
CM_ SG_ 2558197760 Electrified_Accessory_Power_Elec "Generic 8-byte raw payload. Detail page: https://www.isobus.net/isobus/pGNAndSPN/1632?type=PGN. Signal-level enrichment via PR welcome  see CONTRIBUTING.md.";
CM_ SG_ 2558263296 Extended_Control_Function_Functi "Generic 8-byte raw payload. Detail page: https://www.isobus.net/isobus/pGNAndSPN/1633?type=PGN. Signal-level enrichment via PR welcome  see CONTRIBUTING.md.";
CM_ SG_ 2558328832 Electrified_Accessory_Motor_Comm "Generic 8-byte raw payload. Detail page: https://www.isobus.net/isobus/pGNAndSPN/1655?type=PGN. Signal-level enrichment via PR welcome  see CONTRIBUTING.md.";
CM_ SG_ 2558394368 Engine_Speed_Ramp_Rate_Boundary_ "Generic 8-byte raw payload. Detail page: https://www.isobus.net/isobus/pGNAndSPN/1657?type=PGN. Signal-level enrichment via PR welcome  see CONTRIBUTING.md.";
CM_ SG_ 2558459904 Tire_Sensor_Identification_Comma "Generic 8-byte raw payload. Detail page: https://www.isobus.net/isobus/pGNAndSPN/1661?type=PGN. Signal-level enrichment via PR welcome  see CONTRIBUTING.md.";
CM_ SG_ 2558525440 Hybrid_or_EV_System_Control_1_Ra "Generic 8-byte raw payload. Detail page: https://www.isobus.net/isobus/pGNAndSPN/1674?type=PGN. Signal-level enrichment via PR welcome  see CONTRIBUTING.md.";
CM_ SG_ 2558590976 Aftertreatment_System_Control_Ra "Generic 8-byte raw payload. Detail page: https://www.isobus.net/isobus/pGNAndSPN/1680?type=PGN. Signal-level enrichment via PR welcome  see CONTRIBUTING.md.";
CM_ SG_ 2558656512 Tire_Configuration_Command_Infor "Generic 8-byte raw payload. Detail page: https://www.isobus.net/isobus/pGNAndSPN/1687?type=PGN. Signal-level enrichment via PR welcome  see CONTRIBUTING.md.";
CM_ SG_ 2558722048 Payload_Calibration_Information_ "Generic 8-byte raw payload. Detail page: https://www.isobus.net/isobus/pGNAndSPN/1690?type=PGN. Signal-level enrichment via PR welcome  see CONTRIBUTING.md.";
CM_ SG_ 2558787584 Aftertreatment_1_Particulate_Sen "Generic 8-byte raw payload. Detail page: https://www.isobus.net/isobus/pGNAndSPN/1695?type=PGN. Signal-level enrichment via PR welcome  see CONTRIBUTING.md.";
CM_ SG_ 2558853120 Cab_Message_2_RawPayload "Generic 8-byte raw payload. Detail page: https://www.isobus.net/isobus/pGNAndSPN/1713?type=PGN. Signal-level enrichment via PR welcome  see CONTRIBUTING.md.";
CM_ SG_ 2558918656 Switched_Power_Outputs_Command_R "Generic 8-byte raw payload. Detail page: https://www.isobus.net/isobus/pGNAndSPN/1745?type=PGN. Signal-level enrichment via PR welcome  see CONTRIBUTING.md.";
CM_ SG_ 2558984192 Engine_State_Requests_RawPayload "Generic 8-byte raw payload. Detail page: https://www.isobus.net/isobus/pGNAndSPN/1754?type=PGN. Signal-level enrichment via PR welcome  see CONTRIBUTING.md.";
CM_ SG_ 2559049728 Radio_Beacon_Request_RawPayload "Generic 8-byte raw payload. Detail page: https://www.isobus.net/isobus/pGNAndSPN/1758?type=PGN. Signal-level enrichment via PR welcome  see CONTRIBUTING.md.";
CM_ SG_ 2559115264 Running_Gear_Equipment_2_4_RawPa "Generic 8-byte raw payload. Detail page: https://www.isobus.net/isobus/pGNAndSPN/1759?type=PGN. Signal-level enrichment via PR welcome  see CONTRIBUTING.md.";
CM_ SG_ 2559180800 Running_Gear_Equipment_1_2_RawPa "Generic 8-byte raw payload. Detail page: https://www.isobus.net/isobus/pGNAndSPN/1760?type=PGN. Signal-level enrichment via PR welcome  see CONTRIBUTING.md.";
CM_ SG_ 2559246336 CCP_Data_Transmission_Object_Raw "Generic 8-byte raw payload. Detail page: https://www.isobus.net/isobus/pGNAndSPN/1761?type=PGN. Signal-level enrichment via PR welcome  see CONTRIBUTING.md.";
CM_ SG_ 2559311872 CCP_Command_Receive_Object_RawPa "Generic 8-byte raw payload. Detail page: https://www.isobus.net/isobus/pGNAndSPN/1762?type=PGN. Signal-level enrichment via PR welcome  see CONTRIBUTING.md.";
CM_ SG_ 2559377408 Sequence_Control_Client_to_Seque "Generic 8-byte raw payload. Detail page: https://www.isobus.net/isobus/pGNAndSPN/1763?type=PGN. Signal-level enrichment via PR welcome  see CONTRIBUTING.md.";
CM_ SG_ 2559442944 Sequence_Control_Master_to_Seque "Generic 8-byte raw payload. Detail page: https://www.isobus.net/isobus/pGNAndSPN/1764?type=PGN. Signal-level enrichment via PR welcome  see CONTRIBUTING.md.";
CM_ SG_ 2559508480 Engine_Configuration_Commands_Ra "Generic 8-byte raw payload. Detail page: https://www.isobus.net/isobus/pGNAndSPN/1765?type=PGN. Signal-level enrichment via PR welcome  see CONTRIBUTING.md.";
CM_ SG_ 2559574016 Supplemental_Fan_Command_RawPayl "Generic 8-byte raw payload. Detail page: https://www.isobus.net/isobus/pGNAndSPN/1769?type=PGN. Signal-level enrichment via PR welcome  see CONTRIBUTING.md.";
CM_ SG_ 2559639552 Vehicle_Chassis_Lubrication_Syst "Generic 8-byte raw payload. Detail page: https://www.isobus.net/isobus/pGNAndSPN/1774?type=PGN. Signal-level enrichment via PR welcome  see CONTRIBUTING.md.";
CM_ SG_ 2559705088 Aftertreatment_1_Hydrocarbon_Dos "Generic 8-byte raw payload. Detail page: https://www.isobus.net/isobus/pGNAndSPN/1780?type=PGN. Signal-level enrichment via PR welcome  see CONTRIBUTING.md.";
CM_ SG_ 2559770624 NAME_Management_Message_RawPaylo "Generic 8-byte raw payload. Detail page: https://www.isobus.net/isobus/pGNAndSPN/1798?type=PGN. Signal-level enrichment via PR welcome  see CONTRIBUTING.md.";
CM_ SG_ 2559836160 Aftertreatment_1_Diesel_Particul "Generic 8-byte raw payload. Detail page: https://www.isobus.net/isobus/pGNAndSPN/1800?type=PGN. Signal-level enrichment via PR welcome  see CONTRIBUTING.md.";
CM_ SG_ 2559901696 Aftertreatment_2_Diesel_Particul "Generic 8-byte raw payload. Detail page: https://www.isobus.net/isobus/pGNAndSPN/1802?type=PGN. Signal-level enrichment via PR welcome  see CONTRIBUTING.md.";
CM_ SG_ 2559967232 Low_Voltage_Disconnect_Set_Opera "Generic 8-byte raw payload. Detail page: https://www.isobus.net/isobus/pGNAndSPN/1803?type=PGN. Signal-level enrichment via PR welcome  see CONTRIBUTING.md.";
CM_ SG_ 2560032768 Noise_Control_Status_RawPayload "Generic 8-byte raw payload. Detail page: https://www.isobus.net/isobus/pGNAndSPN/1805?type=PGN. Signal-level enrichment via PR welcome  see CONTRIBUTING.md.";
CM_ SG_ 2560098304 Noise_Control_1_RawPayload "Generic 8-byte raw payload. Detail page: https://www.isobus.net/isobus/pGNAndSPN/1807?type=PGN. Signal-level enrichment via PR welcome  see CONTRIBUTING.md.";
CM_ SG_ 2560163840 Joystick_Lamp_Command_Message_Ra "Generic 8-byte raw payload. Detail page: https://www.isobus.net/isobus/pGNAndSPN/1837?type=PGN. Signal-level enrichment via PR welcome  see CONTRIBUTING.md.";
CM_ SG_ 2560229376 General_Purpose_Message_1_8_RawP "Generic 8-byte raw payload. Detail page: https://www.isobus.net/isobus/pGNAndSPN/1838?type=PGN. Signal-level enrichment via PR welcome  see CONTRIBUTING.md.";
CM_ SG_ 2560360448 Auxiliary_Input_Output_Status_7_ "Generic 8-byte raw payload. Detail page: https://www.isobus.net/isobus/pGNAndSPN/1848?type=PGN. Signal-level enrichment via PR welcome  see CONTRIBUTING.md.";
CM_ SG_ 2560425984 Auxiliary_Input_Output_Status_6_ "Generic 8-byte raw payload. Detail page: https://www.isobus.net/isobus/pGNAndSPN/1856?type=PGN. Signal-level enrichment via PR welcome  see CONTRIBUTING.md.";
CM_ SG_ 2560491520 DTC_Counts_RawPayload "Generic 8-byte raw payload. Detail page: https://www.isobus.net/isobus/pGNAndSPN/1861?type=PGN. Signal-level enrichment via PR welcome  see CONTRIBUTING.md.";
CM_ SG_ 2560557056 Immediate_Fault_Status_RawPayloa "Generic 8-byte raw payload. Detail page: https://www.isobus.net/isobus/pGNAndSPN/1873?type=PGN. Signal-level enrichment via PR welcome  see CONTRIBUTING.md.";
CM_ SG_ 2560622592 NTE_Status_RawPayload "Generic 8-byte raw payload. Detail page: https://www.isobus.net/isobus/pGNAndSPN/1879?type=PGN. Signal-level enrichment via PR welcome  see CONTRIBUTING.md.";
CM_ SG_ 2560688128 Emission_Increasing_Auxiliary_Em "Generic 8-byte raw payload. Detail page: https://www.isobus.net/isobus/pGNAndSPN/1882?type=PGN. Signal-level enrichment via PR welcome  see CONTRIBUTING.md.";
CM_ SG_ 2560753664 Regulated_Exhaust_Emission_Level "Generic 8-byte raw payload. Detail page: https://www.isobus.net/isobus/pGNAndSPN/1887?type=PGN. Signal-level enrichment via PR welcome  see CONTRIBUTING.md.";
CM_ SG_ 2560819200 DTC_To_Lamp_Association_RawPaylo "Generic 8-byte raw payload. Detail page: https://www.isobus.net/isobus/pGNAndSPN/1899?type=PGN. Signal-level enrichment via PR welcome  see CONTRIBUTING.md.";
CM_ SG_ 2560884736 Scaled_Test_Results_RawPayload "Generic 8-byte raw payload. Detail page: https://www.isobus.net/isobus/pGNAndSPN/1906?type=PGN. Signal-level enrichment via PR welcome  see CONTRIBUTING.md.";
CM_ SG_ 2560950272 Auxiliary_Input_Output_Status_4_ "Generic 8-byte raw payload. Detail page: https://www.isobus.net/isobus/pGNAndSPN/1938?type=PGN. Signal-level enrichment via PR welcome  see CONTRIBUTING.md.";
CM_ SG_ 2561015808 Auxiliary_Input_Output_Status_3_ "Generic 8-byte raw payload. Detail page: https://www.isobus.net/isobus/pGNAndSPN/1970?type=PGN. Signal-level enrichment via PR welcome  see CONTRIBUTING.md.";
CM_ SG_ 2561081344 Auxiliary_Input_Output_Status_2_ "Generic 8-byte raw payload. Detail page: https://www.isobus.net/isobus/pGNAndSPN/2002?type=PGN. Signal-level enrichment via PR welcome  see CONTRIBUTING.md.";
CM_ SG_ 2561146880 Text_Display_RawPayload "Generic 8-byte raw payload. Detail page: https://www.isobus.net/isobus/pGNAndSPN/2005?type=PGN. Signal-level enrichment via PR welcome  see CONTRIBUTING.md.";
CM_ SG_ 2561212416 Forward_Lane_Image_Command_RawPa "Generic 8-byte raw payload. Detail page: https://www.isobus.net/isobus/pGNAndSPN/2011?type=PGN. Signal-level enrichment via PR welcome  see CONTRIBUTING.md.";
CM_ SG_ 2561277952 Client_ECU_to_File_Server_messag "Generic 8-byte raw payload. Detail page: https://www.isobus.net/isobus/pGNAndSPN/2012?type=PGN. Signal-level enrichment via PR welcome  see CONTRIBUTING.md.";
CM_ SG_ 2561343488 File_Server_to_Client_ECU_messag "Generic 8-byte raw payload. Detail page: https://www.isobus.net/isobus/pGNAndSPN/2013?type=PGN. Signal-level enrichment via PR welcome  see CONTRIBUTING.md.";
CM_ SG_ 2561540096 Tire_Pressure_Reference_Setting_ "Generic 8-byte raw payload. Detail page: https://www.isobus.net/isobus/pGNAndSPN/2025?type=PGN. Signal-level enrichment via PR welcome  see CONTRIBUTING.md.";
CM_ SG_ 2561605632 Parameter_Locate_Message_RawPayl "Generic 8-byte raw payload. Detail page: https://www.isobus.net/isobus/pGNAndSPN/2026?type=PGN. Signal-level enrichment via PR welcome  see CONTRIBUTING.md.";
CM_ SG_ 2561671168 Configuration_Identification_Mes "Generic 8-byte raw payload. Detail page: https://www.isobus.net/isobus/pGNAndSPN/2027?type=PGN. Signal-level enrichment via PR welcome  see CONTRIBUTING.md.";
CM_ SG_ 2561736704 Proprietarily_Configurable_Messa "Generic 8-byte raw payload. Detail page: https://www.isobus.net/isobus/pGNAndSPN/2028?type=PGN. Signal-level enrichment via PR welcome  see CONTRIBUTING.md.";
CM_ SG_ 2561802240 Proprietarily_Configurable_Messa "Generic 8-byte raw payload. Detail page: https://www.isobus.net/isobus/pGNAndSPN/2029?type=PGN. Signal-level enrichment via PR welcome  see CONTRIBUTING.md.";
CM_ SG_ 2561867776 Proprietarily_Configurable_Messa "Generic 8-byte raw payload. Detail page: https://www.isobus.net/isobus/pGNAndSPN/2030?type=PGN. Signal-level enrichment via PR welcome  see CONTRIBUTING.md.";
CM_ SG_ 2561933312 Proprietarily_Configurable_Messa "Generic 8-byte raw payload. Detail page: https://www.isobus.net/isobus/pGNAndSPN/2031?type=PGN. Signal-level enrichment via PR welcome  see CONTRIBUTING.md.";
CM_ SG_ 2561998848 Proprietarily_Configurable_Messa "Generic 8-byte raw payload. Detail page: https://www.isobus.net/isobus/pGNAndSPN/2032?type=PGN. Signal-level enrichment via PR welcome  see CONTRIBUTING.md.";
CM_ SG_ 2562064384 Proprietarily_Configurable_Messa "Generic 8-byte raw payload. Detail page: https://www.isobus.net/isobus/pGNAndSPN/2033?type=PGN. Signal-level enrichment via PR welcome  see CONTRIBUTING.md.";
CM_ SG_ 2562129920 Proprietarily_Configurable_Messa "Generic 8-byte raw payload. Detail page: https://www.isobus.net/isobus/pGNAndSPN/2034?type=PGN. Signal-level enrichment via PR welcome  see CONTRIBUTING.md.";
CM_ SG_ 2562195456 Proprietarily_Configurable_Messa "Generic 8-byte raw payload. Detail page: https://www.isobus.net/isobus/pGNAndSPN/2035?type=PGN. Signal-level enrichment via PR welcome  see CONTRIBUTING.md.";
CM_ SG_ 2562260992 Proprietarily_Configurable_Messa "Generic 8-byte raw payload. Detail page: https://www.isobus.net/isobus/pGNAndSPN/2036?type=PGN. Signal-level enrichment via PR welcome  see CONTRIBUTING.md.";
CM_ SG_ 2562326528 Proprietarily_Configurable_Messa "Generic 8-byte raw payload. Detail page: https://www.isobus.net/isobus/pGNAndSPN/2037?type=PGN. Signal-level enrichment via PR welcome  see CONTRIBUTING.md.";
CM_ SG_ 2562392064 Proprietarily_Configurable_Messa "Generic 8-byte raw payload. Detail page: https://www.isobus.net/isobus/pGNAndSPN/2038?type=PGN. Signal-level enrichment via PR welcome  see CONTRIBUTING.md.";
CM_ SG_ 2562457600 Proprietarily_Configurable_Messa "Generic 8-byte raw payload. Detail page: https://www.isobus.net/isobus/pGNAndSPN/2039?type=PGN. Signal-level enrichment via PR welcome  see CONTRIBUTING.md.";
CM_ SG_ 2562523136 Proprietarily_Configurable_Messa "Generic 8-byte raw payload. Detail page: https://www.isobus.net/isobus/pGNAndSPN/2040?type=PGN. Signal-level enrichment via PR welcome  see CONTRIBUTING.md.";
CM_ SG_ 2562588672 Proprietarily_Configurable_Messa "Generic 8-byte raw payload. Detail page: https://www.isobus.net/isobus/pGNAndSPN/2041?type=PGN. Signal-level enrichment via PR welcome  see CONTRIBUTING.md.";
CM_ SG_ 2562654208 Proprietarily_Configurable_Messa "Generic 8-byte raw payload. Detail page: https://www.isobus.net/isobus/pGNAndSPN/2042?type=PGN. Signal-level enrichment via PR welcome  see CONTRIBUTING.md.";
CM_ SG_ 2562719744 Proprietarily_Configurable_Messa "Generic 8-byte raw payload. Detail page: https://www.isobus.net/isobus/pGNAndSPN/2043?type=PGN. Signal-level enrichment via PR welcome  see CONTRIBUTING.md.";
CM_ SG_ 2562785280 Diagnostic_Readiness_2_RawPayloa "Generic 8-byte raw payload. Detail page: https://www.isobus.net/isobus/pGNAndSPN/2047?type=PGN. Signal-level enrichment via PR welcome  see CONTRIBUTING.md.";
CM_ SG_ 2562850816 Monitor_Performance_Ratio_RawPay "Generic 8-byte raw payload. Detail page: https://www.isobus.net/isobus/pGNAndSPN/2052?type=PGN. Signal-level enrichment via PR welcome  see CONTRIBUTING.md.";
CM_ SG_ 2562981888 General_Purpose_Valve_command_Ra "Generic 8-byte raw payload. Detail page: https://www.isobus.net/isobus/pGNAndSPN/2060?type=PGN. Signal-level enrichment via PR welcome  see CONTRIBUTING.md.";
CM_ SG_ 2563047424 General_Purpose_Valve_measured_f "Generic 8-byte raw payload. Detail page: https://www.isobus.net/isobus/pGNAndSPN/2066?type=PGN. Signal-level enrichment via PR welcome  see CONTRIBUTING.md.";
CM_ SG_ 2563112960 General_Purpose_Valve_estimated_ "Generic 8-byte raw payload. Detail page: https://www.isobus.net/isobus/pGNAndSPN/2074?type=PGN. Signal-level enrichment via PR welcome  see CONTRIBUTING.md.";
CM_ SG_ 2563309568 Request_2_RawPayload "Generic 8-byte raw payload. Detail page: https://www.isobus.net/isobus/pGNAndSPN/2082?type=PGN. Signal-level enrichment via PR welcome  see CONTRIBUTING.md.";
CM_ SG_ 2563375104 Transfer_RawPayload "Generic 8-byte raw payload. Detail page: https://www.isobus.net/isobus/pGNAndSPN/2086?type=PGN. Signal-level enrichment via PR welcome  see CONTRIBUTING.md.";
CM_ SG_ 2563702784 Continuous_Torque_Speed_Limit_Re "Generic 8-byte raw payload. Detail page: https://www.isobus.net/isobus/pGNAndSPN/2102?type=PGN. Signal-level enrichment via PR welcome  see CONTRIBUTING.md.";
CM_ SG_ 2563768320 Background_lighting_level_comman "Generic 8-byte raw payload. Detail page: https://www.isobus.net/isobus/pGNAndSPN/2103?type=PGN. Signal-level enrichment via PR welcome  see CONTRIBUTING.md.";
CM_ SG_ 2563833856 Air_Suspension_Control_6_RawPayl "Generic 8-byte raw payload. Detail page: https://www.isobus.net/isobus/pGNAndSPN/2107?type=PGN. Signal-level enrichment via PR welcome  see CONTRIBUTING.md.";
CM_ SG_ 2563899392 Air_Suspension_Control_2_RawPayl "Generic 8-byte raw payload. Detail page: https://www.isobus.net/isobus/pGNAndSPN/2126?type=PGN. Signal-level enrichment via PR welcome  see CONTRIBUTING.md.";
CM_ SG_ 2563964928 Calibration_Information_RawPaylo "Generic 8-byte raw payload. Detail page: https://www.isobus.net/isobus/pGNAndSPN/2128?type=PGN. Signal-level enrichment via PR welcome  see CONTRIBUTING.md.";
CM_ SG_ 2564030464 Data_Security_RawPayload "Generic 8-byte raw payload. Detail page: https://www.isobus.net/isobus/pGNAndSPN/2131?type=PGN. Signal-level enrichment via PR welcome  see CONTRIBUTING.md.";
CM_ SG_ 2564096000 Time_Date_Adjust_RawPayload "Generic 8-byte raw payload. Detail page: https://www.isobus.net/isobus/pGNAndSPN/2139?type=PGN. Signal-level enrichment via PR welcome  see CONTRIBUTING.md.";
CM_ SG_ 2564161536 Boot_Load_Data_RawPayload "Generic 8-byte raw payload. Detail page: https://www.isobus.net/isobus/pGNAndSPN/2140?type=PGN. Signal-level enrichment via PR welcome  see CONTRIBUTING.md.";
CM_ SG_ 2564554752 Anti_theft_Status_RawPayload "Generic 8-byte raw payload. Detail page: https://www.isobus.net/isobus/pGNAndSPN/2160?type=PGN. Signal-level enrichment via PR welcome  see CONTRIBUTING.md.";
CM_ SG_ 2564620288 Anti_theft_Request_RawPayload "Generic 8-byte raw payload. Detail page: https://www.isobus.net/isobus/pGNAndSPN/2164?type=PGN. Signal-level enrichment via PR welcome  see CONTRIBUTING.md.";
CM_ SG_ 2564685824 Reset_RawPayload "Generic 8-byte raw payload. Detail page: https://www.isobus.net/isobus/pGNAndSPN/2175?type=PGN. Signal-level enrichment via PR welcome  see CONTRIBUTING.md.";
CM_ SG_ 2564816896 Cab_Message_1_RawPayload "Generic 8-byte raw payload. Detail page: https://www.isobus.net/isobus/pGNAndSPN/2208?type=PGN. Signal-level enrichment via PR welcome  see CONTRIBUTING.md.";
CM_ SG_ 2564882432 General_Purpose_Message_2_1_RawP "Generic 8-byte raw payload. Detail page: https://www.isobus.net/isobus/pGNAndSPN/2209?type=PGN. Signal-level enrichment via PR welcome  see CONTRIBUTING.md.";
CM_ SG_ 2564947968 General_Purpose_Message_1_1_RawP "Generic 8-byte raw payload. Detail page: https://www.isobus.net/isobus/pGNAndSPN/2210?type=PGN. Signal-level enrichment via PR welcome  see CONTRIBUTING.md.";
CM_ SG_ 2565013504 Command_Non_continuously_Monitor "Generic 8-byte raw payload. Detail page: https://www.isobus.net/isobus/pGNAndSPN/2213?type=PGN. Signal-level enrichment via PR welcome  see CONTRIBUTING.md.";
CM_ SG_ 2565079040 Running_Gear_Equipment_1_1_RawPa "Generic 8-byte raw payload. Detail page: https://www.isobus.net/isobus/pGNAndSPN/2214?type=PGN. Signal-level enrichment via PR welcome  see CONTRIBUTING.md.";
CM_ SG_ 2565144576 Running_Gear_Equipment_2_1_RawPa "Generic 8-byte raw payload. Detail page: https://www.isobus.net/isobus/pGNAndSPN/2215?type=PGN. Signal-level enrichment via PR welcome  see CONTRIBUTING.md.";
CM_ SG_ 2565668864 Network_Message_RawPayload "Generic 8-byte raw payload. Detail page: https://www.isobus.net/isobus/pGNAndSPN/2269?type=PGN. Signal-level enrichment via PR welcome  see CONTRIBUTING.md.";
CM_ SG_ 2565865472 Electronic_Retarder_Controller_1 "Generic 8-byte raw payload. Detail page: https://www.isobus.net/isobus/pGNAndSPN/2284?type=PGN. Signal-level enrichment via PR welcome  see CONTRIBUTING.md.";
CM_ SG_ 2565865728 Electronic_Brake_Controller_1_Ra "Generic 8-byte raw payload. Detail page: https://www.isobus.net/isobus/pGNAndSPN/2307?type=PGN. Signal-level enrichment via PR welcome  see CONTRIBUTING.md.";
CM_ SG_ 2565865984 Electronic_Transmission_Controll "Generic 8-byte raw payload. Detail page: https://www.isobus.net/isobus/pGNAndSPN/2318?type=PGN. Signal-level enrichment via PR welcome  see CONTRIBUTING.md.";
CM_ SG_ 2565866752 Electronic_Transmission_Controll "Generic 8-byte raw payload. Detail page: https://www.isobus.net/isobus/pGNAndSPN/2345?type=PGN. Signal-level enrichment via PR welcome  see CONTRIBUTING.md.";
CM_ SG_ 2565867008 Electronic_Axle_Controller_1_Raw "Generic 8-byte raw payload. Detail page: https://www.isobus.net/isobus/pGNAndSPN/2357?type=PGN. Signal-level enrichment via PR welcome  see CONTRIBUTING.md.";
CM_ SG_ 2565867264 Forward_Lane_Image_1_RawPayload "Generic 8-byte raw payload. Detail page: https://www.isobus.net/isobus/pGNAndSPN/2368?type=PGN. Signal-level enrichment via PR welcome  see CONTRIBUTING.md.";
CM_ SG_ 2565867520 Hydraulic_Pressure_Governor_Info "Generic 8-byte raw payload. Detail page: https://www.isobus.net/isobus/pGNAndSPN/2379?type=PGN. Signal-level enrichment via PR welcome  see CONTRIBUTING.md.";
CM_ SG_ 2565867776 Vehicle_Dynamic_Stability_Contro "Generic 8-byte raw payload. Detail page: https://www.isobus.net/isobus/pGNAndSPN/2385?type=PGN. Signal-level enrichment via PR welcome  see CONTRIBUTING.md.";
CM_ SG_ 2565868032 Engine_Gas_Flow_Rate_1_RawPayloa "Generic 8-byte raw payload. Detail page: https://www.isobus.net/isobus/pGNAndSPN/2389?type=PGN. Signal-level enrichment via PR welcome  see CONTRIBUTING.md.";
CM_ SG_ 2565868288 Electronic_Steering_Control_RawP "Generic 8-byte raw payload. Detail page: https://www.isobus.net/isobus/pGNAndSPN/2396?type=PGN. Signal-level enrichment via PR welcome  see CONTRIBUTING.md.";
CM_ SG_ 2565868544 Electronic_Transmission_Controll "Generic 8-byte raw payload. Detail page: https://www.isobus.net/isobus/pGNAndSPN/2402?type=PGN. Signal-level enrichment via PR welcome  see CONTRIBUTING.md.";
CM_ SG_ 2565868800 Land_Leveling_System_Operational "Generic 8-byte raw payload. Detail page: https://www.isobus.net/isobus/pGNAndSPN/2413?type=PGN. Signal-level enrichment via PR welcome  see CONTRIBUTING.md.";
CM_ SG_ 2565869056 Aftertreatment_1_Intake_Gas_1_Ra "Generic 8-byte raw payload. Detail page: https://www.isobus.net/isobus/pGNAndSPN/2424?type=PGN. Signal-level enrichment via PR welcome  see CONTRIBUTING.md.";
CM_ SG_ 2565869312 Aftertreatment_1_Outlet_Gas_1_Ra "Generic 8-byte raw payload. Detail page: https://www.isobus.net/isobus/pGNAndSPN/2435?type=PGN. Signal-level enrichment via PR welcome  see CONTRIBUTING.md.";
CM_ SG_ 2565869568 Aftertreatment_2_Intake_Gas_1_Ra "Generic 8-byte raw payload. Detail page: https://www.isobus.net/isobus/pGNAndSPN/2447?type=PGN. Signal-level enrichment via PR welcome  see CONTRIBUTING.md.";
CM_ SG_ 2565869824 Aftertreatment_2_Outlet_Gas_1_Ra "Generic 8-byte raw payload. Detail page: https://www.isobus.net/isobus/pGNAndSPN/2459?type=PGN. Signal-level enrichment via PR welcome  see CONTRIBUTING.md.";
CM_ SG_ 2565870080 Fifth_Wheel_Smart_Systems_1_RawP "Generic 8-byte raw payload. Detail page: https://www.isobus.net/isobus/pGNAndSPN/2463?type=PGN. Signal-level enrichment via PR welcome  see CONTRIBUTING.md.";
CM_ SG_ 2565870336 Slope_Sensor_Information_RawPayl "Generic 8-byte raw payload. Detail page: https://www.isobus.net/isobus/pGNAndSPN/2471?type=PGN. Signal-level enrichment via PR welcome  see CONTRIBUTING.md.";
CM_ SG_ 2565870592 Blade_Information_RawPayload "Generic 8-byte raw payload. Detail page: https://www.isobus.net/isobus/pGNAndSPN/2476?type=PGN. Signal-level enrichment via PR welcome  see CONTRIBUTING.md.";
CM_ SG_ 2565870848 Requested_Generator_Total_AC_Rea "Generic 8-byte raw payload. Detail page: https://www.isobus.net/isobus/pGNAndSPN/2479?type=PGN. Signal-level enrichment via PR welcome  see CONTRIBUTING.md.";
CM_ SG_ 2565871104 Cylinder_Combustion_Status_RawPa "Generic 8-byte raw payload. Detail page: https://www.isobus.net/isobus/pGNAndSPN/2503?type=PGN. Signal-level enrichment via PR welcome  see CONTRIBUTING.md.";
CM_ SG_ 2565871360 Engine_Knock_Level_1_RawPayload "Generic 8-byte raw payload. Detail page: https://www.isobus.net/isobus/pGNAndSPN/2511?type=PGN. Signal-level enrichment via PR welcome  see CONTRIBUTING.md.";
CM_ SG_ 2565871616 Engine_Knock_Level_2_RawPayload "Generic 8-byte raw payload. Detail page: https://www.isobus.net/isobus/pGNAndSPN/2519?type=PGN. Signal-level enrichment via PR welcome  see CONTRIBUTING.md.";
CM_ SG_ 2565871872 Engine_Knock_Level_3_RawPayload "Generic 8-byte raw payload. Detail page: https://www.isobus.net/isobus/pGNAndSPN/2527?type=PGN. Signal-level enrichment via PR welcome  see CONTRIBUTING.md.";
CM_ SG_ 2565872128 Engine_Throttle_Fuel_Actuator_Co "Generic 8-byte raw payload. Detail page: https://www.isobus.net/isobus/pGNAndSPN/2531?type=PGN. Signal-level enrichment via PR welcome  see CONTRIBUTING.md.";
CM_ SG_ 2565872384 General_Purpose_Message_1_7_RawP "Generic 8-byte raw payload. Detail page: https://www.isobus.net/isobus/pGNAndSPN/2532?type=PGN. Signal-level enrichment via PR welcome  see CONTRIBUTING.md.";
CM_ SG_ 2565872640 Requested_Generator_Average_Basi "Generic 8-byte raw payload. Detail page: https://www.isobus.net/isobus/pGNAndSPN/2533?type=PGN. Signal-level enrichment via PR welcome  see CONTRIBUTING.md.";
CM_ SG_ 2565872896 Steering_Angle_Sensor_Informatio "Generic 8-byte raw payload. Detail page: https://www.isobus.net/isobus/pGNAndSPN/2541?type=PGN. Signal-level enrichment via PR welcome  see CONTRIBUTING.md.";
CM_ SG_ 2565873152 Generator_Control_2_RawPayload "Generic 8-byte raw payload. Detail page: https://www.isobus.net/isobus/pGNAndSPN/2544?type=PGN. Signal-level enrichment via PR welcome  see CONTRIBUTING.md.";
CM_ SG_ 2565873408 Electronic_Brake_System_2_6_RawP "Generic 8-byte raw payload. Detail page: https://www.isobus.net/isobus/pGNAndSPN/2545?type=PGN. Signal-level enrichment via PR welcome  see CONTRIBUTING.md.";
CM_ SG_ 2565873664 Electronic_Brake_System_2_5_RawP "Generic 8-byte raw payload. Detail page: https://www.isobus.net/isobus/pGNAndSPN/2546?type=PGN. Signal-level enrichment via PR welcome  see CONTRIBUTING.md.";
CM_ SG_ 2565873920 Engine_Speed_Sensor_Information_ "Generic 8-byte raw payload. Detail page: https://www.isobus.net/isobus/pGNAndSPN/2552?type=PGN. Signal-level enrichment via PR welcome  see CONTRIBUTING.md.";
CM_ SG_ 2565874432 Aftertreatment_1_SCR_Dosing_Syst "Generic 8-byte raw payload. Detail page: https://www.isobus.net/isobus/pGNAndSPN/2564?type=PGN. Signal-level enrichment via PR welcome  see CONTRIBUTING.md.";
CM_ SG_ 2565874688 Aftertreatment_1_SCR_Dosing_Syst "Generic 8-byte raw payload. Detail page: https://www.isobus.net/isobus/pGNAndSPN/2570?type=PGN. Signal-level enrichment via PR welcome  see CONTRIBUTING.md.";
CM_ SG_ 2565874944 Aftertreatment_1_SCR_Ammonia_Inf "Generic 8-byte raw payload. Detail page: https://www.isobus.net/isobus/pGNAndSPN/2577?type=PGN. Signal-level enrichment via PR welcome  see CONTRIBUTING.md.";
CM_ SG_ 2565875200 Aftertreatment_2_SCR_Dosing_Syst "Generic 8-byte raw payload. Detail page: https://www.isobus.net/isobus/pGNAndSPN/2583?type=PGN. Signal-level enrichment via PR welcome  see CONTRIBUTING.md.";
CM_ SG_ 2565875456 Aftertreatment_2_SCR_Dosing_Syst "Generic 8-byte raw payload. Detail page: https://www.isobus.net/isobus/pGNAndSPN/2590?type=PGN. Signal-level enrichment via PR welcome  see CONTRIBUTING.md.";

BA_DEF_ BO_ "SystemMessageLongSymbol" STRING;
BA_DEF_ SG_ "SystemSignalLongSymbol" STRING;

BA_ "SystemMessageLongSymbol" BO_ 2550267904 "VDMA_200_Electronic_Brake_System_1_1";
BA_ "SystemMessageLongSymbol" BO_ 2550333440 "VDMA_300_Electronic_Brake_System_2_1";
BA_ "SystemMessageLongSymbol" BO_ 2550464512 "VDMA_500_CANopen_Application_Message_1_1";
BA_ "SystemMessageLongSymbol" BO_ 2550530048 "VDMA_600_CANopen_Application_Message_2_1";
BA_ "SystemMessageLongSymbol" BO_ 2550595584 "VDMA_700_General_Purpose_Valve_Pressure";
BA_ "SystemMessageLongSymbol" BO_ 2550661120 "VDMA_800_Auxiliary_Input_Output_Status_5";
BA_ "SystemMessageLongSymbol" BO_ 2550726656 "VDMA_900_Static_Roll_Angle_Sensor_Informa";
BA_ "SystemMessageLongSymbol" BO_ 2550792192 "VDMA_A00_Cruise_Control_Vehicle_Speed_2";
BA_ "SystemMessageLongSymbol" BO_ 2550857728 "VDMA_B00_Advanced_Emergency_Braking_Syste";
BA_ "SystemMessageLongSymbol" BO_ 2550923264 "VDMA_C00_Electronic_Engine_Controller_16";
BA_ "SystemMessageLongSymbol" BO_ 2551119872 "VDMA_F00_High_Voltage_Energy_Storage_Pack";
BA_ "SystemMessageLongSymbol" BO_ 2551185408 "VDMA_1000_High_Voltage_Energy_Storage_Pack";
BA_ "SystemMessageLongSymbol" BO_ 2551250944 "VDMA_1100_High_Voltage_Energy_Storage_Pack";
BA_ "SystemMessageLongSymbol" BO_ 2551316480 "VDMA_1200_High_Voltage_Energy_Storage_Pack";
BA_ "SystemMessageLongSymbol" BO_ 2551382016 "VDMA_1300_High_Voltage_Energy_Storage_Pack";
BA_ "SystemMessageLongSymbol" BO_ 2551447552 "VDMA_1400_High_Voltage_Energy_Storage_Pack";
BA_ "SystemMessageLongSymbol" BO_ 2551513088 "VDMA_1500_High_Voltage_Energy_Storage_Pack";
BA_ "SystemMessageLongSymbol" BO_ 2551578624 "VDMA_1600_High_Voltage_Energy_Storage_Pack";
BA_ "SystemMessageLongSymbol" BO_ 2551644160 "VDMA_1700_High_Voltage_Energy_Storage_Pack";
BA_ "SystemMessageLongSymbol" BO_ 2551709696 "VDMA_1800_High_Voltage_Energy_Storage_Pack";
BA_ "SystemMessageLongSymbol" BO_ 2551775232 "VDMA_1900_High_Voltage_Energy_Storage_Pack";
BA_ "SystemMessageLongSymbol" BO_ 2551840768 "VDMA_1A00_High_Voltage_Energy_Storage_Pack";
BA_ "SystemMessageLongSymbol" BO_ 2551906304 "VDMA_1B00_High_Voltage_Energy_Storage_Syst";
BA_ "SystemMessageLongSymbol" BO_ 2551971840 "VDMA_1C00_Transmission_Control_3_Obsolete_";
BA_ "SystemMessageLongSymbol" BO_ 2552037376 "VDMA_1D00_Engine_Ignition_Controller";
BA_ "SystemMessageLongSymbol" BO_ 2552168448 "VDMA_1F00_High_Voltage_Energy_Storage_Pack";
BA_ "SystemMessageLongSymbol" BO_ 2552233984 "VDMA_2000_High_Voltage_Energy_Storage_Pack";
BA_ "SystemMessageLongSymbol" BO_ 2552299520 "VDMA_2100_High_Voltage_Energy_Storage_Pack";
BA_ "SystemMessageLongSymbol" BO_ 2552365056 "VDMA_2200_High_Voltage_Energy_Storage_Pack";
BA_ "SystemMessageLongSymbol" BO_ 2552430592 "VDMA_2300_Tractor_Implement_Management_TIM";
BA_ "SystemMessageLongSymbol" BO_ 2552496128 "VDMA_2400_Tractor_Implement_Management_TIM";
BA_ "SystemMessageLongSymbol" BO_ 2552627200 "VDMA_2600_Motor_Generator_1_Inverter_Contr";
BA_ "SystemMessageLongSymbol" BO_ 2552692736 "VDMA_2700_Motor_Generator_2_Inverter_Contr";
BA_ "SystemMessageLongSymbol" BO_ 2552758272 "VDMA_2800_Motor_Generator_1_Inverter_Rate_";
BA_ "SystemMessageLongSymbol" BO_ 2552823808 "VDMA_2900_Motor_Generator_2_Inverter_Rate_";
BA_ "SystemMessageLongSymbol" BO_ 2552889344 "VDMA_2A00_High_Voltage_Energy_Storage_Pack";
BA_ "SystemMessageLongSymbol" BO_ 2552954880 "VDMA_2B00_High_Voltage_Energy_Storage_Pack";
BA_ "SystemMessageLongSymbol" BO_ 2553020416 "VDMA_2C00_High_Voltage_Energy_Storage_Pack";
BA_ "SystemMessageLongSymbol" BO_ 2553085952 "VDMA_2D00_High_Voltage_Energy_Storage_Pack";
BA_ "SystemMessageLongSymbol" BO_ 2553151488 "VDMA_2E00_High_Voltage_Energy_Storage_Pack";
BA_ "SystemMessageLongSymbol" BO_ 2553217024 "VDMA_2F00_High_Voltage_Energy_Storage_Pack";
BA_ "SystemMessageLongSymbol" BO_ 2553282560 "VDMA_3000_High_Voltage_Energy_Storage_Pack";
BA_ "SystemMessageLongSymbol" BO_ 2553348096 "VDMA_3100_High_Voltage_Energy_Storage_Pack";
BA_ "SystemMessageLongSymbol" BO_ 2553413632 "VDMA_3200_High_Voltage_Energy_Storage_Pack";
BA_ "SystemMessageLongSymbol" BO_ 2553479168 "VDMA_3300_High_Voltage_Energy_Storage_Pack";
BA_ "SystemMessageLongSymbol" BO_ 2553741312 "VDMA_3700_Message_Acknowledgement";
BA_ "SystemMessageLongSymbol" BO_ 2553806848 "VDMA_3800_Version_Negotiation_Section";
BA_ "SystemMessageLongSymbol" BO_ 2553872384 "VDMA_3900_External_ACC_Acceleration_Reques";
BA_ "SystemMessageLongSymbol" BO_ 2553937920 "VDMA_3A00_Battery_Charger_1_Command_1";
BA_ "SystemMessageLongSymbol" BO_ 2554003456 "VDMA_3B00_Battery_Charger_2_Command_1";
BA_ "SystemMessageLongSymbol" BO_ 2554068992 "VDMA_3C00_Tractor_Implement_Management_TIM";
BA_ "SystemMessageLongSymbol" BO_ 2554134528 "VDMA_3D00_Tractor_Implement_Management_TIM";
BA_ "SystemMessageLongSymbol" BO_ 2554200064 "VDMA_3E00_Fuel_Cell_System_Control_Command";
BA_ "SystemMessageLongSymbol" BO_ 2554265600 "VDMA_3F00_Fuel_Cell_System_Power_Limit_Com";
BA_ "SystemMessageLongSymbol" BO_ 2554331136 "VDMA_4000_Fuel_Cell_System_Current_Limit_C";
BA_ "SystemMessageLongSymbol" BO_ 2554396672 "VDMA_4100_Hydrogen_Storage_System_Control_";
BA_ "SystemMessageLongSymbol" BO_ 2554527744 "VDMA_4300_Safety_Header_Message_2";
BA_ "SystemMessageLongSymbol" BO_ 2554855424 "VDMA_4800_Tractor_Implement_Management_TIM";
BA_ "SystemMessageLongSymbol" BO_ 2554920960 "VDMA_4900_Tractor_Implement_Management_TIM";
BA_ "SystemMessageLongSymbol" BO_ 2554986496 "VDMA_4A00_EV_Multi_Connection_DC_Status_1";
BA_ "SystemMessageLongSymbol" BO_ 2555052032 "VDMA_4B00_EV_Multi_Connection_DC_Charging_";
BA_ "SystemMessageLongSymbol" BO_ 2555117568 "VDMA_4C00_Electrified_Accessory_Engine_Coo";
BA_ "SystemMessageLongSymbol" BO_ 2555183104 "VDMA_4D00_FD_Transport_Protocol_Connection";
BA_ "SystemMessageLongSymbol" BO_ 2555248640 "VDMA_4E00_FD_Transport_Protocol_Data_Trans";
BA_ "SystemMessageLongSymbol" BO_ 2555707392 "VDMA_5500_Air_Suspension_Control_8";
BA_ "SystemMessageLongSymbol" BO_ 2555772928 "VDMA_5600_Motor_Generator_2_Inverter_Contr";
BA_ "SystemMessageLongSymbol" BO_ 2555838464 "VDMA_5700_Motor_Generator_1_Inverter_Contr";
BA_ "SystemMessageLongSymbol" BO_ 2555904000 "VDMA_5800_Hoist_Command_Information";
BA_ "SystemMessageLongSymbol" BO_ 2555969536 "VDMA_5900_Motor_Generator_2_Inverter_Isola";
BA_ "SystemMessageLongSymbol" BO_ 2556035072 "VDMA_5A00_Motor_Generator_1_Inverter_Isola";
BA_ "SystemMessageLongSymbol" BO_ 2556100608 "VDMA_5B00_Motor_Generator_2_Inverter_Limit";
BA_ "SystemMessageLongSymbol" BO_ 2556166144 "VDMA_5C00_Motor_Generator_2_Inverter_Limit";
BA_ "SystemMessageLongSymbol" BO_ 2556231680 "VDMA_5D00_Motor_Generator_2_Inverter_Limit";
BA_ "SystemMessageLongSymbol" BO_ 2556297216 "VDMA_5E00_Motor_Generator_1_Inverter_Limit";
BA_ "SystemMessageLongSymbol" BO_ 2556362752 "VDMA_5F00_Motor_Generator_1_Inverter_Limit";
BA_ "SystemMessageLongSymbol" BO_ 2556428288 "VDMA_6000_Motor_Generator_1_Inverter_Limit";
BA_ "SystemMessageLongSymbol" BO_ 2556493824 "VDMA_6100_Personnel_Detect_Interlock";
BA_ "SystemMessageLongSymbol" BO_ 2556559360 "VDMA_6200_Engine_Cylinder_Combustion_Confi";
BA_ "SystemMessageLongSymbol" BO_ 2556624896 "VDMA_6300_Engine_Cylinder_Combustion_Confi";
BA_ "SystemMessageLongSymbol" BO_ 2556690432 "VDMA_6400_Engine_Cylinder_Pressure_Timing_";
BA_ "SystemMessageLongSymbol" BO_ 2556755968 "VDMA_6500_Engine_Cylinder_Pressure_Timing_";
BA_ "SystemMessageLongSymbol" BO_ 2556821504 "VDMA_6600_Electrified_Accessory_Generator_";
BA_ "SystemMessageLongSymbol" BO_ 2556887040 "VDMA_6700_Electrified_Accessory_Generator_";
BA_ "SystemMessageLongSymbol" BO_ 2557018112 "VDMA_6900_Marine_Control_Information_Confi";
BA_ "SystemMessageLongSymbol" BO_ 2557083648 "VDMA_6A00_Marine_Control_Information_2";
BA_ "SystemMessageLongSymbol" BO_ 2557149184 "VDMA_6B00_Well_Stimulation_Pump_Sensor_Cal";
BA_ "SystemMessageLongSymbol" BO_ 2557280256 "VDMA_6D00_Well_Stimulation_Pump_System_Con";
BA_ "SystemMessageLongSymbol" BO_ 2557345792 "VDMA_6E00_Configurable_Receive_SPNs_Comman";
BA_ "SystemMessageLongSymbol" BO_ 2557411328 "VDMA_6F00_Authentication_Client_to_Authent";
BA_ "SystemMessageLongSymbol" BO_ 2557476864 "VDMA_7000_Authentication_Server_to_Authent";
BA_ "SystemMessageLongSymbol" BO_ 2557542400 "VDMA_7100_Configurable_Transmit_PGNs_Comma";
BA_ "SystemMessageLongSymbol" BO_ 2557607936 "VDMA_7200_Oil_Debris_Monitor_Configuration";
BA_ "SystemMessageLongSymbol" BO_ 2557673472 "VDMA_7300_Electrified_Accessory_Propulsion";
BA_ "SystemMessageLongSymbol" BO_ 2557739008 "VDMA_7400_Electrified_Accessory_Propulsion";
BA_ "SystemMessageLongSymbol" BO_ 2557804544 "VDMA_7500_Electrified_Accessory_Propulsion";
BA_ "SystemMessageLongSymbol" BO_ 2557870080 "VDMA_7600_Electrified_Accessory_Power_Elec";
BA_ "SystemMessageLongSymbol" BO_ 2557935616 "VDMA_7700_Electrified_Accessory_Power_Elec";
BA_ "SystemMessageLongSymbol" BO_ 2558001152 "VDMA_7800_Electrified_Accessory_Power_Elec";
BA_ "SystemMessageLongSymbol" BO_ 2558066688 "VDMA_7900_Electrified_Accessory_Propulsion";
BA_ "SystemMessageLongSymbol" BO_ 2558132224 "VDMA_7A00_Electrified_Accessory_Propulsion";
BA_ "SystemMessageLongSymbol" BO_ 2558197760 "VDMA_7B00_Electrified_Accessory_Power_Elec";
BA_ "SystemMessageLongSymbol" BO_ 2558263296 "VDMA_7C00_Extended_Control_Function_Functi";
BA_ "SystemMessageLongSymbol" BO_ 2558328832 "VDMA_7D00_Electrified_Accessory_Motor_Comm";
BA_ "SystemMessageLongSymbol" BO_ 2558394368 "VDMA_7E00_Engine_Speed_Ramp_Rate_Boundary_";
BA_ "SystemMessageLongSymbol" BO_ 2558459904 "VDMA_7F00_Tire_Sensor_Identification_Comma";
BA_ "SystemMessageLongSymbol" BO_ 2558525440 "VDMA_8000_Hybrid_or_EV_System_Control_1";
BA_ "SystemMessageLongSymbol" BO_ 2558590976 "VDMA_8100_Aftertreatment_System_Control";
BA_ "SystemMessageLongSymbol" BO_ 2558656512 "VDMA_8200_Tire_Configuration_Command_Infor";
BA_ "SystemMessageLongSymbol" BO_ 2558722048 "VDMA_8300_Payload_Calibration_Information_";
BA_ "SystemMessageLongSymbol" BO_ 2558787584 "VDMA_8400_Aftertreatment_1_Particulate_Sen";
BA_ "SystemMessageLongSymbol" BO_ 2558918656 "VDMA_8600_Switched_Power_Outputs_Command";
BA_ "SystemMessageLongSymbol" BO_ 2559115264 "VDMA_8900_Running_Gear_Equipment_2_4";
BA_ "SystemMessageLongSymbol" BO_ 2559180800 "VDMA_8A00_Running_Gear_Equipment_1_2";
BA_ "SystemMessageLongSymbol" BO_ 2559246336 "VDMA_8B00_CCP_Data_Transmission_Object";
BA_ "SystemMessageLongSymbol" BO_ 2559311872 "VDMA_8C00_CCP_Command_Receive_Object";
BA_ "SystemMessageLongSymbol" BO_ 2559377408 "VDMA_8D00_Sequence_Control_Client_to_Seque";
BA_ "SystemMessageLongSymbol" BO_ 2559442944 "VDMA_8E00_Sequence_Control_Master_to_Seque";
BA_ "SystemMessageLongSymbol" BO_ 2559508480 "VDMA_8F00_Engine_Configuration_Commands";
BA_ "SystemMessageLongSymbol" BO_ 2559574016 "VDMA_9000_Supplemental_Fan_Command";
BA_ "SystemMessageLongSymbol" BO_ 2559639552 "VDMA_9100_Vehicle_Chassis_Lubrication_Syst";
BA_ "SystemMessageLongSymbol" BO_ 2559705088 "VDMA_9200_Aftertreatment_1_Hydrocarbon_Dos";
BA_ "SystemMessageLongSymbol" BO_ 2559770624 "VDMA_9300_NAME_Management_Message";
BA_ "SystemMessageLongSymbol" BO_ 2559836160 "VDMA_9400_Aftertreatment_1_Diesel_Particul";
BA_ "SystemMessageLongSymbol" BO_ 2559901696 "VDMA_9500_Aftertreatment_2_Diesel_Particul";
BA_ "SystemMessageLongSymbol" BO_ 2559967232 "VDMA_9600_Low_Voltage_Disconnect_Set_Opera";
BA_ "SystemMessageLongSymbol" BO_ 2560163840 "VDMA_9900_Joystick_Lamp_Command_Message";
BA_ "SystemMessageLongSymbol" BO_ 2560229376 "VDMA_9A00_General_Purpose_Message_1_8";
BA_ "SystemMessageLongSymbol" BO_ 2560360448 "VDMA_9C00_Auxiliary_Input_Output_Status_7";
BA_ "SystemMessageLongSymbol" BO_ 2560425984 "VDMA_9D00_Auxiliary_Input_Output_Status_6";
BA_ "SystemMessageLongSymbol" BO_ 2560688128 "VDMA_A100_Emission_Increasing_Auxiliary_Em";
BA_ "SystemMessageLongSymbol" BO_ 2560753664 "VDMA_A200_Regulated_Exhaust_Emission_Level";
BA_ "SystemMessageLongSymbol" BO_ 2560819200 "VDMA_A300_DTC_To_Lamp_Association";
BA_ "SystemMessageLongSymbol" BO_ 2560950272 "VDMA_A500_Auxiliary_Input_Output_Status_4";
BA_ "SystemMessageLongSymbol" BO_ 2561015808 "VDMA_A600_Auxiliary_Input_Output_Status_3";
BA_ "SystemMessageLongSymbol" BO_ 2561081344 "VDMA_A700_Auxiliary_Input_Output_Status_2";
BA_ "SystemMessageLongSymbol" BO_ 2561212416 "VDMA_A900_Forward_Lane_Image_Command";
BA_ "SystemMessageLongSymbol" BO_ 2561277952 "VDMA_AA00_Client_ECU_to_File_Server_messag";
BA_ "SystemMessageLongSymbol" BO_ 2561343488 "VDMA_AB00_File_Server_to_Client_ECU_messag";
BA_ "SystemMessageLongSymbol" BO_ 2561540096 "VDMA_AE00_Tire_Pressure_Reference_Setting";
BA_ "SystemMessageLongSymbol" BO_ 2561605632 "VDMA_AF00_Parameter_Locate_Message";
BA_ "SystemMessageLongSymbol" BO_ 2561671168 "VDMA_B000_Configuration_Identification_Mes";
BA_ "SystemMessageLongSymbol" BO_ 2561736704 "VDMA_B100_Proprietarily_Configurable_Messa";
BA_ "SystemMessageLongSymbol" BO_ 2561802240 "VDMA_B200_Proprietarily_Configurable_Messa";
BA_ "SystemMessageLongSymbol" BO_ 2561867776 "VDMA_B300_Proprietarily_Configurable_Messa";
BA_ "SystemMessageLongSymbol" BO_ 2561933312 "VDMA_B400_Proprietarily_Configurable_Messa";
BA_ "SystemMessageLongSymbol" BO_ 2561998848 "VDMA_B500_Proprietarily_Configurable_Messa";
BA_ "SystemMessageLongSymbol" BO_ 2562064384 "VDMA_B600_Proprietarily_Configurable_Messa";
BA_ "SystemMessageLongSymbol" BO_ 2562129920 "VDMA_B700_Proprietarily_Configurable_Messa";
BA_ "SystemMessageLongSymbol" BO_ 2562195456 "VDMA_B800_Proprietarily_Configurable_Messa";
BA_ "SystemMessageLongSymbol" BO_ 2562260992 "VDMA_B900_Proprietarily_Configurable_Messa";
BA_ "SystemMessageLongSymbol" BO_ 2562326528 "VDMA_BA00_Proprietarily_Configurable_Messa";
BA_ "SystemMessageLongSymbol" BO_ 2562392064 "VDMA_BB00_Proprietarily_Configurable_Messa";
BA_ "SystemMessageLongSymbol" BO_ 2562457600 "VDMA_BC00_Proprietarily_Configurable_Messa";
BA_ "SystemMessageLongSymbol" BO_ 2562523136 "VDMA_BD00_Proprietarily_Configurable_Messa";
BA_ "SystemMessageLongSymbol" BO_ 2562588672 "VDMA_BE00_Proprietarily_Configurable_Messa";
BA_ "SystemMessageLongSymbol" BO_ 2562654208 "VDMA_BF00_Proprietarily_Configurable_Messa";
BA_ "SystemMessageLongSymbol" BO_ 2562719744 "VDMA_C000_Proprietarily_Configurable_Messa";
BA_ "SystemMessageLongSymbol" BO_ 2562850816 "VDMA_C200_Monitor_Performance_Ratio";
BA_ "SystemMessageLongSymbol" BO_ 2562981888 "VDMA_C400_General_Purpose_Valve_command";
BA_ "SystemMessageLongSymbol" BO_ 2563047424 "VDMA_C500_General_Purpose_Valve_measured_f";
BA_ "SystemMessageLongSymbol" BO_ 2563112960 "VDMA_C600_General_Purpose_Valve_estimated_";
BA_ "SystemMessageLongSymbol" BO_ 2563702784 "VDMA_CF00_Continuous_Torque_Speed_Limit_Re";
BA_ "SystemMessageLongSymbol" BO_ 2563768320 "VDMA_D000_Background_lighting_level_comman";
BA_ "SystemMessageLongSymbol" BO_ 2563833856 "VDMA_D100_Air_Suspension_Control_6";
BA_ "SystemMessageLongSymbol" BO_ 2563899392 "VDMA_D200_Air_Suspension_Control_2";
BA_ "SystemMessageLongSymbol" BO_ 2563964928 "VDMA_D300_Calibration_Information";
BA_ "SystemMessageLongSymbol" BO_ 2564882432 "VDMA_E100_General_Purpose_Message_2_1";
BA_ "SystemMessageLongSymbol" BO_ 2564947968 "VDMA_E200_General_Purpose_Message_1_1";
BA_ "SystemMessageLongSymbol" BO_ 2565013504 "VDMA_E300_Command_Non_continuously_Monitor";
BA_ "SystemMessageLongSymbol" BO_ 2565079040 "VDMA_E400_Running_Gear_Equipment_1_1";
BA_ "SystemMessageLongSymbol" BO_ 2565144576 "VDMA_E500_Running_Gear_Equipment_2_1";
BA_ "SystemMessageLongSymbol" BO_ 2565865472 "VDMA_F000_Electronic_Retarder_Controller_1";
BA_ "SystemMessageLongSymbol" BO_ 2565865728 "VDMA_F001_Electronic_Brake_Controller_1";
BA_ "SystemMessageLongSymbol" BO_ 2565865984 "VDMA_F002_Electronic_Transmission_Controll";
BA_ "SystemMessageLongSymbol" BO_ 2565866752 "VDMA_F005_Electronic_Transmission_Controll";
BA_ "SystemMessageLongSymbol" BO_ 2565867008 "VDMA_F006_Electronic_Axle_Controller_1";
BA_ "SystemMessageLongSymbol" BO_ 2565867520 "VDMA_F008_Hydraulic_Pressure_Governor_Info";
BA_ "SystemMessageLongSymbol" BO_ 2565867776 "VDMA_F009_Vehicle_Dynamic_Stability_Contro";
BA_ "SystemMessageLongSymbol" BO_ 2565868288 "VDMA_F00B_Electronic_Steering_Control";
BA_ "SystemMessageLongSymbol" BO_ 2565868544 "VDMA_F00C_Electronic_Transmission_Controll";
BA_ "SystemMessageLongSymbol" BO_ 2565868800 "VDMA_F00D_Land_Leveling_System_Operational";
BA_ "SystemMessageLongSymbol" BO_ 2565869056 "VDMA_F00E_Aftertreatment_1_Intake_Gas_1";
BA_ "SystemMessageLongSymbol" BO_ 2565869312 "VDMA_F00F_Aftertreatment_1_Outlet_Gas_1";
BA_ "SystemMessageLongSymbol" BO_ 2565869568 "VDMA_F010_Aftertreatment_2_Intake_Gas_1";
BA_ "SystemMessageLongSymbol" BO_ 2565869824 "VDMA_F011_Aftertreatment_2_Outlet_Gas_1";
BA_ "SystemMessageLongSymbol" BO_ 2565870080 "VDMA_F012_Fifth_Wheel_Smart_Systems_1";
BA_ "SystemMessageLongSymbol" BO_ 2565870336 "VDMA_F013_Slope_Sensor_Information";
BA_ "SystemMessageLongSymbol" BO_ 2565870848 "VDMA_F015_Requested_Generator_Total_AC_Rea";
BA_ "SystemMessageLongSymbol" BO_ 2565871104 "VDMA_F016_Cylinder_Combustion_Status";
BA_ "SystemMessageLongSymbol" BO_ 2565872128 "VDMA_F01A_Engine_Throttle_Fuel_Actuator_Co";
BA_ "SystemMessageLongSymbol" BO_ 2565872384 "VDMA_F01B_General_Purpose_Message_1_7";
BA_ "SystemMessageLongSymbol" BO_ 2565872640 "VDMA_F01C_Requested_Generator_Average_Basi";
BA_ "SystemMessageLongSymbol" BO_ 2565872896 "VDMA_F01D_Steering_Angle_Sensor_Informatio";
BA_ "SystemMessageLongSymbol" BO_ 2565873408 "VDMA_F01F_Electronic_Brake_System_2_6";
BA_ "SystemMessageLongSymbol" BO_ 2565873664 "VDMA_F020_Electronic_Brake_System_2_5";
BA_ "SystemMessageLongSymbol" BO_ 2565873920 "VDMA_F021_Engine_Speed_Sensor_Information_";
BA_ "SystemMessageLongSymbol" BO_ 2565874432 "VDMA_F023_Aftertreatment_1_SCR_Dosing_Syst";
BA_ "SystemMessageLongSymbol" BO_ 2565874688 "VDMA_F024_Aftertreatment_1_SCR_Dosing_Syst";
BA_ "SystemMessageLongSymbol" BO_ 2565874944 "VDMA_F025_Aftertreatment_1_SCR_Ammonia_Inf";
BA_ "SystemMessageLongSymbol" BO_ 2565875200 "VDMA_F026_Aftertreatment_2_SCR_Dosing_Syst";
BA_ "SystemMessageLongSymbol" BO_ 2565875456 "VDMA_F027_Aftertreatment_2_SCR_Dosing_Syst";
